VERSION ""

NS_ :

BS_:
BU_: GW BMS GPEU PCU RPEU PDU EMS TMS RPEU OBC GPEU PDU ReservedID19 ReservedID20 BDC  TMS Tester

BO_ 1601 BMS_641: 64 BMS
 SG_ BMS_CellU32 : 503|16@0+ (0.0010000000,0.0000000000) [0.0000000000|18.0000000000] "V"  GW
 SG_ BMS_CellU31 : 487|16@0+ (0.0010000000,0.0000000000) [0.0000000000|18.0000000000] "V"  GW
 SG_ BMS_CellU30 : 471|16@0+ (0.0010000000,0.0000000000) [0.0000000000|18.0000000000] "V"  GW
 SG_ BMS_CellU29 : 455|16@0+ (0.0010000000,0.0000000000) [0.0000000000|18.0000000000] "V"  GW
 SG_ BMS_CellU28 : 439|16@0+ (0.0010000000,0.0000000000) [0.0000000000|18.0000000000] "V"  GW
 SG_ BMS_CellU27 : 423|16@0+ (0.0010000000,0.0000000000) [0.0000000000|18.0000000000] "V"  GW
 SG_ BMS_CellU26 : 407|16@0+ (0.0010000000,0.0000000000) [0.0000000000|18.0000000000] "V"  GW
 SG_ BMS_CellU25 : 391|16@0+ (0.0010000000,0.0000000000) [0.0000000000|18.0000000000] "V"  GW
 SG_ BMS_CellU24 : 375|16@0+ (0.0010000000,0.0000000000) [0.0000000000|18.0000000000] "V"  GW
 SG_ BMS_CellU23 : 359|16@0+ (0.0010000000,0.0000000000) [0.0000000000|18.0000000000] "V"  GW
 SG_ BMS_CellU22 : 343|16@0+ (0.0010000000,0.0000000000) [0.0000000000|18.0000000000] "V"  GW
 SG_ BMS_CellU21 : 327|16@0+ (0.0010000000,0.0000000000) [0.0000000000|18.0000000000] "V"  GW
 SG_ BMS_CellU20 : 311|16@0+ (0.0010000000,0.0000000000) [0.0000000000|18.0000000000] "V"  GW
 SG_ BMS_CellU19 : 295|16@0+ (0.0010000000,0.0000000000) [0.0000000000|18.0000000000] "V"  GW
 SG_ BMS_CellU18 : 279|16@0+ (0.0010000000,0.0000000000) [0.0000000000|18.0000000000] "V"  GW
 SG_ BMS_CellU17 : 263|16@0+ (0.0010000000,0.0000000000) [0.0000000000|18.0000000000] "V"  GW
 SG_ BMS_CellU16 : 247|16@0+ (0.0010000000,0.0000000000) [0.0000000000|18.0000000000] "V"  GW
 SG_ BMS_CellU15 : 231|16@0+ (0.0010000000,0.0000000000) [0.0000000000|18.0000000000] "V"  GW
 SG_ BMS_CellU14 : 215|16@0+ (0.0010000000,0.0000000000) [0.0000000000|18.0000000000] "V"  GW
 SG_ BMS_CellU13 : 199|16@0+ (0.0010000000,0.0000000000) [0.0000000000|18.0000000000] "V"  GW
 SG_ BMS_CellU9 : 135|16@0+ (0.0010000000,0.0000000000) [0.0000000000|18.0000000000] "V"  GW
 SG_ BMS_CellU12 : 183|16@0+ (0.0010000000,0.0000000000) [0.0000000000|18.0000000000] "V"  GW
 SG_ BMS_CellU11 : 167|16@0+ (0.0010000000,0.0000000000) [0.0000000000|18.0000000000] "V"  GW
 SG_ BMS_CellU10 : 151|16@0+ (0.0010000000,0.0000000000) [0.0000000000|18.0000000000] "V"  GW
 SG_ BMS_CellU8 : 119|16@0+ (0.0010000000,0.0000000000) [0.0000000000|18.0000000000] "V"  GW
 SG_ BMS_CellU7 : 103|16@0+ (0.0010000000,0.0000000000) [0.0000000000|18.0000000000] "V"  GW
 SG_ BMS_CellU6 : 87|16@0+ (0.0010000000,0.0000000000) [0.0000000000|18.0000000000] "V"  GW
 SG_ BMS_CellU5 : 71|16@0+ (0.0010000000,0.0000000000) [0.0000000000|18.0000000000] "V"  GW
 SG_ BMS_CellU4 : 55|16@0+ (0.0010000000,0.0000000000) [0.0000000000|18.0000000000] "V"  GW
 SG_ BMS_CellU3 : 39|16@0+ (0.0010000000,0.0000000000) [0.0000000000|18.0000000000] "V"  GW
 SG_ BMS_CellU2 : 23|16@0+ (0.0010000000,0.0000000000) [0.0000000000|18.0000000000] "V"  GW
 SG_ BMS_CellU1 : 7|16@0+ (0.0010000000,0.0000000000) [0.0000000000|18.0000000000] "V"  GW

BO_ 1609 BMS_649: 64 BMS
 SG_ BMS_CellU64 : 503|16@0+ (0.0010000000,0.0000000000) [0.0000000000|18.0000000000] "V"  GW
 SG_ BMS_CellU63 : 487|16@0+ (0.0010000000,0.0000000000) [0.0000000000|18.0000000000] "V"  GW
 SG_ BMS_CellU62 : 471|16@0+ (0.0010000000,0.0000000000) [0.0000000000|18.0000000000] "V"  GW
 SG_ BMS_CellU61 : 455|16@0+ (0.0010000000,0.0000000000) [0.0000000000|18.0000000000] "V"  GW
 SG_ BMS_CellU60 : 439|16@0+ (0.0010000000,0.0000000000) [0.0000000000|18.0000000000] "V"  GW
 SG_ BMS_CellU59 : 423|16@0+ (0.0010000000,0.0000000000) [0.0000000000|18.0000000000] "V"  GW
 SG_ BMS_CellU58 : 407|16@0+ (0.0010000000,0.0000000000) [0.0000000000|18.0000000000] "V"  GW
 SG_ BMS_CellU57 : 391|16@0+ (0.0010000000,0.0000000000) [0.0000000000|18.0000000000] "V"  GW
 SG_ BMS_CellU56 : 375|16@0+ (0.0010000000,0.0000000000) [0.0000000000|18.0000000000] "V"  GW
 SG_ BMS_CellU55 : 359|16@0+ (0.0010000000,0.0000000000) [0.0000000000|18.0000000000] "V"  GW
 SG_ BMS_CellU54 : 343|16@0+ (0.0010000000,0.0000000000) [0.0000000000|18.0000000000] "V"  GW
 SG_ BMS_CellU53 : 327|16@0+ (0.0010000000,0.0000000000) [0.0000000000|18.0000000000] "V"  GW
 SG_ BMS_CellU52 : 311|16@0+ (0.0010000000,0.0000000000) [0.0000000000|18.0000000000] "V"  GW
 SG_ BMS_CellU51 : 295|16@0+ (0.0010000000,0.0000000000) [0.0000000000|18.0000000000] "V"  GW
 SG_ BMS_CellU50 : 279|16@0+ (0.0010000000,0.0000000000) [0.0000000000|18.0000000000] "V"  GW
 SG_ BMS_CellU49 : 263|16@0+ (0.0010000000,0.0000000000) [0.0000000000|18.0000000000] "V"  GW
 SG_ BMS_CellU48 : 247|16@0+ (0.0010000000,0.0000000000) [0.0000000000|18.0000000000] "V"  GW
 SG_ BMS_CellU47 : 231|16@0+ (0.0010000000,0.0000000000) [0.0000000000|18.0000000000] "V"  GW
 SG_ BMS_CellU46 : 215|16@0+ (0.0010000000,0.0000000000) [0.0000000000|18.0000000000] "V"  GW
 SG_ BMS_CellU45 : 199|16@0+ (0.0010000000,0.0000000000) [0.0000000000|18.0000000000] "V"  GW
 SG_ BMS_CellU44 : 183|16@0+ (0.0010000000,0.0000000000) [0.0000000000|18.0000000000] "V"  GW
 SG_ BMS_CellU43 : 167|16@0+ (0.0010000000,0.0000000000) [0.0000000000|18.0000000000] "V"  GW
 SG_ BMS_CellU42 : 151|16@0+ (0.0010000000,0.0000000000) [0.0000000000|18.0000000000] "V"  GW
 SG_ BMS_CellU41 : 135|16@0+ (0.0010000000,0.0000000000) [0.0000000000|18.0000000000] "V"  GW
 SG_ BMS_CellU40 : 119|16@0+ (0.0010000000,0.0000000000) [0.0000000000|18.0000000000] "V"  GW
 SG_ BMS_CellU39 : 103|16@0+ (0.0010000000,0.0000000000) [0.0000000000|18.0000000000] "V"  GW
 SG_ BMS_CellU38 : 87|16@0+ (0.0010000000,0.0000000000) [0.0000000000|18.0000000000] "V"  GW
 SG_ BMS_CellU37 : 71|16@0+ (0.0010000000,0.0000000000) [0.0000000000|18.0000000000] "V"  GW
 SG_ BMS_CellU36 : 55|16@0+ (0.0010000000,0.0000000000) [0.0000000000|18.0000000000] "V"  GW
 SG_ BMS_CellU35 : 39|16@0+ (0.0010000000,0.0000000000) [0.0000000000|18.0000000000] "V"  GW
 SG_ BMS_CellU34 : 23|16@0+ (0.0010000000,0.0000000000) [0.0000000000|18.0000000000] "V"  GW
 SG_ BMS_CellU33 : 7|16@0+ (0.0010000000,0.0000000000) [0.0000000000|18.0000000000] "V"  GW

BO_ 1617 BMS_651: 64 BMS
 SG_ BMS_CellU96 : 503|16@0+ (0.0010000000,0.0000000000) [0.0000000000|18.0000000000] "V"  GW
 SG_ BMS_CellU95 : 487|16@0+ (0.0010000000,0.0000000000) [0.0000000000|18.0000000000] "V"  GW
 SG_ BMS_CellU94 : 471|16@0+ (0.0010000000,0.0000000000) [0.0000000000|18.0000000000] "V"  GW
 SG_ BMS_CellU93 : 455|16@0+ (0.0010000000,0.0000000000) [0.0000000000|18.0000000000] "V"  GW
 SG_ BMS_CellU92 : 439|16@0+ (0.0010000000,0.0000000000) [0.0000000000|18.0000000000] "V"  GW
 SG_ BMS_CellU91 : 423|16@0+ (0.0010000000,0.0000000000) [0.0000000000|18.0000000000] "V"  GW
 SG_ BMS_CellU90 : 407|16@0+ (0.0010000000,0.0000000000) [0.0000000000|18.0000000000] "V"  GW
 SG_ BMS_CellU89 : 391|16@0+ (0.0010000000,0.0000000000) [0.0000000000|18.0000000000] "V"  GW
 SG_ BMS_CellU88 : 375|16@0+ (0.0010000000,0.0000000000) [0.0000000000|18.0000000000] "V"  GW
 SG_ BMS_CellU87 : 359|16@0+ (0.0010000000,0.0000000000) [0.0000000000|18.0000000000] "V"  GW
 SG_ BMS_CellU86 : 343|16@0+ (0.0010000000,0.0000000000) [0.0000000000|18.0000000000] "V"  GW
 SG_ BMS_CellU85 : 327|16@0+ (0.0010000000,0.0000000000) [0.0000000000|18.0000000000] "V"  GW
 SG_ BMS_CellU84 : 311|16@0+ (0.0010000000,0.0000000000) [0.0000000000|18.0000000000] "V"  GW
 SG_ BMS_CellU83 : 295|16@0+ (0.0010000000,0.0000000000) [0.0000000000|18.0000000000] "V"  GW
 SG_ BMS_CellU82 : 279|16@0+ (0.0010000000,0.0000000000) [0.0000000000|18.0000000000] "V"  GW
 SG_ BMS_CellU81 : 263|16@0+ (0.0010000000,0.0000000000) [0.0000000000|18.0000000000] "V"  GW
 SG_ BMS_CellU80 : 247|16@0+ (0.0010000000,0.0000000000) [0.0000000000|18.0000000000] "V"  GW
 SG_ BMS_CellU79 : 231|16@0+ (0.0010000000,0.0000000000) [0.0000000000|18.0000000000] "V"  GW
 SG_ BMS_CellU78 : 215|16@0+ (0.0010000000,0.0000000000) [0.0000000000|18.0000000000] "V"  GW
 SG_ BMS_CellU77 : 199|16@0+ (0.0010000000,0.0000000000) [0.0000000000|18.0000000000] "V"  GW
 SG_ BMS_CellU76 : 183|16@0+ (0.0010000000,0.0000000000) [0.0000000000|18.0000000000] "V"  GW
 SG_ BMS_CellU75 : 167|16@0+ (0.0010000000,0.0000000000) [0.0000000000|18.0000000000] "V"  GW
 SG_ BMS_CellU74 : 151|16@0+ (0.0010000000,0.0000000000) [0.0000000000|18.0000000000] "V"  GW
 SG_ BMS_CellU73 : 135|16@0+ (0.0010000000,0.0000000000) [0.0000000000|18.0000000000] "V"  GW
 SG_ BMS_CellU72 : 119|16@0+ (0.0010000000,0.0000000000) [0.0000000000|18.0000000000] "V"  GW
 SG_ BMS_CellU71 : 103|16@0+ (0.0010000000,0.0000000000) [0.0000000000|18.0000000000] "V"  GW
 SG_ BMS_CellU70 : 87|16@0+ (0.0010000000,0.0000000000) [0.0000000000|18.0000000000] "V"  GW
 SG_ BMS_CellU69 : 71|16@0+ (0.0010000000,0.0000000000) [0.0000000000|18.0000000000] "V"  GW
 SG_ BMS_CellU68 : 55|16@0+ (0.0010000000,0.0000000000) [0.0000000000|18.0000000000] "V"  GW
 SG_ BMS_CellU67 : 39|16@0+ (0.0010000000,0.0000000000) [0.0000000000|18.0000000000] "V"  GW
 SG_ BMS_CellU66 : 23|16@0+ (0.0010000000,0.0000000000) [0.0000000000|18.0000000000] "V"  GW
 SG_ BMS_CellU65 : 7|16@0+ (0.0010000000,0.0000000000) [0.0000000000|18.0000000000] "V"  GW

BO_ 1653 BMS_675: 64 BMS
 SG_ BMS_ModT60 : 479|8@0+ (1.0000000000,-40.0000000000) [-40.0000000000|125.0000000000] "��"  GW
 SG_ BMS_ModT59 : 471|8@0+ (1.0000000000,-40.0000000000) [-40.0000000000|125.0000000000] "��"  GW
 SG_ BMS_ModT58 : 463|8@0+ (1.0000000000,-40.0000000000) [-40.0000000000|125.0000000000] "��"  GW
 SG_ BMS_ModT57 : 455|8@0+ (1.0000000000,-40.0000000000) [-40.0000000000|125.0000000000] "��"  GW
 SG_ BMS_ModT56 : 447|8@0+ (1.0000000000,-40.0000000000) [-40.0000000000|125.0000000000] "��"  GW
 SG_ BMS_ModT55 : 439|8@0+ (1.0000000000,-40.0000000000) [-40.0000000000|125.0000000000] "��"  GW
 SG_ BMS_ModT54 : 431|8@0+ (1.0000000000,-40.0000000000) [-40.0000000000|125.0000000000] "��"  GW
 SG_ BMS_ModT53 : 423|8@0+ (1.0000000000,-40.0000000000) [-40.0000000000|125.0000000000] "��"  GW
 SG_ BMS_ModT52 : 415|8@0+ (1.0000000000,-40.0000000000) [-40.0000000000|125.0000000000] "��"  GW
 SG_ BMS_ModT51 : 407|8@0+ (1.0000000000,-40.0000000000) [-40.0000000000|125.0000000000] "��"  GW
 SG_ BMS_ModT50 : 399|8@0+ (1.0000000000,-40.0000000000) [-40.0000000000|125.0000000000] "��"  GW
 SG_ BMS_ModT49 : 391|8@0+ (1.0000000000,-40.0000000000) [-40.0000000000|125.0000000000] "��"  GW
 SG_ BMS_ModT48 : 383|8@0+ (1.0000000000,-40.0000000000) [-40.0000000000|125.0000000000] "��"  GW
 SG_ BMS_ModT47 : 375|8@0+ (1.0000000000,-40.0000000000) [-40.0000000000|125.0000000000] "��"  GW
 SG_ BMS_ModT46 : 367|8@0+ (1.0000000000,-40.0000000000) [-40.0000000000|125.0000000000] "��"  GW
 SG_ BMS_ModT45 : 359|8@0+ (1.0000000000,-40.0000000000) [-40.0000000000|125.0000000000] "��"  GW
 SG_ BMS_ModT44 : 351|8@0+ (1.0000000000,-40.0000000000) [-40.0000000000|125.0000000000] "��"  GW
 SG_ BMS_ModT43 : 343|8@0+ (1.0000000000,-40.0000000000) [-40.0000000000|125.0000000000] "��"  GW
 SG_ BMS_ModT42 : 335|8@0+ (1.0000000000,-40.0000000000) [-40.0000000000|125.0000000000] "��"  GW
 SG_ BMS_ModT41 : 327|8@0+ (1.0000000000,-40.0000000000) [-40.0000000000|125.0000000000] "��"  GW
 SG_ BMS_ModT40 : 319|8@0+ (1.0000000000,-40.0000000000) [-40.0000000000|125.0000000000] "��"  GW
 SG_ BMS_ModT39 : 311|8@0+ (1.0000000000,-40.0000000000) [-40.0000000000|125.0000000000] "��"  GW
 SG_ BMS_ModT38 : 303|8@0+ (1.0000000000,-40.0000000000) [-40.0000000000|125.0000000000] "��"  GW
 SG_ BMS_ModT37 : 295|8@0+ (1.0000000000,-40.0000000000) [-40.0000000000|125.0000000000] "��"  GW
 SG_ BMS_ModT36 : 287|8@0+ (1.0000000000,-40.0000000000) [-40.0000000000|125.0000000000] "��"  GW
 SG_ BMS_ModT35 : 279|8@0+ (1.0000000000,-40.0000000000) [-40.0000000000|125.0000000000] "��"  GW
 SG_ BMS_ModT34 : 271|8@0+ (1.0000000000,-40.0000000000) [-40.0000000000|125.0000000000] "��"  GW
 SG_ BMS_ModT33 : 263|8@0+ (1.0000000000,-40.0000000000) [-40.0000000000|125.0000000000] "��"  GW
 SG_ BMS_ModT32 : 255|8@0+ (1.0000000000,-40.0000000000) [-40.0000000000|125.0000000000] "��"  GW
 SG_ BMS_ModT31 : 247|8@0+ (1.0000000000,-40.0000000000) [-40.0000000000|125.0000000000] "��"  GW
 SG_ BMS_ModT30 : 239|8@0+ (1.0000000000,-40.0000000000) [-40.0000000000|125.0000000000] "��"  GW
 SG_ BMS_ModT29 : 231|8@0+ (1.0000000000,-40.0000000000) [-40.0000000000|125.0000000000] "��"  GW
 SG_ BMS_ModT28 : 223|8@0+ (1.0000000000,-40.0000000000) [-40.0000000000|125.0000000000] "��"  GW
 SG_ BMS_ModT27 : 215|8@0+ (1.0000000000,-40.0000000000) [-40.0000000000|125.0000000000] "��"  GW
 SG_ BMS_ModT26 : 207|8@0+ (1.0000000000,-40.0000000000) [-40.0000000000|125.0000000000] "��"  GW
 SG_ BMS_ModT25 : 199|8@0+ (1.0000000000,-40.0000000000) [-40.0000000000|125.0000000000] "��"  GW
 SG_ BMS_ModT24 : 191|8@0+ (1.0000000000,-40.0000000000) [-40.0000000000|125.0000000000] "��"  GW
 SG_ BMS_ModT23 : 183|8@0+ (1.0000000000,-40.0000000000) [-40.0000000000|125.0000000000] "��"  GW
 SG_ BMS_ModT22 : 175|8@0+ (1.0000000000,-40.0000000000) [-40.0000000000|125.0000000000] "��"  GW
 SG_ BMS_ModT21 : 167|8@0+ (1.0000000000,-40.0000000000) [-40.0000000000|125.0000000000] "��"  GW
 SG_ BMS_ModT20 : 159|8@0+ (1.0000000000,-40.0000000000) [-40.0000000000|125.0000000000] "��"  GW
 SG_ BMS_ModT19 : 151|8@0+ (1.0000000000,-40.0000000000) [-40.0000000000|125.0000000000] "��"  GW
 SG_ BMS_ModT18 : 143|8@0+ (1.0000000000,-40.0000000000) [-40.0000000000|125.0000000000] "��"  GW
 SG_ BMS_ModT17 : 135|8@0+ (1.0000000000,-40.0000000000) [-40.0000000000|125.0000000000] "��"  GW
 SG_ BMS_ModT9 : 71|8@0+ (1.0000000000,-40.0000000000) [-40.0000000000|125.0000000000] "��"  GW
 SG_ BMS_ModT16 : 127|8@0+ (1.0000000000,-40.0000000000) [-40.0000000000|125.0000000000] "��"  GW
 SG_ BMS_ModT15 : 119|8@0+ (1.0000000000,-40.0000000000) [-40.0000000000|125.0000000000] "��"  GW
 SG_ BMS_ModT14 : 111|8@0+ (1.0000000000,-40.0000000000) [-40.0000000000|125.0000000000] "��"  GW
 SG_ BMS_ModT13 : 103|8@0+ (1.0000000000,-40.0000000000) [-40.0000000000|125.0000000000] "��"  GW
 SG_ BMS_ModT12 : 95|8@0+ (1.0000000000,-40.0000000000) [-40.0000000000|125.0000000000] "��"  GW
 SG_ BMS_ModT11 : 87|8@0+ (1.0000000000,-40.0000000000) [-40.0000000000|125.0000000000] "��"  GW
 SG_ BMS_ModT10 : 79|8@0+ (1.0000000000,-40.0000000000) [-40.0000000000|125.0000000000] "��"  GW
 SG_ BMS_ModT8 : 63|8@0+ (1.0000000000,-40.0000000000) [-40.0000000000|125.0000000000] "��"  GW
 SG_ BMS_ModT7 : 55|8@0+ (1.0000000000,-40.0000000000) [-40.0000000000|125.0000000000] "��"  GW
 SG_ BMS_ModT6 : 47|8@0+ (1.0000000000,-40.0000000000) [-40.0000000000|125.0000000000] "��"  GW
 SG_ BMS_ModT5 : 39|8@0+ (1.0000000000,-40.0000000000) [-40.0000000000|125.0000000000] "��"  GW
 SG_ BMS_ModT4 : 31|8@0+ (1.0000000000,-40.0000000000) [-40.0000000000|125.0000000000] "��"  GW
 SG_ BMS_ModT3 : 23|8@0+ (1.0000000000,-40.0000000000) [-40.0000000000|125.0000000000] "��"  GW
 SG_ BMS_ModT2 : 15|8@0+ (1.0000000000,-40.0000000000) [-40.0000000000|125.0000000000] "��"  GW
 SG_ BMS_ModT1 : 7|8@0+ (1.0000000000,-40.0000000000) [-40.0000000000|125.0000000000] "��"  GW

BO_ 378 GW_17A: 64 GW
 SG_ Wheel_Speed_RR_Data : 351|13@0+ (0.0562500000,0.0000000000) [0.0000000000|360.0000000000] "km/h"  RPEU
 SG_ Wheel_Speed_RL_Valid_Data : 354|1@0+ (1.0000000000,0.0000000000) [0.0000000000|1.0000000000] ""  RPEU
 SG_ Wheel_Speed_RL_Data : 353|13@0+ (0.0562500000,0.0000000000) [0.0000000000|360.0000000000] "km/h"  RPEU
 SG_ Wheel_Speed_RR_Valid_Data : 372|1@0+ (1.0000000000,0.0000000000) [0.0000000000|1.0000000000] ""  RPEU
 SG_ ESP_VDCActive : 245|1@0+ (1.0000000000,0.0000000000) [0.0000000000|1.0000000000] ""  RPEU
 SG_ ESP_TCSActive : 244|1@0+ (1.0000000000,0.0000000000) [0.0000000000|1.0000000000] ""  RPEU
 SG_ ESP_RollingCounter_17A : 491|4@0+ (1.0000000000,0.0000000000) [0.0000000000|15.0000000000] ""  PCU,PDCU
 SG_ ESP_CRCCheck_17A : 503|16@0+ (1.0000000000,0.0000000000) [0.0000000000|65535.0000000000] ""  PCU,PDCU
 SG_ ESP_ElectricBoostFailStatus : 54|2@0+ (1.0000000000,0.0000000000) [0.0000000000|3.0000000000] "" Vector__XXX
 SG_ ESP_MbRegenTarWhlTotalQlfr : 293|2@0+ (1.0000000000,0.0000000000) [0.0000000000|3.0000000000] ""  PCU,PDCU
 SG_ ESP_MbRegenTarWhlTotal : 291|16@0+ (1.0000000000,-32768.0000000000) [-32768.0000000000|32767.0000000000] "Nm"  PCU,PDCU
 SG_ ESP_RollerbenchType : 80|3@0+ (1.0000000000,0.0000000000) [0.0000000000|7.0000000000] ""  PCU,PDCU
 SG_ IBCU_BrakeFluid_Warning : 27|2@0+ (1.0000000000,0.0000000000) [0.0000000000|3.0000000000] "" Vector__XXX
 SG_ ESP_VehicleSpeedValid2 : 271|2@0+ (1.0000000000,0.0000000000) [0.0000000000|2.0000000000] "" Vector__XXX
 SG_ ESP_VehicleSpeedValid : 37|1@0+ (1.0000000000,0.0000000000) [0.0000000000|1.0000000000] ""  PCU,PDCU,DPEU,GPEU,OBC
 SG_ ESP_VehicleSpeed2 : 263|8@0+ (0.4000000000,0.0000000000) [0.0000000000|100.0000000000] "m/s" Vector__XXX
 SG_ ESP_VehicleSpeed : 36|13@0+ (0.0562500000,0.0000000000) [0.0000000000|360.0000000000] "km/h"  PCU,PDCU,OBC,DPEU,GPEU,BMS
 SG_ ESP_TqDecSlowwhlRear : 215|15@0+ (1.0000000000,-5400.0000000000) [-5400.0000000000|12000.0000000000] "Nm"  PCU,PDCU,RPEU
 SG_ ESP_TqDecSlowwhlFront : 136|15@0+ (1.0000000000,-5400.0000000000) [-5400.0000000000|12000.0000000000] "Nm"  PCU,PDCU
 SG_ ESP_TqDecFastwhlFront : 135|15@0+ (1.0000000000,-5400.0000000000) [-5400.0000000000|12000.0000000000] "Nm"  PCU,PDCU,DPEU
 SG_ ESP_TorqIncwhlRear : 199|15@0+ (1.0000000000,-5400.0000000000) [-5400.0000000000|12000.0000000000] "Nm"  PCU,PDCU,RPEU
 SG_ ESP_TorqIncwhlFront : 15|15@0+ (1.0000000000,-5400.0000000000) [-5400.0000000000|12000.0000000000] "Nm"  PCU,PDCU,DPEU
 SG_ ESP_TCSFailStatus : 4|1@0+ (1.0000000000,0.0000000000) [0.0000000000|1.0000000000] ""  PCU,PDCU,RPEU
 SG_ ESP_RollingCounter_1DF : 371|4@0+ (1.0000000000,0.0000000000) [0.0000000000|15.0000000000] "" Vector__XXX
 SG_ ESP_RollingCounter_1C8 : 243|4@0+ (1.0000000000,0.0000000000) [0.0000000000|15.0000000000] ""  PCU,PDCU
 SG_ ESP_RollingCounter_1AC : 179|4@0+ (1.0000000000,0.0000000000) [0.0000000000|15.0000000000] ""  PCU,PDCU
 SG_ ESP_RollingCounter_197 : 115|4@0+ (1.0000000000,0.0000000000) [0.0000000000|15.0000000000] ""  PCU,PDCU
 SG_ ESP_RollingCounter_187 : 51|4@0+ (1.0000000000,0.0000000000) [0.0000000000|15.0000000000] ""  PCU,PDCU
 SG_ ESP_pMcVirtual_Q : 333|2@0+ (1.0000000000,0.0000000000) [0.0000000000|2.0000000000] ""  PCU,PDCU
 SG_ ESP_pMcVirtual : 327|10@0+ (1.0000000000,0.0000000000) [0.0000000000|250.0000000000] "bar"  PCU,PDCU
 SG_ ESP_MbRegenTarWhlRearQlfr : 247|2@0+ (1.0000000000,0.0000000000) [0.0000000000|2.0000000000] ""  PCU,PDCU
 SG_ ESP_MbRegenTarWhlRear : 231|16@0+ (1.0000000000,-32768.0000000000) [-32768.0000000000|0.0000000000] "Nm"  PCU,PDCU
 SG_ ESP_MbRegenTarWhlFrontQlfr : 168|2@0+ (1.0000000000,0.0000000000) [0.0000000000|2.0000000000] ""  PCU,PDCU
 SG_ ESP_MbRegenTarWhlFront : 152|16@0+ (1.0000000000,-32768.0000000000) [-32768.0000000000|32767.0000000000] "Nm"  PCU,PDCU
 SG_ ESP_GearHoldRequestValid : 5|1@0+ (1.0000000000,0.0000000000) [0.0000000000|1.0000000000] ""  PCU,PDCU
 SG_ ESP_GearHoldRequest : 6|1@0+ (1.0000000000,0.0000000000) [0.0000000000|1.0000000000] ""  PCU,PDCU
 SG_ ESP_ESPFunctionStatus : 1|1@0+ (1.0000000000,0.0000000000) [0.0000000000|1.0000000000] ""  PCU,PDCU,RPEU
 SG_ ESP_ESPActiveStatus : 0|1@0+ (1.0000000000,0.0000000000) [0.0000000000|1.0000000000] ""  PCU,PDCU,RPEU
 SG_ ESP_EngTorqIncRearActive : 200|1@0+ (1.0000000000,0.0000000000) [0.0000000000|1.0000000000] ""  PCU,PDCU,RPEU
 SG_ ESP_EngTorqIncFrontActive : 38|1@0+ (1.0000000000,0.0000000000) [0.0000000000|1.0000000000] ""  PCU,PDCU,EMS,DPEU
 SG_ ESP_EngTorqDecRearActive : 216|1@0+ (1.0000000000,0.0000000000) [0.0000000000|1.0000000000] ""  PCU,PDCU,RPEU
 SG_ ESP_EngTorqDecFrontActive : 153|1@0+ (1.0000000000,0.0000000000) [0.0000000000|1.0000000000] ""  PCU,PDCU,DPEU
 SG_ ESP_EBDFailStatus : 2|1@0+ (1.0000000000,0.0000000000) [0.0000000000|1.0000000000] ""  PCU,PDCU
 SG_ ESP_CRCCheck_1DF : 383|8@0+ (1.0000000000,0.0000000000) [0.0000000000|255.0000000000] "" Vector__XXX
 SG_ ESP_CRCCheck_1C8 : 255|8@0+ (1.0000000000,0.0000000000) [0.0000000000|255.0000000000] ""  PCU,PDCU
 SG_ ESP_CRCCheck_1AC : 191|8@0+ (1.0000000000,0.0000000000) [0.0000000000|255.0000000000] ""  PCU,PDCU
 SG_ ESP_CRCCheck_197 : 127|8@0+ (1.0000000000,0.0000000000) [0.0000000000|255.0000000000] ""  PCU,PDCU
 SG_ ESP_CRCCheck_187 : 63|8@0+ (1.0000000000,0.0000000000) [0.0000000000|255.0000000000] ""  PCU,PDCU
 SG_ ESP_ADBF_Active : 52|1@0+ (1.0000000000,0.0000000000) [0.0000000000|1.0000000000] ""  PCU,PDCU
 SG_ ESP_ABSFailStatus : 3|1@0+ (1.0000000000,0.0000000000) [0.0000000000|1.0000000000] ""  PCU,PDCU
 SG_ ESP_ABSActiveStatus : 7|1@0+ (1.0000000000,0.0000000000) [0.0000000000|1.0000000000] ""  PCU,PDCU
 SG_ EPBi_MILReq : 55|1@0+ (1.0000000000,0.0000000000) [0.0000000000|1.0000000000] ""  PCU,PDCU
 SG_ EPBi_ClearDiagnosticInfo : 25|2@0+ (1.0000000000,0.0000000000) [0.0000000000|3.0000000000] "" Vector__XXX

BO_ 380 EMS_17C: 32 EMS
 SG_ EMS_S58XGAPS : 231|6@0+ (1.0000000000,0.0000000000) [1.0000000000|63.0000000000] ""  EMS,PDCU,GW,DPEU,GPEU
 SG_ EMS_AntiJerkActive : 53|1@0+ (1.0000000000,0.0000000000) [0.0000000000|1.0000000000] ""  EMS,PDCU,PCU,GW
 SG_ EMS_RollingCounter_17C : 235|4@0+ (1.0000000000,0.0000000000) [0.0000000000|15.0000000000] ""  GW,EMS,PDCU,PCU
 SG_ EMS_CRCCheck_17C : 247|16@0+ (1.0000000000,0.0000000000) [0.0000000000|65535.0000000000] ""  GW,EMS,PDCU,PCU
 SG_ EMS_RollingCounter_1B7 : 179|4@0+ (1.0000000000,0.0000000000) [0.0000000000|15.0000000000] ""  EMS,PDCU,PCU
 SG_ EMS_RngMod_trqCrSSetMinAvl : 153|10@0+ (1.0000000000,-350.0000000000) [-350.0000000000|400.0000000000] "Nm"  EMS,PDCU,PCU
 SG_ EMS_RngMod_trqCrSSetMaxAvl : 147|10@0+ (1.0000000000,-350.0000000000) [-350.0000000000|400.0000000000] "Nm"  EMS,PDCU,PCU
 SG_ EMS_RngMod_trqCrSLeadMinAvl : 141|10@0+ (1.0000000000,-350.0000000000) [-350.0000000000|400.0000000000] "Nm"  EMS,PDCU,PCU
 SG_ EMS_RngMod_trqCrSLeadMaxAvl : 135|10@0+ (1.0000000000,-350.0000000000) [-350.0000000000|400.0000000000] "Nm"  EMS,PDCU,PCU
 SG_ EMS_EngIdleTqFlywhMin : 175|10@0+ (1.0000000000,-350.0000000000) [-350.0000000000|400.0000000000] "Nm"  EMS,PDCU,PCU
 SG_ EMS_CRCCheck_1B7 : 191|8@0+ (1.0000000000,0.0000000000) [0.0000000000|255.0000000000] ""  EMS,PDCU,PCU
 SG_ EMS_RollingCounter_194 : 115|4@0+ (1.0000000000,0.0000000000) [0.0000000000|15.0000000000] ""  EMS,PDCU,PCU,GW
 SG_ EMS_IGNKL15Posn : 117|1@0+ (1.0000000000,0.0000000000) [0.0000000000|1.0000000000] ""  EMS,PDCU,GW
 SG_ EMS_IdleCtrlSts : 86|1@0+ (1.0000000000,0.0000000000) [0.0000000000|1.0000000000] ""  EMS,PDCU,PCU,GW,DPEU,GPEU
 SG_ EMS_EngTqFlywhFailr : 104|1@0+ (1.0000000000,0.0000000000) [0.0000000000|1.0000000000] ""  EMS,PDCU,PCU,GW,DPEU,GPEU
 SG_ EMS_EngTqFlywh : 88|16@0+ (0.0200000000,-350.0000000000) [-350.0000000000|400.0000000000] "Nm"  EMS,PDCU,PCU,GW,DPEU,GPEU
 SG_ EMS_EngSts : 119|2@0+ (1.0000000000,0.0000000000) [0.0000000000|3.0000000000] ""  EMS,PDCU,GW,PCU,DPEU,GPEU,TMS,BDC
 SG_ EMS_EngStrtSuccess : 90|1@0+ (1.0000000000,0.0000000000) [0.0000000000|1.0000000000] ""  EMS,PDCU,PCU,GW
 SG_ EMS_EngStopInhb : 93|3@0+ (1.0000000000,0.0000000000) [0.0000000000|3.0000000000] ""  EMS,PDCU,PCU,GW
 SG_ EMS_EngSpdErr : 71|1@0+ (1.0000000000,0.0000000000) [0.0000000000|1.0000000000] ""  EMS,PDCU,PCU,GW,BMS,RPEU,TMS,BDC
 SG_ EMS_EngSpd : 70|16@0+ (0.2500000000,0.0000000000) [0.0000000000|16383.5000000000] "Rpm"  EMS,PDCU,PCU,GW,BMS,DPEU,GPEU,RPEU,OBC,TMS,BDC
 SG_ EMS_EngRunReq : 85|3@0+ (1.0000000000,0.0000000000) [0.0000000000|3.0000000000] ""  EMS,PDCU,PCU,GW
 SG_ EMS_EngFuPumpSts : 95|2@0+ (1.0000000000,0.0000000000) [0.0000000000|3.0000000000] ""  EMS,PDCU,PCU,GW
 SG_ EMS_EngFuCutOff : 89|1@0+ (1.0000000000,0.0000000000) [0.0000000000|1.0000000000] ""  EMS,PDCU,PCU,GW
 SG_ EMS_CRCCheck_194 : 127|8@0+ (1.0000000000,0.0000000000) [0.0000000000|255.0000000000] ""  EMS,PDCU,PCU,GW
 SG_ EMS_RollingCounter_186 : 51|4@0+ (1.0000000000,0.0000000000) [0.0000000000|15.0000000000] ""  EMS,PDCU,PCU,GW
 SG_ EMS_EngTqLimitedFlag : 52|1@0+ (1.0000000000,0.0000000000) [0.0000000000|1.0000000000] ""  EMS,PDCU,PCU,GW
 SG_ EMS_RngMod_trqCrSLimtSts : 32|1@0+ (1.0000000000,0.0000000000) [0.0000000000|1.0000000000] ""  EMS,PDCU,PCU,GW
 SG_ EMS_RngMod_trqCrSLeadMin : 26|10@0+ (1.0000000000,-350.0000000000) [-350.0000000000|400.0000000000] "Nm"  EMS,PDCU,PCU,GW
 SG_ EMS_InterCoolerMotLopPumpSpdReq : 13|7@0+ (1.0000000000,0.0000000000) [0.0000000000|100.0000000000] "%"  EMS,PDCU,GW,TMS,IBCMR,BDC
 SG_ EMS_IdleSpdRef : 7|10@0+ (10.0000000000,0.0000000000) [0.0000000000|10220.0000000000] "rpm"  EMS,PDCU,PCU,GW
 SG_ EMS_EngTqFric : 22|12@0+ (0.1000000000,0.0000000000) [0.0000000000|409.4000000000] "Nm"  EMS,PDCU,PCU,GW
 SG_ EMS_EngIdleTqFlywh : 47|10@0+ (1.0000000000,-350.0000000000) [-350.0000000000|400.0000000000] "Nm"  EMS,PDCU,PCU,GW
 SG_ EMS_CRCCheck_186 : 63|8@0+ (1.0000000000,0.0000000000) [0.0000000000|255.0000000000] ""  EMS,PDCU,PCU,GW

BO_ 381 PCU_17D: 64 PCU
 SG_ PCU_MbRegenWhlTotalVld : 476|1@0+ (1.0000000000,0.0000000000) [0.0000000000|1.0000000000] ""  GW,PCU,PDCU
 SG_ PCU_MbRegenWhlTotal : 475|16@0+ (1.0000000000,-32768.0000000000) [-32768.0000000000|32767.0000000000] "Nm"  GW,PCU,PDCU
 SG_ PCU_VehWhlReqTqVld : 456|1@0+ (1.0000000000,0.0000000000) [0.0000000000|1.0000000000] ""  GW,PCU,PDCU
 SG_ PCU_VehWhlReqTq : 455|15@0+ (1.0000000000,-5400.0000000000) [-5400.0000000000|12000.0000000000] "Nm"  GW,PCU,PDCU
 SG_ PCU_ReWhlReqTqVld : 468|1@0+ (1.0000000000,0.0000000000) [0.0000000000|1.0000000000] ""  GW,PCU,PDCU
 SG_ PCU_FrntWhlReqTqVld : 469|1@0+ (1.0000000000,0.0000000000) [0.0000000000|1.0000000000] ""  GW,PCU,PDCU
 SG_ PCU_ReWhlActTqVld : 470|1@0+ (1.0000000000,0.0000000000) [0.0000000000|1.0000000000] ""  GW,PCU,PDCU
 SG_ PCU_FrntWhlActTqVld : 471|1@0+ (1.0000000000,0.0000000000) [0.0000000000|1.0000000000] ""  GW,PCU,PDCU
 SG_ PCU_MbRegenMaxRearWhlVld : 375|1@0+ (1.0000000000,0.0000000000) [0.0000000000|1.0000000000] ""  PCU,PDCU,GW
 SG_ PCU_EngTarSpdReqVld : 224|1@0+ (1.0000000000,0.0000000000) [0.0000000000|1.0000000000] ""  PCU,PDCU,EMS
 SG_ PCU_RollingCounter_17D : 491|4@0+ (1.0000000000,0.0000000000) [0.0000000000|15.0000000000] ""  GW,PCU,PDCU,EMS,BMS
 SG_ PCU_CRCCheck_17D : 503|16@0+ (1.0000000000,0.0000000000) [0.0000000000|65535.0000000000] ""  GW,PCU,PDCU,EMS,BMS
 SG_ PCU_RollingCounter_1C4 : 435|4@0+ (1.0000000000,0.0000000000) [0.0000000000|15.0000000000] ""  GW,PCU,PDCU
 SG_ PCU_RearMotSts : 408|1@0+ (1.0000000000,0.0000000000) [0.0000000000|1.0000000000] ""  GW,PCU,PDCU
 SG_ PCU_PwrIndcdRealTqRearWhl : 391|15@0+ (1.0000000000,-5400.0000000000) [-5400.0000000000|12000.0000000000] "Nm"  GW,PCU,PDCU,BDC
 SG_ PCU_PwrIndcdDrvrReqTqWhlRear : 392|15@0+ (1.0000000000,-5400.0000000000) [-5400.0000000000|12000.0000000000] "Nm"  GW,PCU,PDCU
 SG_ PCU_ESPTqReqAvlRear : 409|1@0+ (1.0000000000,0.0000000000) [0.0000000000|1.0000000000] ""  GW,PCU,PDCU
 SG_ PCU_CRCCheck_1C4 : 447|8@0+ (1.0000000000,0.0000000000) [0.0000000000|255.0000000000] ""  GW,PCU,PDCU
 SG_ PCU_RollingCounter_1BE : 371|4@0+ (1.0000000000,0.0000000000) [0.0000000000|15.0000000000] ""  GW,PCU,PDCU
 SG_ PCU_MbRegenWhlRear : 343|16@0+ (1.0000000000,-32768.0000000000) [-32768.0000000000|32767.0000000000] "Nm"  GW,PCU,PDCU
 SG_ PCU_MbRegenMaxWhlTotal : 327|16@0+ (1.0000000000,-32768.0000000000) [-32768.0000000000|32767.0000000000] "Nm"  GW,PCU,PDCU
 SG_ PCU_MbRegenMaxRearWhl : 359|16@0+ (1.0000000000,-32768.0000000000) [-32768.0000000000|32767.0000000000] "Nm"  GW,PCU,PDCU
 SG_ PCU_CRCCheck_1BE : 383|8@0+ (1.0000000000,0.0000000000) [0.0000000000|255.0000000000] ""  GW,PCU,PDCU
 SG_ PCU_PwrTrainSts : 311|2@0+ (1.0000000000,0.0000000000) [0.0000000000|3.0000000000] ""  GW,PCU,PDCU,EMS,TMS,BDC
 SG_ PCU_BrkPedlSts : 291|2@0+ (1.0000000000,0.0000000000) [0.0000000000|3.0000000000] ""  GW,PCU,PDCU,BDC
 SG_ PCU_RollingCounter_1A6 : 307|4@0+ (1.0000000000,0.0000000000) [0.0000000000|15.0000000000] ""  GW,PCU,PDCU
 SG_ PCU_MbRegenWhlFront : 263|16@0+ (1.0000000000,-32768.0000000000) [-32768.0000000000|32767.0000000000] "Nm"  GW,PCU,PDCU
 SG_ PCU_MbRegenMaxWhlQlfr : 293|2@0+ (1.0000000000,0.0000000000) [0.0000000000|2.0000000000] ""  GW,PCU,PDCU
 SG_ PCU_MbRegenMaxFrontWhlVld : 294|1@0+ (1.0000000000,0.0000000000) [0.0000000000|1.0000000000] ""  GW,PCU,PDCU
 SG_ PCU_MbRegenMaxFrontWhl : 279|16@0+ (1.0000000000,-32768.0000000000) [-32768.0000000000|32767.0000000000] "Nm"  GW,PCU,PDCU
 SG_ PCU_CRCCheck_1A6 : 319|8@0+ (1.0000000000,0.0000000000) [0.0000000000|255.0000000000] ""  GW,PCU,PDCU
 SG_ PCU_APATorqRequestAvailable : 289|1@0+ (1.0000000000,0.0000000000) [0.0000000000|1.0000000000] ""  PCU,PDCU,GW,BDC
 SG_ PCU_APARequestEnable : 309|2@0+ (1.0000000000,0.0000000000) [0.0000000000|3.0000000000] ""  PCU,PDCU,GW,BDC
 SG_ PCU_AccPedlVld : 288|1@0+ (1.0000000000,0.0000000000) [0.0000000000|1.0000000000] ""  GW,PCU,PDCU,BDC
 SG_ PCU_AccPedl : 303|8@0+ (0.3920000000,0.0000000000) [0.0000000000|99.9600000000] "pct"  GW,PCU,PDCU,BDC
 SG_ PCU_StartStopActiveVld : 234|1@0+ (1.0000000000,0.0000000000) [0.0000000000|1.0000000000] ""  PCU,PDCU,GW
 SG_ PCU_StartStopActive : 235|1@0+ (1.0000000000,0.0000000000) [0.0000000000|1.0000000000] ""  PCU,PDCU,GW
 SG_ PCU_RollingCounter_211 : 243|4@0+ (1.0000000000,0.0000000000) [0.0000000000|15.0000000000] ""  PCU,PDCU,GW
 SG_ PCU_RearMotStsVld : 236|1@0+ (1.0000000000,0.0000000000) [0.0000000000|1.0000000000] ""  PCU,PDCU,GW
 SG_ PCU_QECACC : 230|2@0+ (1.0000000000,0.0000000000) [0.0000000000|3.0000000000] ""  PCU,PDCU,GW
 SG_ PCU_PwrIndcdRealTqWhlFailr : 225|1@0+ (1.0000000000,0.0000000000) [0.0000000000|1.0000000000] ""  PCU,PDCU,GW
 SG_ PCU_PwrIndcdRealTqFrontWhl : 199|15@0+ (1.0000000000,-5400.0000000000) [-5400.0000000000|12000.0000000000] "Nm"  PCU,PDCU,GW,BDC
 SG_ PCU_PwrIndcdDrvrReqTqWhlFront : 200|15@0+ (1.0000000000,-5400.0000000000) [-5400.0000000000|12000.0000000000] "Nm"  PCU,PDCU,GW
 SG_ PCU_FrontMotStsVld : 239|1@0+ (1.0000000000,0.0000000000) [0.0000000000|1.0000000000] ""  PCU,PDCU,GW
 SG_ PCU_FrontMotSts : 217|1@0+ (1.0000000000,0.0000000000) [0.0000000000|1.0000000000] ""  PCU,PDCU,GW
 SG_ PCU_ESPTqReqAvlFront : 216|1@0+ (1.0000000000,0.0000000000) [0.0000000000|1.0000000000] ""  PCU,PDCU,GW
 SG_ PCU_EngStsVld : 238|1@0+ (1.0000000000,0.0000000000) [0.0000000000|1.0000000000] ""  PCU,PDCU,GW
 SG_ PCU_EngSts : 227|1@0+ (1.0000000000,0.0000000000) [0.0000000000|1.0000000000] ""  PCU,PDCU,GW
 SG_ PCU_EngClutchStsVld : 237|1@0+ (1.0000000000,0.0000000000) [0.0000000000|1.0000000000] ""  PCU,PDCU,GW
 SG_ PCU_EngClutchSts : 226|1@0+ (1.0000000000,0.0000000000) [0.0000000000|1.0000000000] ""  PCU,PDCU,GW
 SG_ PCU_ECGPOvrd : 231|1@0+ (1.0000000000,0.0000000000) [0.0000000000|1.0000000000] ""  PCU,PDCU,GW
 SG_ PCU_CRCCheck_211 : 255|8@0+ (1.0000000000,0.0000000000) [0.0000000000|255.0000000000] ""  PCU,PDCU,GW
 SG_ PCU_AccReqPossible : 228|1@0+ (1.0000000000,0.0000000000) [0.0000000000|1.0000000000] ""  PCU,PDCU,GW
 SG_ RGearbox_ActualDrivingGear : 110|2@0+ (1.0000000000,0.0000000000) [0.0000000000|3.0000000000] ""  GW,PCU,PDCU
 SG_ PCU_TrsmTarIdleSpdReq : 108|9@0+ (10.0000000000,0.0000000000) [0.0000000000|5110.0000000000] "rpm"  PCU,PDCU,GW
 SG_ PCU_TarGearReqValid : 111|1@0+ (1.0000000000,0.0000000000) [0.0000000000|1.0000000000] ""  GW,PCU,PDCU
 SG_ PCU_TarGearReq : 99|4@0+ (1.0000000000,0.0000000000) [0.0000000000|15.0000000000] ""  GW,PCU,PDCU,EMS
 SG_ PCU_SpdCtrlModSelect : 88|2@0+ (1.0000000000,0.0000000000) [0.0000000000|3.0000000000] ""  PCU,PDCU,EMS,GW
 SG_ PCU_RollingCounter_1C6 : 115|4@0+ (1.0000000000,0.0000000000) [0.0000000000|15.0000000000] ""  PCU,PDCU,EMS,GW
 SG_ PCU_RealAccPedlVld : 79|1@0+ (1.0000000000,0.0000000000) [0.0000000000|1.0000000000] ""  PCU,PDCU,EMS,GW,BDC
 SG_ PCU_RealAccPedl : 71|8@0+ (0.3920000000,0.0000000000) [0.0000000000|99.9600000000] "%"  PCU,PDCU,EMS,GW,BDC
 SG_ PCU_MILReq : 100|1@0+ (1.0000000000,0.0000000000) [0.0000000000|1.0000000000] ""  PCU,PDCU,EMS,GW
 SG_ PCU_K3CluSts : 78|1@0+ (1.0000000000,0.0000000000) [0.0000000000|1.0000000000] ""  PCU,PDCU,EMS,GW
 SG_ PCU_FlywhTqTransLoadActInvld : 77|1@0+ (1.0000000000,0.0000000000) [0.0000000000|1.0000000000] ""  PCU,PDCU,EMS,GW
 SG_ PCU_FlywhTqTransLoadAct : 76|8@0+ (1.0000000000,0.0000000000) [0.0000000000|254.0000000000] "Nm"  PCU,PDCU,EMS,GW
 SG_ PCU_EngTarIdleSpdReq : 84|9@0+ (10.0000000000,0.0000000000) [0.0000000000|5110.0000000000] "rpm"  PCU,PDCU,EMS,GW
 SG_ PCU_EngStrtMod : 91|3@0+ (1.0000000000,0.0000000000) [0.0000000000|7.0000000000] ""  PCU,PDCU,EMS,GW
 SG_ PCU_CRCCheck_1C6 : 127|8@0+ (1.0000000000,0.0000000000) [0.0000000000|255.0000000000] ""  PCU,PDCU,EMS,GW
 SG_ PCU_ClrDiagcInfo : 102|2@0+ (1.0000000000,0.0000000000) [0.0000000000|3.0000000000] ""  PCU,PDCU,EMS,GW
 SG_ PCU_StrtTrqCtl : 182|1@0+ (1.0000000000,0.0000000000) [0.0000000000|1.0000000000] ""  PCU,EMS,PDCU
 SG_ PCU_StrtInhb : 183|1@0+ (1.0000000000,0.0000000000) [0.0000000000|1.0000000000] ""  PCU,EMS,PDCU
 SG_ PCU_RollingCounter_1E1 : 179|4@0+ (1.0000000000,0.0000000000) [0.0000000000|15.0000000000] ""  PCU,EMS,PDCU
 SG_ PCU_PtStsChrgCrp : 135|2@0+ (1.0000000000,0.0000000000) [0.0000000000|3.0000000000] ""  PCU,EMS,PDCU
 SG_ PCU_FuCutOffReq : 153|1@0+ (1.0000000000,0.0000000000) [0.0000000000|1.0000000000] ""  PCU,EMS,PDCU
 SG_ PCU_EngIgnAgIntvEnbl : 169|1@0+ (1.0000000000,0.0000000000) [0.0000000000|1.0000000000] ""  PCU,EMS,PDCU
 SG_ PCU_EngTqFlywhSlowReq : 151|13@0+ (0.1000000000,-350.0000000000) [-350.0000000000|400.0000000000] "Nm"  PCU,PDCU,EMS,DPEU
 SG_ PCU_EngTqFlywhReqVld : 133|1@0+ (1.0000000000,0.0000000000) [0.0000000000|1.0000000000] ""  PCU,PDCU,EMS,DPEU
 SG_ PCU_EngTqFlywhFastReq : 132|13@0+ (0.1000000000,-350.0000000000) [-350.0000000000|400.0000000000] "Nm"  PCU,PDCU,EMS,DPEU
 SG_ PCU_EngTqFlywhAllwdMaxVld : 152|1@0+ (1.0000000000,0.0000000000) [0.0000000000|1.0000000000] ""  PCU,PDCU,EMS
 SG_ PCU_EngTqFlywhAllwdMax : 167|13@0+ (0.1000000000,-350.0000000000) [-350.0000000000|400.0000000000] "Nm"  PCU,EMS,PDCU
 SG_ PCU_EngStrtOrd : 180|1@0+ (1.0000000000,0.0000000000) [0.0000000000|1.0000000000] ""  PCU,EMS,PDCU
 SG_ PCU_EngStpOrd : 181|1@0+ (1.0000000000,0.0000000000) [0.0000000000|1.0000000000] ""  PCU,EMS,PDCU
 SG_ PCU_EMSSurgeDamperEna : 168|1@0+ (1.0000000000,0.0000000000) [0.0000000000|1.0000000000] ""  PCU,EMS,PDCU
 SG_ PCU_CRCCheck_1E1 : 191|8@0+ (1.0000000000,0.0000000000) [0.0000000000|255.0000000000] ""  PCU,EMS,PDCU
 SG_ PCU_BrkPedlSts2 : 170|1@0+ (1.0000000000,0.0000000000) [0.0000000000|1.0000000000] ""  PCU,EMS,PDCU
 SG_ PCU_BrkPedlSts1 : 154|1@0+ (1.0000000000,0.0000000000) [0.0000000000|1.0000000000] ""  PCU,EMS,PDCU
 SG_ PCU_VehSts : 8|3@0+ (1.0000000000,0.0000000000) [0.0000000000|7.0000000000] ""  PCU,PDCU,BMS
 SG_ PCU_VehSpdVld : 44|1@0+ (1.0000000000,0.0000000000) [0.0000000000|1.0000000000] ""  PCU,PDCU,BMS
 SG_ PCU_VehSpd : 43|8@0+ (1.0000000000,0.0000000000) [0.0000000000|254.0000000000] "km/h"  PCU,PDCU,BMS
 SG_ PCU_SOCDisp : 15|7@0+ (1.0000000000,0.0000000000) [0.0000000000|100.0000000000] "%"  PCU,PDCU,BMS
 SG_ PCU_CRCID191 : 63|8@0+ (1.0000000000,0.0000000000) [0.0000000000|255.0000000000] ""  PCU,PDCU,BMS
 SG_ PCU_ChrgUnlckILimReq : 29|1@0+ (1.0000000000,0.0000000000) [0.0000000000|1.0000000000] ""  PCU,PDCU,BMS
 SG_ PCU_ChrgSuspReq : 47|1@0+ (1.0000000000,0.0000000000) [0.0000000000|1.0000000000] ""  PCU,PDCU,BMS
 SG_ PCU_ChrgIReqLimFac : 26|2@0+ (1.0000000000,0.0000000000) [0.0000000000|3.0000000000] ""  PCU,PDCU,BMS
 SG_ PCU_ChrgAllwd : 31|1@0+ (1.0000000000,0.0000000000) [0.0000000000|1.0000000000] ""  PCU,PDCU,BMS,OBC
 SG_ PCU_CHMAsignalSts : 27|1@0+ (1.0000000000,0.0000000000) [0.0000000000|1.0000000000] ""  PCU,PDCU,BMS
 SG_ PCU_BMSOperModReq : 21|3@0+ (1.0000000000,0.0000000000) [0.0000000000|6.0000000000] ""  PCU,PDCU,BMS,OBC
 SG_ PCU_BattIntrHeatAllwd : 30|1@0+ (1.0000000000,0.0000000000) [0.0000000000|1.0000000000] ""  PCU,PDCU,BMS
 SG_ PCU_ActHVPwrCnsExt : 7|8@0+ (0.1000000000,0.0000000000) [0.0000000000|25.5000000000] "kw"  PCU,PDCU,BMS
 SG_ PCU_191CycCntr : 51|4@0+ (1.0000000000,0.0000000000) [0.0000000000|15.0000000000] ""  PCU,PDCU,BMS

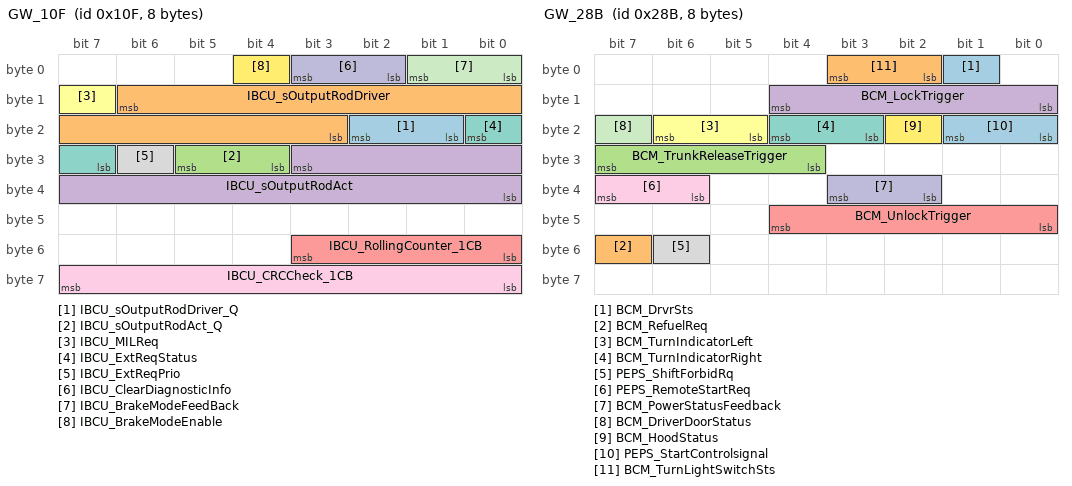
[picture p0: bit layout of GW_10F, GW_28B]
BO_ 271 GW_10F: 8 GW
 SG_ IBCU_sOutputRodDriver_Q : 18|2@0+ (1.0000000000,0.0000000000) [0.0000000000|2.0000000000] "" Vector__XXX
 SG_ IBCU_sOutputRodDriver : 14|12@0+ (0.0156250000,-5.0000000000) [-5.0000000000|47.0000000000] "mm" Vector__XXX
 SG_ IBCU_sOutputRodAct_Q : 29|2@0+ (1.0000000000,0.0000000000) [0.0000000000|3.0000000000] ""  PCU,PDCU
 SG_ IBCU_sOutputRodAct : 27|12@0+ (0.0156250000,-5.0000000000) [-5.0000000000|47.0000000000] "mm"  PCU,PDCU
 SG_ IBCU_RollingCounter_1CB : 51|4@0+ (1.0000000000,0.0000000000) [0.0000000000|15.0000000000] "" Vector__XXX
 SG_ IBCU_MILReq : 15|1@0+ (1.0000000000,0.0000000000) [0.0000000000|1.0000000000] ""  EMS,PCU,PDCU
 SG_ IBCU_ExtReqStatus : 16|2@0+ (1.0000000000,0.0000000000) [0.0000000000|2.0000000000] "" Vector__XXX
 SG_ IBCU_ExtReqPrio : 30|1@0+ (1.0000000000,0.0000000000) [0.0000000000|1.0000000000] "" Vector__XXX
 SG_ IBCU_CRCCheck_1CB : 63|8@0+ (1.0000000000,0.0000000000) [0.0000000000|255.0000000000] "" Vector__XXX
 SG_ IBCU_ClearDiagnosticInfo : 3|2@0+ (1.0000000000,0.0000000000) [0.0000000000|3.0000000000] ""  EMS,PDCU
 SG_ IBCU_BrakeModeFeedBack : 1|2@0+ (1.0000000000,0.0000000000) [0.0000000000|2.0000000000] "" Vector__XXX
 SG_ IBCU_BrakeModeEnable : 4|1@0+ (1.0000000000,0.0000000000) [0.0000000000|1.0000000000] "" Vector__XXX

BO_ 523 GW_20B: 64 GW
 SG_ IBCU_BrkPedlStsGbVld : 303|2@0+ (1.0000000000,0.0000000000) [0.0000000000|2.0000000000] ""  PCU,PDCU
 SG_ IBCU_BrkPedoplStsGb : 295|8@0+ (1.0000000000,0.0000000000) [0.0000000000|255.0000000000] "%"  PCU,PDCU
 SG_ ESP_RollingCounter_20B : 491|4@0+ (1.0000000000,0.0000000000) [0.0000000000|15.0000000000] ""  EMS,PCU,PDCU
 SG_ ESP_CRCCheck_20B : 503|16@0+ (1.0000000000,0.0000000000) [0.0000000000|65535.0000000000] ""  EMS,PCU,PDCU
 SG_ IBCU_DTCAvailable : 327|2@0+ (1.0000000000,0.0000000000) [0.0000000000|3.0000000000] ""  PCU,PDCU
 SG_ Wheel_Speed_FL_Pulse : 135|8@0+ (1.0000000000,0.0000000000) [0.0000000000|254.0000000000] "" Vector__XXX
 SG_ Wheel_Speed_FR_Pulse : 159|8@0+ (1.0000000000,0.0000000000) [0.0000000000|254.0000000000] "" Vector__XXX
 SG_ ESP_MasCylBraPreByDriver : 353|12@0+ (0.1000000000,0.0000000000) [0.0000000000|250.0000000000] "Bar"  PCU,PDCU
 SG_ ESP_MasCylBraPreByDriverValid : 372|1@0+ (1.0000000000,0.0000000000) [0.0000000000|1.0000000000] ""  PCU,PDCU
 SG_ ESP_Vehicle_Speed_Reference : 103|13@0+ (0.0562500000,0.0000000000) [0.0000000000|360.0000000000] "km/h" Vector__XXX
 SG_ IBCU_precheckStatus : 309|2@0+ (1.0000000000,0.0000000000) [0.0000000000|3.0000000000] "" Vector__XXX
 SG_ ESP_PrefillforAPA_Available : 280|1@0+ (1.0000000000,0.0000000000) [0.0000000000|1.0000000000] "" Vector__XXX
 SG_ ESP_PrefillforAPA_active : 281|1@0+ (1.0000000000,0.0000000000) [0.0000000000|1.0000000000] "" Vector__XXX
 SG_ IBCU_BrakeDiscHighTempWarning : 283|2@0+ (1.0000000000,0.0000000000) [0.0000000000|3.0000000000] "" Vector__XXX
 SG_ Wheel_SpeedPulseTimeStamp_FL : 167|16@0+ (0.0100000000,0.0000000000) [0.0000000000|655.3500000000] "ms" Vector__XXX
 SG_ Wheel_SpeedPulseTimeStamp_FR : 143|16@0+ (0.0100000000,0.0000000000) [0.0000000000|655.3500000000] "ms" Vector__XXX
 SG_ ESP_DTV_Available : 325|1@0+ (1.0000000000,0.0000000000) [0.0000000000|1.0000000000] "" Vector__XXX
 SG_ ESP_DTV_Active : 324|1@0+ (1.0000000000,0.0000000000) [0.0000000000|1.0000000000] "" Vector__XXX
 SG_ Wheel_Speed_RR_Pulse : 231|8@0+ (1.0000000000,0.0000000000) [0.0000000000|254.0000000000] "" Vector__XXX
 SG_ Wheel_Speed_RR_Direction : 70|2@0+ (1.0000000000,0.0000000000) [0.0000000000|3.0000000000] ""  PCU,PDCU
 SG_ Wheel_Speed_RR_Data : 68|13@0+ (0.0562500000,0.0000000000) [0.0000000000|360.0000000000] "km/h"  EMS,PCU,PDCU
 SG_ Wheel_Speed_RL_Valid_Data : 87|1@0+ (1.0000000000,0.0000000000) [0.0000000000|1.0000000000] ""  EMS,PCU,PDCU
 SG_ Wheel_Speed_RL_Pulse : 239|8@0+ (1.0000000000,0.0000000000) [0.0000000000|254.0000000000] "" Vector__XXX
 SG_ Wheel_Speed_RL_Direction : 86|2@0+ (1.0000000000,0.0000000000) [0.0000000000|3.0000000000] ""  PCU,PDCU
 SG_ Wheel_Speed_RL_Data : 84|13@0+ (0.0562500000,0.0000000000) [0.0000000000|360.0000000000] "km/h"  EMS,PCU,PDCU
 SG_ Wheel_Speed_FR_Valid_Data : 7|1@0+ (1.0000000000,0.0000000000) [0.0000000000|1.0000000000] ""  EMS,PCU,PDCU
 SG_ Wheel_Speed_FR_Pulse : 223|8@0+ (1.0000000000,0.0000000000) [0.0000000000|254.0000000000] "" Vector__XXX
 SG_ Wheel_Speed_FR_Direction : 6|2@0+ (1.0000000000,0.0000000000) [0.0000000000|3.0000000000] ""  PCU,PDCU
 SG_ Wheel_Speed_FR_Data : 4|13@0+ (0.0562500000,0.0000000000) [0.0000000000|360.0000000000] "km/h"  EMS,PCU,PDCU
 SG_ Wheel_Speed_FL_Valid_Data : 23|1@0+ (1.0000000000,0.0000000000) [0.0000000000|1.0000000000] ""  EMS,PCU,PDCU
 SG_ Wheel_Speed_FL_Direction : 22|2@0+ (1.0000000000,0.0000000000) [0.0000000000|3.0000000000] ""  PCU,PDCU
 SG_ Wheel_Speed_FL_Data : 20|13@0+ (0.0562500000,0.0000000000) [0.0000000000|360.0000000000] "km/h"  EMS,PCU,PDCU
 SG_ ESP_QDCACC : 279|2@0+ (1.0000000000,0.0000000000) [0.0000000000|3.0000000000] "" Vector__XXX
 SG_ ESP_MasCylBrakePressureValid : 199|1@0+ (1.0000000000,0.0000000000) [0.0000000000|1.0000000000] ""  PCU,PDCU
 SG_ ESP_MasCylBrakePressure : 195|12@0+ (0.1000000000,0.0000000000) [0.0000000000|250.0000000000] "Bar"  PCU,PDCU
 SG_ ESP_HHC_Available : 245|1@0+ (1.0000000000,0.0000000000) [0.0000000000|1.0000000000] ""  PCU,PDCU
 SG_ ESP_HHC_Active : 244|1@0+ (1.0000000000,0.0000000000) [0.0000000000|1.0000000000] ""  PCU,PDCU
 SG_ ESP_ECDAvailable : 116|1@0+ (1.0000000000,0.0000000000) [0.0000000000|1.0000000000] "" Vector__XXX
 SG_ ESP_ECDActive : 117|1@0+ (1.0000000000,0.0000000000) [0.0000000000|1.0000000000] ""  PCU,PDCU
 SG_ ESP_CRCCheck_208 : 127|8@0+ (1.0000000000,0.0000000000) [0.0000000000|255.0000000000] ""  PCU,PDCU
 SG_ ESP_CRCCheck_206 : 63|8@0+ (1.0000000000,0.0000000000) [0.0000000000|255.0000000000] ""  PCU,PDCU
 SG_ ESP_BrakeLightOnRequest : 197|2@0+ (1.0000000000,0.0000000000) [0.0000000000|3.0000000000] ""  PCU,PDCU
 SG_ ESP_AutoHoldStandby : 198|1@0+ (1.0000000000,0.0000000000) [0.0000000000|1.0000000000] ""  PCU,PDCU
 SG_ ESP_AutoHoldAvailable : 246|1@0+ (1.0000000000,0.0000000000) [0.0000000000|1.0000000000] ""  PCU,PDCU
 SG_ ESP_AutoHoldActive : 247|1@0+ (1.0000000000,0.0000000000) [0.0000000000|1.0000000000] ""  PCU,PDCU
 SG_ ABS_TODFastOpenRequest : 33|2@0+ (1.0000000000,0.0000000000) [0.0000000000|3.0000000000] "" Vector__XXX
 SG_ ESP_CDP_ParkingActiveForACC : 285|1@0+ (1.0000000000,0.0000000000) [0.0000000000|1.0000000000] "" Vector__XXX
 SG_ ESP_CDP_ParkingAvailForACC : 284|1@0+ (1.0000000000,0.0000000000) [0.0000000000|1.0000000000] "" Vector__XXX
 SG_ ESP_IncreasePressureReqOK : 275|1@0+ (1.0000000000,0.0000000000) [0.0000000000|1.0000000000] "NA" Vector__XXX
 SG_ ESP_OnlyABSActive : 264|1@0+ (1.0000000000,0.0000000000) [0.0000000000|1.0000000000] "" Vector__XXX
 SG_ ESP_TCSActive : 265|1@0+ (1.0000000000,0.0000000000) [0.0000000000|1.0000000000] "" Vector__XXX
 SG_ ESP_VDCActive : 266|1@0+ (1.0000000000,0.0000000000) [0.0000000000|1.0000000000] "" Vector__XXX
 SG_ ESP_HBBActiveStatus : 272|1@0+ (1.0000000000,0.0000000000) [0.0000000000|1.0000000000] "" Vector__XXX
 SG_ ESP_HDC_STATUS : 274|2@0+ (1.0000000000,0.0000000000) [0.0000000000|3.0000000000] ""  PCU,PDCU
 SG_ ESP_CDD_Available_APA : 276|1@0+ (1.0000000000,0.0000000000) [0.0000000000|1.0000000000] "NA" Vector__XXX
 SG_ ESP_CDD_Active_APA : 277|1@0+ (1.0000000000,0.0000000000) [0.0000000000|1.0000000000] "NA" Vector__XXX
 SG_ ESP_UrgencyBrakeAlarm : 118|1@0+ (1.0000000000,0.0000000000) [0.0000000000|1.0000000000] "" Vector__XXX
 SG_ Wheel_Speed_RR_Valid_Data : 71|1@0+ (1.0000000000,0.0000000000) [0.0000000000|1.0000000000] ""  EMS,PCU,PDCU
 SG_ ESP_RollingCounter_208 : 115|4@0+ (1.0000000000,0.0000000000) [0.0000000000|15.0000000000] ""  PCU,PDCU
 SG_ Wheel_Speed_FL_Pulse : 215|8@0+ (1.0000000000,0.0000000000) [0.0000000000|254.0000000000] "" Vector__XXX
 SG_ ESP_RollingCounter_258 : 243|4@0+ (1.0000000000,0.0000000000) [0.0000000000|15.0000000000] "" Vector__XXX
 SG_ ESP_CRCCheck_258 : 255|8@0+ (1.0000000000,0.0000000000) [0.0000000000|255.0000000000] "" Vector__XXX
 SG_ ESP_RollingCounter_206 : 51|4@0+ (1.0000000000,0.0000000000) [0.0000000000|15.0000000000] ""  PCU,PDCU
 SG_ ESP_CRCCheck_277 : 319|8@0+ (1.0000000000,0.0000000000) [0.0000000000|255.0000000000] ""  PCU,PDCU
 SG_ ESP_RollingCounter_277 : 307|4@0+ (1.0000000000,0.0000000000) [0.0000000000|15.0000000000] ""  PCU,PDCU
 SG_ ESP_VehicleStandstill : 267|1@0+ (1.0000000000,0.0000000000) [0.0000000000|1.0000000000] ""  PCU,PDCU
 SG_ ESP_PrefillAvailable : 259|1@0+ (1.0000000000,0.0000000000) [0.0000000000|1.0000000000] "" Vector__XXX
 SG_ ESP_PrefillActive : 260|1@0+ (1.0000000000,0.0000000000) [0.0000000000|1.0000000000] "" Vector__XXX
 SG_ ESP_BrakeForce : 263|1@0+ (1.0000000000,0.0000000000) [0.0000000000|1.0000000000] "" Vector__XXX
 SG_ ESP_CDD_Available : 268|1@0+ (1.0000000000,0.0000000000) [0.0000000000|1.0000000000] "" Vector__XXX
 SG_ ESP_CDD_Active : 269|1@0+ (1.0000000000,0.0000000000) [0.0000000000|1.0000000000] "" Vector__XXX
 SG_ ESP_BrakeOverHeatBrakeDiscTemp : 270|1@0+ (1.0000000000,0.0000000000) [0.0000000000|1.0000000000] "" Vector__XXX
 SG_ ESP_AWBavailable : 271|1@0+ (1.0000000000,0.0000000000) [0.0000000000|1.0000000000] "" Vector__XXX
 SG_ ESP_AWBactive : 256|1@0+ (1.0000000000,0.0000000000) [0.0000000000|1.0000000000] "" Vector__XXX
 SG_ ESP_AEBdecActive : 257|1@0+ (1.0000000000,0.0000000000) [0.0000000000|1.0000000000] "" Vector__XXX
 SG_ ESP_AEBAvailable : 258|1@0+ (1.0000000000,0.0000000000) [0.0000000000|1.0000000000] "" Vector__XXX
 SG_ ESP_ABAavailable : 261|1@0+ (1.0000000000,0.0000000000) [0.0000000000|1.0000000000] "" Vector__XXX
 SG_ ESP_ABAactive : 262|1@0+ (1.0000000000,0.0000000000) [0.0000000000|1.0000000000] "" Vector__XXX
 SG_ ESP_TODTorqueMaxLimit : 47|12@0+ (1.0000000000,0.0000000000) [0.0000000000|4094.0000000000] "NM" Vector__XXX

BO_ 651 GW_28B: 8 GW
 SG_ BCM_DrvrSts : 1|1@0+ (1.0000000000,0.0000000000) [0.0000000000|1.0000000000] ""  BMS,PCU,PDCU
 SG_ BCM_RefuelReq : 55|1@0+ (1.0000000000,0.0000000000) [0.0000000000|1.0000000000] "" Vector__XXX
 SG_ BCM_TrunkReleaseTrigger : 31|4@0+ (1.0000000000,0.0000000000) [0.0000000000|15.0000000000] "" Vector__XXX
 SG_ BCM_LockTrigger : 12|5@0+ (1.0000000000,0.0000000000) [0.0000000000|31.0000000000] ""  PCU,PDCU
 SG_ BCM_UnlockTrigger : 44|5@0+ (1.0000000000,0.0000000000) [0.0000000000|31.0000000000] ""  PCU,PDCU
 SG_ BCM_TurnIndicatorLeft : 22|2@0+ (1.0000000000,0.0000000000) [0.0000000000|3.0000000000] "" Vector__XXX
 SG_ BCM_TurnIndicatorRight : 20|2@0+ (1.0000000000,0.0000000000) [0.0000000000|3.0000000000] "" Vector__XXX
 SG_ PEPS_ShiftForbidRq : 54|1@0+ (1.0000000000,0.0000000000) [0.0000000000|1.0000000000] "" Vector__XXX
 SG_ PEPS_RemoteStartReq : 39|2@0+ (1.0000000000,0.0000000000) [0.0000000000|3.0000000000] ""  PCU,PDCU
 SG_ BCM_PowerStatusFeedback : 35|2@0+ (1.0000000000,0.0000000000) [0.0000000000|3.0000000000] ""  BMS,PCU,PDCU,DPEU,GPEU
 SG_ BCM_DriverDoorStatus : 23|1@0+ (1.0000000000,0.0000000000) [0.0000000000|1.0000000000] ""  EMS,PCU,PDCU
 SG_ BCM_HoodStatus : 18|1@0+ (1.0000000000,0.0000000000) [0.0000000000|1.0000000000] ""  PCU,PDCU
 SG_ PEPS_StartControlsignal : 17|2@0+ (1.0000000000,0.0000000000) [0.0000000000|3.0000000000] ""  EMS,PCU,PDCU
 SG_ BCM_TurnLightSwitchSts : 3|2@0+ (1.0000000000,0.0000000000) [0.0000000000|3.0000000000] "" Vector__XXX

BO_ 724 GW_2D4: 8 GW
 SG_ APA_RADSNotice : 44|6@0+ (1.0000000000,0.0000000000) [0.0000000000|63.0000000000] "" Vector__XXX
 SG_ APA_Right_BSD_LCAAlert : 54|2@0+ (1.0000000000,0.0000000000) [0.0000000000|3.0000000000] "" Vector__XXX
 SG_ APA_Left_BSD_LCAAlert : 39|2@0+ (1.0000000000,0.0000000000) [0.0000000000|3.0000000000] "" Vector__XXX
 SG_ APA_PEPS_EngineOffRequest : 52|1@0+ (1.0000000000,0.0000000000) [0.0000000000|1.0000000000] "" Vector__XXX
 SG_ APA_PowerMirrorFoldReq : 25|2@0+ (1.0000000000,0.0000000000) [0.0000000000|3.0000000000] "" Vector__XXX
 SG_ APA_LAEBReq : 7|1@0+ (1.0000000000,0.0000000000) [0.0000000000|1.0000000000] ""  EMS,PCU,PDCU
 SG_ APA_NumberofParkingSlot : 31|4@0+ (1.0000000000,0.0000000000) [0.0000000000|15.0000000000] "" Vector__XXX
 SG_ APA_ParkingModeAvailableSts : 27|2@0+ (1.0000000000,0.0000000000) [0.0000000000|3.0000000000] "" Vector__XXX
 SG_ APA_vehicleFrontdetect : 35|2@0+ (1.0000000000,0.0000000000) [0.0000000000|3.0000000000] "" Vector__XXX
 SG_ APA_BCMHornCommand : 33|2@0+ (1.0000000000,0.0000000000) [0.0000000000|3.0000000000] "" Vector__XXX
 SG_ APA_PEPS_EngineOffLockRequest : 37|1@0+ (1.0000000000,0.0000000000) [0.0000000000|1.0000000000] "" Vector__XXX
 SG_ APA_CrossModeSelectReq : 23|1@0+ (1.0000000000,0.0000000000) [0.0000000000|1.0000000000] "" Vector__XXX
 SG_ APA_ASPStatus : 22|2@0+ (1.0000000000,0.0000000000) [0.0000000000|3.0000000000] "" Vector__XXX
 SG_ APA_ASPAvailableStatus : 20|1@0+ (1.0000000000,0.0000000000) [0.0000000000|1.0000000000] "" Vector__XXX
 SG_ APA_RemoteParkingUsingRemind : 19|1@0+ (1.0000000000,0.0000000000) [0.0000000000|1.0000000000] "" Vector__XXX
 SG_ APA_BLEConnectionRemind : 15|1@0+ (1.0000000000,0.0000000000) [0.0000000000|1.0000000000] "" Vector__XXX
 SG_ APA_ReleasePressureReq : 36|1@0+ (1.0000000000,0.0000000000) [0.0000000000|1.0000000000] "" Vector__XXX
 SG_ APA_CRCCheck_2D4 : 63|8@0+ (1.0000000000,0.0000000000) [0.0000000000|255.0000000000] "" Vector__XXX
 SG_ APA_RollingCounter_2D4 : 51|4@0+ (1.0000000000,0.0000000000) [0.0000000000|15.0000000000] "" Vector__XXX
 SG_ APA_LAEBNotice : 18|3@0+ (1.0000000000,0.0000000000) [0.0000000000|7.0000000000] ""  PCU,PDCU
 SG_ APA_LAEBStatus : 14|3@0+ (1.0000000000,0.0000000000) [0.0000000000|7.0000000000] ""  PCU,PDCU
 SG_ APA_ParkNotice_5 : 6|7@0+ (1.0000000000,0.0000000000) [0.0000000000|127.0000000000] "" Vector__XXX

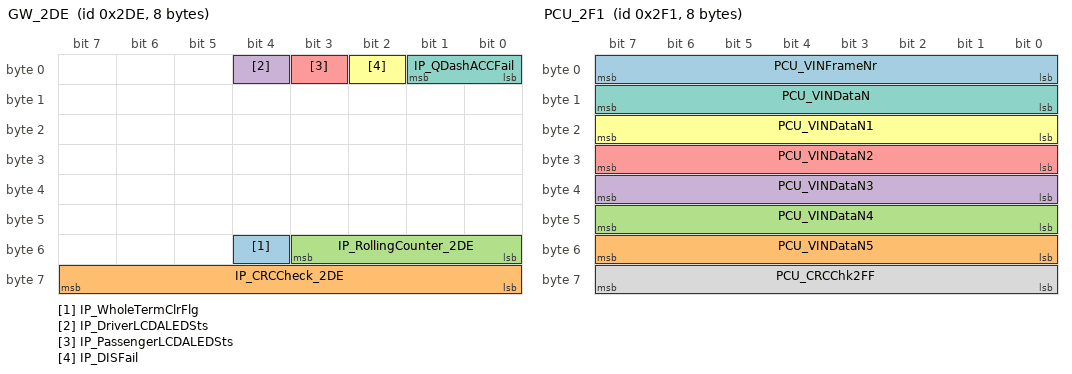
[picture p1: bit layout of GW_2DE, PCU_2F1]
BO_ 734 GW_2DE: 8 GW
 SG_ IP_WholeTermClrFlg : 52|1@0+ (1.0000000000,0.0000000000) [0.0000000000|1.0000000000] ""  PCU,PDCU
 SG_ IP_CRCCheck_2DE : 63|8@0+ (1.0000000000,0.0000000000) [0.0000000000|255.0000000000] "" Vector__XXX
 SG_ IP_RollingCounter_2DE : 51|4@0+ (1.0000000000,0.0000000000) [0.0000000000|15.0000000000] "" Vector__XXX
 SG_ IP_DriverLCDALEDSts : 4|1@0+ (1.0000000000,0.0000000000) [0.0000000000|1.0000000000] "" Vector__XXX
 SG_ IP_PassengerLCDALEDSts : 3|1@0+ (1.0000000000,0.0000000000) [0.0000000000|1.0000000000] "" Vector__XXX
 SG_ IP_DISFail : 2|1@0+ (1.0000000000,0.0000000000) [0.0000000000|1.0000000000] "" Vector__XXX
 SG_ IP_QDashACCFail : 1|2@0+ (1.0000000000,0.0000000000) [0.0000000000|3.0000000000] "" Vector__XXX

BO_ 742 EMS_2E6: 8 EMS
 SG_ EMS_InhbParallel : 55|1@0+ (1.0000000000,0.0000000000) [0.0000000000|1.0000000000] ""  EMS,PDCU,PCU,GW
 SG_ EMS_EngStartFailRestSts : 54|1@0+ (1.0000000000,0.0000000000) [0.0000000000|1.0000000000] ""  EMS,PDCU,PCU,GW
 SG_ EMS_WarmUpCycle : 9|1@0+ (1.0000000000,0.0000000000) [0.0000000000|1.0000000000] ""  EMS,PDCU,GW,PCU,BMS,DPEU,GPEU,RPEU,OBC,TMS,BDC
 SG_ EMS_SecIgnitionCyclesCounter : 53|1@0+ (1.0000000000,0.0000000000) [0.0000000000|1.0000000000] ""  EMS,PDCU,GW,PCU,BMS,DPEU,GPEU,RPEU,OBC
 SG_ EMS_RollingCounter_2E6 : 51|4@0+ (1.0000000000,0.0000000000) [0.0000000000|15.0000000000] ""  EMS,PDCU,PCU,GW,BMS
 SG_ EMS_LoBattU : 31|8@0+ (0.1000000000,0.0000000000) [0.0000000000|25.4000000000] "V"  EMS,PDCU,GW,PCU
 SG_ EMS_LoBattErr : 14|1@0+ (1.0000000000,0.0000000000) [0.0000000000|1.0000000000] ""  EMS,PDCU,GW
 SG_ EMS_IgnitionCyclesCounterValid : 52|1@0+ (1.0000000000,0.0000000000) [0.0000000000|1.0000000000] ""  EMS,PDCU,GW,PCU,BMS,DPEU,GPEU,OBC
 SG_ EMS_GeneralDenoStatusValid : 11|1@0+ (1.0000000000,0.0000000000) [0.0000000000|1.0000000000] ""  EMS,PDCU,GW,PCU,BMS,OBC,TMS,BDC
 SG_ EMS_GeneralDenominatorStatus : 12|1@0+ (1.0000000000,0.0000000000) [0.0000000000|1.0000000000] ""  EMS,PDCU,GW,PCU,BMS,OBC,RPEU,TMS,BDC
 SG_ EMS_FirstIgnitionCycleCounter : 10|1@0+ (1.0000000000,0.0000000000) [0.0000000000|1.0000000000] ""  EMS,PDCU,GW,PCU,BMS,DPEU,GPEU,RPEU,OBC
 SG_ EMS_EngTCoolt : 23|8@0+ (0.7500000000,-48.0000000000) [-48.0000000000|142.5000000000] "DegreeC"  EMS,PDCU,GW,PCU,BMS,DPEU,GPEU,RPEU,OBC,TMS,BDC
 SG_ EMS_EngineIntakeAirTemp : 7|8@0+ (0.7500000000,-40.0000000000) [-40.0000000000|150.5000000000] "degreeC"  EMS,PDCU,PCU,GW,TMS,BDC
 SG_ EMS_DrivingCycle : 8|1@0+ (1.0000000000,0.0000000000) [0.0000000000|1.0000000000] ""  EMS,PDCU,GW,PCU,BMS,RPEU,OBC,DPEU,GPEU,TMS,BDC
 SG_ EMS_CRCCheck_2E6 : 63|8@0+ (1.0000000000,0.0000000000) [0.0000000000|255.0000000000] ""  EMS,PDCU,PCU,GW,BMS
 SG_ EMS_CooltTErr : 15|1@0+ (1.0000000000,0.0000000000) [0.0000000000|1.0000000000] ""  EMS,PDCU,PCU,GW,RPEU,TMS,BDC
 SG_ EMS_Coolreq : 39|7@0+ (1.0000000000,0.0000000000) [0.0000000000|100.0000000000] "%"  EMS,PDCU,GW,TMS,BDC
 SG_ EMS_CatalystWarmUp : 13|1@0+ (1.0000000000,0.0000000000) [0.0000000000|1.0000000000] ""  EMS,PDCU,PCU,GW
 SG_ EMS_AltitudeFactorValid : 32|1@0+ (1.0000000000,0.0000000000) [0.0000000000|1.0000000000] ""  EMS,PDCU,PCU,GW
 SG_ EMS_AltitudeFactor : 47|8@0+ (0.0157500000,0.0000000000) [0.0000000000|4.0000000000] ""  EMS,PDCU,PCU,GW

BO_ 753 PCU_2F1: 8 PCU
 SG_ PCU_VINFrameNr : 7|8@0+ (1.0000000000,0.0000000000) [0.0000000000|2.0000000000] ""  PCU,PDCU
 SG_ PCU_VINDataN5 : 55|8@0+ (1.0000000000,0.0000000000) [0.0000000000|90.0000000000] ""  PCU,PDCU
 SG_ PCU_VINDataN4 : 47|8@0+ (1.0000000000,0.0000000000) [0.0000000000|90.0000000000] ""  PCU,PDCU
 SG_ PCU_VINDataN3 : 39|8@0+ (1.0000000000,0.0000000000) [0.0000000000|90.0000000000] ""  PCU,PDCU
 SG_ PCU_VINDataN2 : 31|8@0+ (1.0000000000,0.0000000000) [0.0000000000|90.0000000000] ""  PCU,PDCU
 SG_ PCU_VINDataN1 : 23|8@0+ (1.0000000000,0.0000000000) [0.0000000000|90.0000000000] ""  PCU,PDCU
 SG_ PCU_VINDataN : 15|8@0+ (1.0000000000,0.0000000000) [0.0000000000|90.0000000000] ""  PCU,PDCU
 SG_ PCU_CRCChk2FF : 63|8@0+ (1.0000000000,0.0000000000) [0.0000000000|255.0000000000] ""  PCU,PDCU

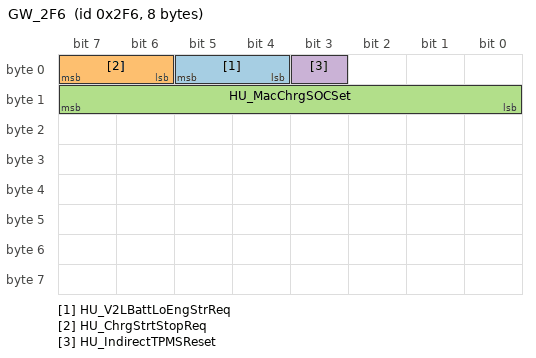
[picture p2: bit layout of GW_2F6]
BO_ 758 GW_2F6: 8 GW
 SG_ HU_V2LBattLoEngStrReq : 5|2@0+ (1.0000000000,0.0000000000) [0.0000000000|3.0000000000] ""  PCU,PDCU
 SG_ HU_ChrgStrtStopReq : 7|2@0+ (1.0000000000,0.0000000000) [0.0000000000|3.0000000000] ""  PCU,PDCU
 SG_ HU_MacChrgSOCSet : 15|8@0+ (0.3920000000,0.0000000000) [0.0000000000|99.9600000000] "%"  PCU,PDCU
 SG_ HU_IndirectTPMSReset : 3|1@0+ (1.0000000000,0.0000000000) [0.0000000000|1.0000000000] "" Vector__XXX

BO_ 812 GW_32C: 8 GW
 SG_ TMS_Heater_pump_Spd_Req : 62|7@0+ (1.0000000000,0.0000000000) [0.0000000000|100.0000000000] "%" Vector__XXX
 SG_ TMS_Motor_pump_Spd_Req : 31|7@0+ (1.0000000000,0.0000000000) [0.0000000000|100.0000000000] "%" Vector__XXX
 SG_ TMS_WarmLoopSts : 45|2@0+ (1.0000000000,0.0000000000) [0.0000000000|3.0000000000] "" Vector__XXX
 SG_ TMS_PwrAct : 41|10@0+ (20.0000000000,0.0000000000) [0.0000000000|20460.0000000000] "W"  PCU,PDCU
 SG_ TMS_OperMod : 19|3@0+ (1.0000000000,0.0000000000) [0.0000000000|7.0000000000] ""  PCU,PDCU
 SG_ TMS_Motor_pump_Actv : 11|1@0+ (1.0000000000,0.0000000000) [0.0000000000|1.0000000000] "" Vector__XXX
 SG_ TMS_MotCoolngLoopSts : 35|2@0+ (1.0000000000,0.0000000000) [0.0000000000|3.0000000000] ""  PCU,PDCU
 SG_ TMS_IntercolerLoopSts : 43|2@0+ (1.0000000000,0.0000000000) [0.0000000000|3.0000000000] ""  PCU,PDCU
 SG_ TMS_IntecoolerpumpActv : 33|1@0+ (1.0000000000,0.0000000000) [0.0000000000|1.0000000000] "" Vector__XXX
 SG_ TMS_Heater_valveSts : 16|1@0+ (1.0000000000,0.0000000000) [0.0000000000|1.0000000000] "" Vector__XXX
 SG_ TMS_Evap_valveSts : 8|1@0+ (1.0000000000,0.0000000000) [0.0000000000|1.0000000000] "" Vector__XXX
 SG_ TMS_EngEnableReq : 32|1@0+ (1.0000000000,0.0000000000) [0.0000000000|1.0000000000] ""  PCU,PDCU
 SG_ TMS_CoolingFanSts : 23|4@0+ (1.0000000000,0.0000000000) [0.0000000000|3.0000000000] ""  EMS,PDCU
 SG_ TMS_BpumpActv : 13|1@0+ (1.0000000000,0.0000000000) [0.0000000000|1.0000000000] "" Vector__XXX
 SG_ TMS_BCoolActv : 12|1@0+ (1.0000000000,0.0000000000) [0.0000000000|1.0000000000] "" Vector__XXX
 SG_ TMS_BattCoolngLoopSts : 37|2@0+ (1.0000000000,0.0000000000) [0.0000000000|3.0000000000] ""  PCU,PDCU
 SG_ TMS_PEU_pump_Spd_Req : 6|7@0+ (1.0000000000,0.0000000000) [0.0000000000|100.0000000000] "%"  DPEU,GPEU
 SG_ TMS_RaceModSwSts : 7|1@0+ (1.0000000000,0.0000000000) [0.0000000000|1.0000000000] ""  PCU,PDCU

CM_ BO_ 1601  " ";
CM_ SG_ 1601 BMS_CellU32  " ";
CM_ SG_ 1601 BMS_CellU31  " ";
CM_ SG_ 1601 BMS_CellU30  " ";
CM_ SG_ 1601 BMS_CellU29  " ";
CM_ SG_ 1601 BMS_CellU28  " ";
CM_ SG_ 1601 BMS_CellU27  " ";
CM_ SG_ 1601 BMS_CellU26  " ";
CM_ SG_ 1601 BMS_CellU25  " ";
CM_ SG_ 1601 BMS_CellU24  " ";
CM_ SG_ 1601 BMS_CellU23  " ";
CM_ SG_ 1601 BMS_CellU22  " ";
CM_ SG_ 1601 BMS_CellU21  " ";
CM_ SG_ 1601 BMS_CellU20  " ";
CM_ SG_ 1601 BMS_CellU19  " ";
CM_ SG_ 1601 BMS_CellU18  " ";
CM_ SG_ 1601 BMS_CellU17  " ";
CM_ SG_ 1601 BMS_CellU16  " ";
CM_ SG_ 1601 BMS_CellU15  " ";
CM_ SG_ 1601 BMS_CellU14  " ";
CM_ SG_ 1601 BMS_CellU13  " ";
CM_ SG_ 1601 BMS_CellU9  " ";
CM_ SG_ 1601 BMS_CellU12  " ";
CM_ SG_ 1601 BMS_CellU11  " ";
CM_ SG_ 1601 BMS_CellU10  " ";
CM_ SG_ 1601 BMS_CellU8  " ";
CM_ SG_ 1601 BMS_CellU7  " ";
CM_ SG_ 1601 BMS_CellU6  " ";
CM_ SG_ 1601 BMS_CellU5  " ";
CM_ SG_ 1601 BMS_CellU4  " ";
CM_ SG_ 1601 BMS_CellU3  " ";
CM_ SG_ 1601 BMS_CellU2  " ";
CM_ SG_ 1601 BMS_CellU1  " ";

CM_ BO_ 1609  " ";
CM_ SG_ 1609 BMS_CellU64  " ";
CM_ SG_ 1609 BMS_CellU63  " ";
CM_ SG_ 1609 BMS_CellU62  " ";
CM_ SG_ 1609 BMS_CellU61  " ";
CM_ SG_ 1609 BMS_CellU60  " ";
CM_ SG_ 1609 BMS_CellU59  " ";
CM_ SG_ 1609 BMS_CellU58  " ";
CM_ SG_ 1609 BMS_CellU57  " ";
CM_ SG_ 1609 BMS_CellU56  " ";
CM_ SG_ 1609 BMS_CellU55  " ";
CM_ SG_ 1609 BMS_CellU54  " ";
CM_ SG_ 1609 BMS_CellU53  " ";
CM_ SG_ 1609 BMS_CellU52  " ";
CM_ SG_ 1609 BMS_CellU51  " ";
CM_ SG_ 1609 BMS_CellU50  " ";
CM_ SG_ 1609 BMS_CellU49  " ";
CM_ SG_ 1609 BMS_CellU48  " ";
CM_ SG_ 1609 BMS_CellU47  " ";
CM_ SG_ 1609 BMS_CellU46  " ";
CM_ SG_ 1609 BMS_CellU45  " ";
CM_ SG_ 1609 BMS_CellU44  " ";
CM_ SG_ 1609 BMS_CellU43  " ";
CM_ SG_ 1609 BMS_CellU42  " ";
CM_ SG_ 1609 BMS_CellU41  " ";
CM_ SG_ 1609 BMS_CellU40  " ";
CM_ SG_ 1609 BMS_CellU39  " ";
CM_ SG_ 1609 BMS_CellU38  " ";
CM_ SG_ 1609 BMS_CellU37  " ";
CM_ SG_ 1609 BMS_CellU36  " ";
CM_ SG_ 1609 BMS_CellU35  " ";
CM_ SG_ 1609 BMS_CellU34  " ";
CM_ SG_ 1609 BMS_CellU33  " ";

CM_ BO_ 1617  " ";
CM_ SG_ 1617 BMS_CellU96  " ";
CM_ SG_ 1617 BMS_CellU95  " ";
CM_ SG_ 1617 BMS_CellU94  " ";
CM_ SG_ 1617 BMS_CellU93  " ";
CM_ SG_ 1617 BMS_CellU92  " ";
CM_ SG_ 1617 BMS_CellU91  " ";
CM_ SG_ 1617 BMS_CellU90  " ";
CM_ SG_ 1617 BMS_CellU89  " ";
CM_ SG_ 1617 BMS_CellU88  " ";
CM_ SG_ 1617 BMS_CellU87  " ";
CM_ SG_ 1617 BMS_CellU86  " ";
CM_ SG_ 1617 BMS_CellU85  " ";
CM_ SG_ 1617 BMS_CellU84  " ";
CM_ SG_ 1617 BMS_CellU83  " ";
CM_ SG_ 1617 BMS_CellU82  " ";
CM_ SG_ 1617 BMS_CellU81  " ";
CM_ SG_ 1617 BMS_CellU80  " ";
CM_ SG_ 1617 BMS_CellU79  " ";
CM_ SG_ 1617 BMS_CellU78  " ";
CM_ SG_ 1617 BMS_CellU77  " ";
CM_ SG_ 1617 BMS_CellU76  " ";
CM_ SG_ 1617 BMS_CellU75  " ";
CM_ SG_ 1617 BMS_CellU74  " ";
CM_ SG_ 1617 BMS_CellU73  " ";
CM_ SG_ 1617 BMS_CellU72  " ";
CM_ SG_ 1617 BMS_CellU71  " ";
CM_ SG_ 1617 BMS_CellU70  " ";
CM_ SG_ 1617 BMS_CellU69  " ";
CM_ SG_ 1617 BMS_CellU68  " ";
CM_ SG_ 1617 BMS_CellU67  " ";
CM_ SG_ 1617 BMS_CellU66  " ";
CM_ SG_ 1617 BMS_CellU65  " ";

CM_ BO_ 1653  " ";
CM_ SG_ 1653 BMS_ModT60  " ";
CM_ SG_ 1653 BMS_ModT59  " ";
CM_ SG_ 1653 BMS_ModT58  " ";
CM_ SG_ 1653 BMS_ModT57  " ";
CM_ SG_ 1653 BMS_ModT56  " ";
CM_ SG_ 1653 BMS_ModT55  " ";
CM_ SG_ 1653 BMS_ModT54  " ";
CM_ SG_ 1653 BMS_ModT53  " ";
CM_ SG_ 1653 BMS_ModT52  " ";
CM_ SG_ 1653 BMS_ModT51  " ";
CM_ SG_ 1653 BMS_ModT50  " ";
CM_ SG_ 1653 BMS_ModT49  " ";
CM_ SG_ 1653 BMS_ModT48  " ";
CM_ SG_ 1653 BMS_ModT47  " ";
CM_ SG_ 1653 BMS_ModT46  " ";
CM_ SG_ 1653 BMS_ModT45  " ";
CM_ SG_ 1653 BMS_ModT44  " ";
CM_ SG_ 1653 BMS_ModT43  " ";
CM_ SG_ 1653 BMS_ModT42  " ";
CM_ SG_ 1653 BMS_ModT41  " ";
CM_ SG_ 1653 BMS_ModT40  " ";
CM_ SG_ 1653 BMS_ModT39  " ";
CM_ SG_ 1653 BMS_ModT38  " ";
CM_ SG_ 1653 BMS_ModT37  " ";
CM_ SG_ 1653 BMS_ModT36  " ";
CM_ SG_ 1653 BMS_ModT35  " ";
CM_ SG_ 1653 BMS_ModT34  " ";
CM_ SG_ 1653 BMS_ModT33  " ";
CM_ SG_ 1653 BMS_ModT32  " ";
CM_ SG_ 1653 BMS_ModT31  " ";
CM_ SG_ 1653 BMS_ModT30  " ";
CM_ SG_ 1653 BMS_ModT29  " ";
CM_ SG_ 1653 BMS_ModT28  " ";
CM_ SG_ 1653 BMS_ModT27  " ";
CM_ SG_ 1653 BMS_ModT26  " ";
CM_ SG_ 1653 BMS_ModT25  " ";
CM_ SG_ 1653 BMS_ModT24  " ";
CM_ SG_ 1653 BMS_ModT23  " ";
CM_ SG_ 1653 BMS_ModT22  " ";
CM_ SG_ 1653 BMS_ModT21  " ";
CM_ SG_ 1653 BMS_ModT20  " ";
CM_ SG_ 1653 BMS_ModT19  " ";
CM_ SG_ 1653 BMS_ModT18  " ";
CM_ SG_ 1653 BMS_ModT17  " ";
CM_ SG_ 1653 BMS_ModT9  " ";
CM_ SG_ 1653 BMS_ModT16  " ";
CM_ SG_ 1653 BMS_ModT15  " ";
CM_ SG_ 1653 BMS_ModT14  " ";
CM_ SG_ 1653 BMS_ModT13  " ";
CM_ SG_ 1653 BMS_ModT12  " ";
CM_ SG_ 1653 BMS_ModT11  " ";
CM_ SG_ 1653 BMS_ModT10  " ";
CM_ SG_ 1653 BMS_ModT8  " ";
CM_ SG_ 1653 BMS_ModT7  " ";
CM_ SG_ 1653 BMS_ModT6  " ";
CM_ SG_ 1653 BMS_ModT5  " ";
CM_ SG_ 1653 BMS_ModT4  " ";
CM_ SG_ 1653 BMS_ModT3  " ";
CM_ SG_ 1653 BMS_ModT2  " ";
CM_ SG_ 1653 BMS_ModT1  " ";

CM_ BO_ 378  " ";
CM_ SG_ 378 IBCU_BrakeFluid_Warning  " ";
CM_ SG_ 378 ESP_VehicleSpeedValid2  "1CA ";
CM_ SG_ 378 ESP_VehicleSpeedValid  "TCU����ΪDCTר�� ";
CM_ SG_ 378 ESP_VehicleSpeed2  "1CA ";
CM_ SG_ 378 ESP_VehicleSpeed  "TCU����ΪDCTר�� ";
CM_ SG_ 378 ESP_TqDecSlowwhlRear  " ";
CM_ SG_ 378 ESP_TqDecSlowwhlFront  " ";
CM_ SG_ 378 ESP_TqDecFastwhlFront  " ";
CM_ SG_ 378 ESP_TorqIncwhlRear  " ";
CM_ SG_ 378 ESP_TorqIncwhlFront  " ";
CM_ SG_ 378 ESP_RollingCounter_1C8  " ";
CM_ SG_ 378 ESP_RollingCounter_1AC  " ";
CM_ SG_ 378 ESP_RollingCounter_187  "AT/DCT ";
CM_ SG_ 378 ESP_pMcVirtual_Q  " ";
CM_ SG_ 378 ESP_pMcVirtual  " ";
CM_ SG_ 378 ESP_MbRegenTarWhlRearQlfr  " ";
CM_ SG_ 378 ESP_MbRegenTarWhlRear  " ";
CM_ SG_ 378 ESP_MbRegenTarWhlFrontQlfr  " ";
CM_ SG_ 378 ESP_MbRegenTarWhlFront  " ";
CM_ SG_ 378 ESP_ESPActiveStatus  "TCU����ΪDCTר�� ";
CM_ SG_ 378 ESP_EngTorqIncRearActive  " ";
CM_ SG_ 378 ESP_EngTorqIncFrontActive  "EMS��ȼ�ͳ����� ";
CM_ SG_ 378 ESP_EngTorqDecRearActive  " ";
CM_ SG_ 378 ESP_EngTorqDecFrontActive  " ";
CM_ SG_ 378 ESP_EBDFailStatus  "TCU����ΪDCTר�� ";
CM_ SG_ 378 ESP_CRCCheck_1C8  " ";
CM_ SG_ 378 ESP_CRCCheck_1AC  " ";
CM_ SG_ 378 ESP_CRCCheck_197  " ";
CM_ SG_ 378 ESP_CRCCheck_187  "AT/DCT ";
CM_ SG_ 378 ESP_ADBF_Active  "Assist Dynamic Brake Failure ";

CM_ BO_ 380  " ";

CM_ BO_ 381  " ";
CM_ SG_ 381 PCU_EngTarSpdReqVld  " ";
CM_ SG_ 381 PCU_RollingCounter_1C4  " ";
CM_ SG_ 381 PCU_RearMotSts  " ";
CM_ SG_ 381 PCU_PwrIndcdRealTqRearWhl  " ";
CM_ SG_ 381 PCU_PwrIndcdDrvrReqTqWhlRear  " ";
CM_ SG_ 381 PCU_ESPTqReqAvlRear  " ";
CM_ SG_ 381 PCU_CRCCheck_1C4  " ";
CM_ SG_ 381 PCU_RollingCounter_1BE  " ";
CM_ SG_ 381 PCU_MbRegenWhlRear  " ";
CM_ SG_ 381 PCU_MbRegenMaxWhlTotal  " ";
CM_ SG_ 381 PCU_MbRegenMaxRearWhl  " ";
CM_ SG_ 381 PCU_CRCCheck_1BE  " ";
CM_ SG_ 381 PCU_PwrTrainSts  " ";
CM_ SG_ 381 PCU_RollingCounter_1A6  " ";
CM_ SG_ 381 PCU_MbRegenWhlFront  " ";
CM_ SG_ 381 PCU_MbRegenMaxWhlQlfr  " ";
CM_ SG_ 381 PCU_MbRegenMaxFrontWhlVld  " ";
CM_ SG_ 381 PCU_MbRegenMaxFrontWhl  " ";
CM_ SG_ 381 PCU_CRCCheck_1A6  " ";
CM_ SG_ 381 PCU_AccPedlVld  " ";
CM_ SG_ 381 PCU_AccPedl  "RMU����Ҫ�� ";
CM_ SG_ 381 PCU_StartStopActiveVld  " ";
CM_ SG_ 381 PCU_StartStopActive  " ";
CM_ SG_ 381 PCU_RollingCounter_211  " ";
CM_ SG_ 381 PCU_RearMotStsVld  " ";
CM_ SG_ 381 PCU_QECACC  " ";
CM_ SG_ 381 PCU_PwrIndcdRealTqWhlFailr  " ";
CM_ SG_ 381 PCU_PwrIndcdRealTqFrontWhl  " ";
CM_ SG_ 381 PCU_PwrIndcdDrvrReqTqWhlFront  " ";
CM_ SG_ 381 PCU_FrontMotStsVld  " ";
CM_ SG_ 381 PCU_FrontMotSts  " ";
CM_ SG_ 381 PCU_ESPTqReqAvlFront  " ";
CM_ SG_ 381 PCU_EngStsVld  " ";
CM_ SG_ 381 PCU_EngSts  " ";
CM_ SG_ 381 PCU_EngClutchStsVld  " ";
CM_ SG_ 381 PCU_EngClutchSts  " ";
CM_ SG_ 381 PCU_ECGPOvrd  " ";
CM_ SG_ 381 PCU_CRCCheck_211  " ";
CM_ SG_ 381 PCU_AccReqPossible  " ";
CM_ SG_ 381 RGearbox_ActualDrivingGear  " ";
CM_ SG_ 381 PCU_TarGearReqValid  " ";
CM_ SG_ 381 PCU_TarGearReq  " ";
CM_ SG_ 381 PCU_K3CluSts  " ";
CM_ SG_ 381 PCU_ClrDiagcInfo  " ";
CM_ SG_ 381 PCU_FuCutOffReq  " ";
CM_ SG_ 381 PCU_VehSts  "
0x0=��ֹ
0x1=�������
0x2=��������
0x3=��������
0x4=�������գ����ƶ�,�����������պϲ�Ϊ�������գ�
0x5=�������
0x6=������ֹ�����ٳ��
0x7=���� ";
CM_ SG_ 381 PCU_VehSpdVld  " ";
CM_ SG_ 381 PCU_VehSpd  " ";
CM_ SG_ 381 PCU_SOCDisp  " ";
CM_ SG_ 381 PCU_CRCID191  " ";
CM_ SG_ 381 PCU_ChrgUnlckILimReq  " ";
CM_ SG_ 381 PCU_ChrgSuspReq  "���ǹ��������Ҫ ";
CM_ SG_ 381 PCU_ChrgIReqLimFac  " ";
CM_ SG_ 381 PCU_ChrgAllwd  " ";
CM_ SG_ 381 PCU_CHMAsignalSts  " ";
CM_ SG_ 381 PCU_BMSOperModReq  " ";
CM_ SG_ 381 PCU_BattIntrHeatAllwd  " ";
CM_ SG_ 381 PCU_ActHVPwrCnsExt  " ";
CM_ SG_ 381 PCU_191CycCntr  " ";

CM_ BO_ 271  "Դ��CHS_IBCU_1CB,0 ";

CM_ BO_ 523  " ";
CM_ SG_ 523 IBCU_DTCAvailable  " ";
CM_ SG_ 523 Wheel_Speed_FL_Pulse  "All4wheelpulsesignalsaresentbyABSwithoutfiltering.Theriseedgeandfalledgearebothcountedinit,thewheelpulsemustbesequentialintheway0,1,2��254,0,4�� ";
CM_ SG_ 523 Wheel_Speed_FR_Pulse  "All4wheelpulsesignalsaresentbyABSwithoutfiltering.Theriseedgeandfalledgearebothcountedinit,thewheelpulsemustbesequentialintheway0,1,2��254,0,3�� ";
CM_ SG_ 523 ESP_MasCylBraPreByDriver  " ";
CM_ SG_ 523 ESP_MasCylBraPreByDriverValid  " ";
CM_ SG_ 523 ESP_DTV_Available  " ";
CM_ SG_ 523 ESP_DTV_Active  " ";
CM_ SG_ 523 Wheel_Speed_RR_Pulse  "All4wheelpulsesignalsaresentbyABSwithoutfiltering.Theriseedgeandfalledgearebothcountedinit,thewheelpulsemustbesequentialintheway0,1,2��254,0,1�� ";
CM_ SG_ 523 Wheel_Speed_RL_Pulse  "All4wheelpulsesignalsaresentbyABSwithoutfiltering.Theriseedgeandfalledgearebothcountedinit,thewheelpulsemustbesequentialintheway0,1,2��254,0,2�� ";
CM_ SG_ 523 Wheel_Speed_FR_Pulse  "All4wheelpulsesignalsaresentbyABSwithoutfiltering.Theriseedgeandfalledgearebothcountedinit,thewheelpulsemustbesequentialintheway0,1,2��254,0,3�� ";
CM_ SG_ 523 ESP_MasCylBrakePressureValid  "258 ";
CM_ SG_ 523 ESP_MasCylBrakePressure  "indicatedthepressureofbrakemastercylinder,butnotthepressureofbrake ";
CM_ SG_ 523 ESP_HHC_Available  "258 AT/DCT ";
CM_ SG_ 523 ESP_HHC_Active  "258 ";
CM_ SG_ 523 ESP_ECDAvailable  "ESP���� ";
CM_ SG_ 523 ESP_ECDActive  "ESP���� ";
CM_ SG_ 523 ESP_CRCCheck_208  " ";
CM_ SG_ 523 ESP_CRCCheck_206  " ";
CM_ SG_ 523 ESP_BrakeLightOnRequest  "258 ";
CM_ SG_ 523 ESP_AutoHoldStandby  "258 ";
CM_ SG_ 523 ESP_AutoHoldAvailable  "258 ";
CM_ SG_ 523 ESP_AutoHoldActive  "258 ";
CM_ SG_ 523 ABS_TODFastOpenRequest  " ";
CM_ SG_ 523 ESP_CDP_ParkingActiveForACC  " ";
CM_ SG_ 523 ESP_CDP_ParkingAvailForACC  " ";
CM_ SG_ 523 ESP_IncreasePressureReqOK  "��ѹ�ɹ��������15֡ ";
CM_ SG_ 523 ESP_UrgencyBrakeAlarm  " ";
CM_ SG_ 523 ESP_RollingCounter_208  "ACM����ΪATר��
rollingcounter ";
CM_ SG_ 523 Wheel_Speed_FL_Pulse  "All4wheelpulsesignalsaresentbyABSwithoutfiltering.Theriseedgeandfalledgearebothcountedinit,thewheelpulsemustbesequentialintheway0,1,2��254,0,4�� ";
CM_ SG_ 523 ESP_RollingCounter_258  "TCU����ΪDCTר�� ";
CM_ SG_ 523 ESP_CRCCheck_258  "TCU����ΪDCTר�� ";
CM_ SG_ 523 ESP_RollingCounter_206  "ACM����ΪATר��
rollingcounter ";
CM_ SG_ 523 ESP_CRCCheck_277  " ";
CM_ SG_ 523 ESP_RollingCounter_277  "rollingcounter ";
CM_ SG_ 523 ESP_TODTorqueMaxLimit  " ";

CM_ BO_ 651  " ";
CM_ SG_ 651 BCM_RefuelReq  "PHEVר�� ";
CM_ SG_ 651 PEPS_ShiftForbidRq  "GW����ת�� ";
CM_ SG_ 651 BCM_DriverDoorStatus  "EMS��ȼ�ͳ����� ";
CM_ SG_ 651 PEPS_StartControlsignal  "EMS��ȼ�ͳ����� ";

CM_ BO_ 724  "Դ��ADAS_APA_2C6,1
ADASD_APA/ADC_2C6,1
ADASA_APA_2C6,1 ";
CM_ SG_ 724 APA_RADSNotice  " ";
CM_ SG_ 724 APA_Right_BSD_LCAAlert  " ";
CM_ SG_ 724 APA_Left_BSD_LCAAlert  " ";
CM_ SG_ 724 APA_PEPS_EngineOffRequest  " ";
CM_ SG_ 724 APA_LAEBReq  "EMS��ȼ�ͳ����� ";
CM_ SG_ 724 APA_NumberofParkingSlot  "���ر���ת�� ";
CM_ SG_ 724 APA_ParkingModeAvailableSts  "���ر���ת�� ";
CM_ SG_ 724 APA_CrossModeSelectReq  "(���ؼ��ܷ��͸�RFBT) ";
CM_ SG_ 724 APA_ASPStatus  "(���ؼ��ܷ��͸�RFBT) ";
CM_ SG_ 724 APA_ASPAvailableStatus  "(���ؼ��ܷ��͸�RFBT) ";
CM_ SG_ 724 APA_RemoteParkingUsingRemind  "(���ؼ��ܷ��͸�RFBT) ";
CM_ SG_ 724 APA_ReleasePressureReq  "�������������һ���źű�ʾ����״̬���������ź� ";
CM_ SG_ 724 APA_CRCCheck_2D4  " ";
CM_ SG_ 724 APA_RollingCounter_2D4  " ";
CM_ SG_ 724 APA_LAEBNotice  " ";
CM_ SG_ 724 APA_LAEBStatus  " ";
CM_ SG_ 724 APA_ParkNotice_5  "(���ؼ��ܷ��͸�RFBT) ";

CM_ BO_ 734  " ";
CM_ SG_ 734 IP_WholeTermClrFlg  " ";
CM_ SG_ 734 IP_DriverLCDALEDSts  "GW����ת�� ";
CM_ SG_ 734 IP_PassengerLCDALEDSts  "GW����ת�� ";
CM_ SG_ 734 IP_DISFail  "GW����ת�� ";
CM_ SG_ 734 IP_QDashACCFail  "GW����ת�� ";

CM_ BO_ 742  " ";
CM_ SG_ 742 EMS_WarmUpCycle  " ";
CM_ SG_ 742 EMS_RollingCounter_2E6  " ";
CM_ SG_ 742 EMS_GeneralDenoStatusValid  "TCU�Ƿ���Ҫ
�������� ";
CM_ SG_ 742 EMS_GeneralDenominatorStatus  "TCU�Ƿ���Ҫ
�������� ";
CM_ SG_ 742 EMS_FirstIgnitionCycleCounter  "TCU�Ƿ���Ҫ
�������� ";
CM_ SG_ 742 EMS_DrivingCycle  "TCU�Ƿ���Ҫ ";
CM_ SG_ 742 EMS_CRCCheck_2E6  " ";
CM_ SG_ 742 EMS_Coolreq  " ";

CM_ BO_ 753  " ";
CM_ SG_ 753 PCU_VINFrameNr  "ֻ����ֱ���������ʱ���ͣ�����ʱ����Ϊ20ms��������ʻʱ�޴˱��� ";
CM_ SG_ 753 PCU_VINDataN5  "VIN����(N5)��Ӧ=VIN����(N+5)
ֻ����ֱ���������ʱ���ͣ�����ʱ����Ϊ20ms��������ʻʱ�޴˱��� ";
CM_ SG_ 753 PCU_VINDataN4  "VIN����(N4)��Ӧ=VIN����(N+4)
ֻ����ֱ���������ʱ���ͣ�����ʱ����Ϊ20ms��������ʻʱ�޴˱��� ";
CM_ SG_ 753 PCU_VINDataN3  "VIN����(N3)��Ӧ=VIN����(N+3)
ֻ����ֱ���������ʱ���ͣ�����ʱ����Ϊ20ms��������ʻʱ�޴˱��� ";
CM_ SG_ 753 PCU_VINDataN2  "VIN����(N2)��Ӧ=VIN����(N+1)
ֻ����ֱ���������ʱ���ͣ�����ʱ����Ϊ20ms��������ʻʱ�޴˱��� ";
CM_ SG_ 753 PCU_VINDataN1  "VIN����(N1)��Ӧ=VIN����(N+2)
ֻ����ֱ���������ʱ���ͣ�����ʱ����Ϊ20ms��������ʻʱ�޴˱��� ";
CM_ SG_ 753 PCU_VINDataN  "VIN����(N)��Ӧ=VIN����(N)
ֻ����ֱ���������ʱ���ͣ�����ʱ����Ϊ20ms��������ʻʱ�޴˱��� ";
CM_ SG_ 753 PCU_CRCChk2FF  "ֻ����ֱ���������ʱ���ͣ�����ʱ����Ϊ20ms��������ʻʱ�޴˱��� ";

CM_ BO_ 758  " ";
CM_ SG_ 758 HU_IndirectTPMSReset  "���̥ѹ����=
���¸�λ�����ɿ���HU������3֡Request reset�����¼�֡�źţ�Ȼ��������3֡No request�źţ�ÿ֡���ķ��ͼ��50ms ";

CM_ BO_ 812  " ";
CM_ SG_ 812 TMS_WarmLoopSts  "TMS�� ";
CM_ SG_ 812 TMS_PwrAct  "TMS�� ";
CM_ SG_ 812 TMS_OperMod  "TMS�� ";
CM_ SG_ 812 TMS_Motor_pump_Actv  "TMS�� ";
CM_ SG_ 812 TMS_MotCoolngLoopSts  "TMS�� ";
CM_ SG_ 812 TMS_IntercolerLoopSts  "TMS�� ";
CM_ SG_ 812 TMS_IntecoolerpumpActv  "TMS�� ";
CM_ SG_ 812 TMS_Heater_valveSts  "TMS�� ";
CM_ SG_ 812 TMS_Evap_valveSts  "TMS�� ";
CM_ SG_ 812 TMS_EngEnableReq  "TMS�� ";
CM_ SG_ 812 TMS_CoolingFanSts  "TMS�� ";
CM_ SG_ 812 TMS_BpumpActv  "TMS��
���Һ�� ";
CM_ SG_ 812 TMS_BCoolActv  "TMS��
���Һ�� ";
CM_ SG_ 812 TMS_BattCoolngLoopSts  "TMS�� ";

BA_DEF_ SG_  "GenSigStartValue" INT 0 0;
BA_DEF_ SG_  "GenSigInvalidValue" STRING  ;
BA_DEF_ SG_  "GenSigCycleTime" INT 0 0;
BA_DEF_ SG_  "GenSigSendType" ENUM  "Cyclic","OnWrite","OnWriteWithRepetition","OnChange","OnChangeWithRepetition","IfActive","IfActiveWithRepetition","NoSigSendType","NotUsed","NotUsed","NotUsed","NotUsed","NotUsed";
BA_DEF_ BO_  "GenMsgSendType" ENUM  "Cyclic","Event","NotUsed","NotUsed","NotUsed","Cyclic","NotUsed","IfActive","NoMsgSendType","NotUsed";
BA_DEF_ BO_  "GenMsgILSupport" ENUM  "No","Yes";
BA_DEF_ BO_  "GenMsgCycleTime" INT 0 65535;
BA_DEF_ BO_  "CANFD_BRS" ENUM  "0","1";
BA_DEF_ BO_  "VFrameFormat" ENUM  "StandardCAN","ExtendedCAN","reserved","reserved","reserved","reserved","reserved","reserved","reserved","reserved","reserved","reserved","reserved","reserved","StandardCAN_FD","ExtendedCAN_FD";
BA_DEF_DEF_  "GenSigStartValue" 0;
BA_DEF_DEF_  "GenSigInvalidValue" "/";
BA_DEF_DEF_  "GenSigCycleTime" 0;
BA_DEF_DEF_  "GenSigSendType" "Cyclic";
BA_DEF_DEF_  "GenMsgSendType" "NoMsgSendType";
BA_DEF_DEF_  "GenMsgILSupport" "Yes";
BA_DEF_DEF_  "GenMsgCycleTime" 0;
BA_DEF_DEF_  "CANFD_BRS" "1";
BA_DEF_DEF_  "VFrameFormat" "StandardCAN";
BA_ "GenMsgCycleTime" BO_ 1601 1000;
BA_ "GenMsgSendType" BO_ 1601 0;
BA_ "VFrameFormat" BO_ 1601 14;
BA_ "GenMsgCycleTime" BO_ 1609 1000;
BA_ "GenMsgSendType" BO_ 1609 0;
BA_ "VFrameFormat" BO_ 1609 14;
BA_ "GenMsgCycleTime" BO_ 1617 1000;
BA_ "GenMsgSendType" BO_ 1617 0;
BA_ "VFrameFormat" BO_ 1617 14;
BA_ "GenMsgCycleTime" BO_ 1653 1000;
BA_ "GenMsgSendType" BO_ 1653 0;
BA_ "VFrameFormat" BO_ 1653 14;
BA_ "GenMsgCycleTime" BO_ 378 10;
BA_ "GenMsgSendType" BO_ 378 0;
BA_ "VFrameFormat" BO_ 378 14;
BA_ "GenMsgCycleTime" BO_ 380 10;
BA_ "GenMsgSendType" BO_ 380 0;
BA_ "VFrameFormat" BO_ 380 14;
BA_ "GenMsgCycleTime" BO_ 381 10;
BA_ "GenMsgSendType" BO_ 381 0;
BA_ "VFrameFormat" BO_ 381 14;
BA_ "GenMsgCycleTime" BO_ 271 10;
BA_ "GenMsgSendType" BO_ 271 0;
BA_ "VFrameFormat" BO_ 271 14;
BA_ "GenMsgCycleTime" BO_ 523 20;
BA_ "GenMsgSendType" BO_ 523 0;
BA_ "VFrameFormat" BO_ 523 14;
BA_ "GenMsgCycleTime" BO_ 651 40;
BA_ "GenMsgSendType" BO_ 651 0;
BA_ "VFrameFormat" BO_ 651 14;
BA_ "GenMsgCycleTime" BO_ 724 40;
BA_ "GenMsgSendType" BO_ 724 0;
BA_ "VFrameFormat" BO_ 724 14;
BA_ "GenMsgCycleTime" BO_ 734 50;
BA_ "GenMsgSendType" BO_ 734 0;
BA_ "VFrameFormat" BO_ 734 14;
BA_ "GenMsgCycleTime" BO_ 742 50;
BA_ "GenMsgSendType" BO_ 742 0;
BA_ "VFrameFormat" BO_ 742 14;
BA_ "GenMsgSendType" BO_ 753 1;
BA_ "VFrameFormat" BO_ 753 14;
BA_ "GenMsgSendType" BO_ 758 1;
BA_ "VFrameFormat" BO_ 758 14;
BA_ "GenMsgCycleTime" BO_ 812 100;
BA_ "GenMsgSendType" BO_ 812 0;
BA_ "VFrameFormat" BO_ 812 14;

BA_ "GenSigCycleTime" SG_ 1601 BMS_CellU32 1000;
BA_ "GenSigInvalidValue" SG_ 1601 BMS_CellU32 "65535";
BA_ "GenSigCycleTime" SG_ 1601 BMS_CellU31 1000;
BA_ "GenSigInvalidValue" SG_ 1601 BMS_CellU31 "65535";
BA_ "GenSigCycleTime" SG_ 1601 BMS_CellU30 1000;
BA_ "GenSigInvalidValue" SG_ 1601 BMS_CellU30 "65535";
BA_ "GenSigCycleTime" SG_ 1601 BMS_CellU29 1000;
BA_ "GenSigInvalidValue" SG_ 1601 BMS_CellU29 "65535";
BA_ "GenSigCycleTime" SG_ 1601 BMS_CellU28 1000;
BA_ "GenSigInvalidValue" SG_ 1601 BMS_CellU28 "65535";
BA_ "GenSigCycleTime" SG_ 1601 BMS_CellU27 1000;
BA_ "GenSigInvalidValue" SG_ 1601 BMS_CellU27 "65535";
BA_ "GenSigCycleTime" SG_ 1601 BMS_CellU26 1000;
BA_ "GenSigInvalidValue" SG_ 1601 BMS_CellU26 "65535";
BA_ "GenSigCycleTime" SG_ 1601 BMS_CellU25 1000;
BA_ "GenSigInvalidValue" SG_ 1601 BMS_CellU25 "65535";
BA_ "GenSigCycleTime" SG_ 1601 BMS_CellU24 1000;
BA_ "GenSigInvalidValue" SG_ 1601 BMS_CellU24 "65535";
BA_ "GenSigCycleTime" SG_ 1601 BMS_CellU23 1000;
BA_ "GenSigInvalidValue" SG_ 1601 BMS_CellU23 "65535";
BA_ "GenSigCycleTime" SG_ 1601 BMS_CellU22 1000;
BA_ "GenSigInvalidValue" SG_ 1601 BMS_CellU22 "65535";
BA_ "GenSigCycleTime" SG_ 1601 BMS_CellU21 1000;
BA_ "GenSigInvalidValue" SG_ 1601 BMS_CellU21 "65535";
BA_ "GenSigCycleTime" SG_ 1601 BMS_CellU20 1000;
BA_ "GenSigInvalidValue" SG_ 1601 BMS_CellU20 "65535";
BA_ "GenSigCycleTime" SG_ 1601 BMS_CellU19 1000;
BA_ "GenSigInvalidValue" SG_ 1601 BMS_CellU19 "65535";
BA_ "GenSigCycleTime" SG_ 1601 BMS_CellU18 1000;
BA_ "GenSigInvalidValue" SG_ 1601 BMS_CellU18 "65535";
BA_ "GenSigCycleTime" SG_ 1601 BMS_CellU17 1000;
BA_ "GenSigInvalidValue" SG_ 1601 BMS_CellU17 "65535";
BA_ "GenSigCycleTime" SG_ 1601 BMS_CellU16 1000;
BA_ "GenSigInvalidValue" SG_ 1601 BMS_CellU16 "65535";
BA_ "GenSigCycleTime" SG_ 1601 BMS_CellU15 1000;
BA_ "GenSigInvalidValue" SG_ 1601 BMS_CellU15 "65535";
BA_ "GenSigCycleTime" SG_ 1601 BMS_CellU14 1000;
BA_ "GenSigInvalidValue" SG_ 1601 BMS_CellU14 "65535";
BA_ "GenSigCycleTime" SG_ 1601 BMS_CellU13 1000;
BA_ "GenSigInvalidValue" SG_ 1601 BMS_CellU13 "65535";
BA_ "GenSigCycleTime" SG_ 1601 BMS_CellU9 1000;
BA_ "GenSigInvalidValue" SG_ 1601 BMS_CellU9 "65535";
BA_ "GenSigCycleTime" SG_ 1601 BMS_CellU12 1000;
BA_ "GenSigInvalidValue" SG_ 1601 BMS_CellU12 "65535";
BA_ "GenSigCycleTime" SG_ 1601 BMS_CellU11 1000;
BA_ "GenSigInvalidValue" SG_ 1601 BMS_CellU11 "65535";
BA_ "GenSigCycleTime" SG_ 1601 BMS_CellU10 1000;
BA_ "GenSigInvalidValue" SG_ 1601 BMS_CellU10 "65535";
BA_ "GenSigCycleTime" SG_ 1601 BMS_CellU8 1000;
BA_ "GenSigInvalidValue" SG_ 1601 BMS_CellU8 "65535";
BA_ "GenSigCycleTime" SG_ 1601 BMS_CellU7 1000;
BA_ "GenSigInvalidValue" SG_ 1601 BMS_CellU7 "65535";
BA_ "GenSigCycleTime" SG_ 1601 BMS_CellU6 1000;
BA_ "GenSigInvalidValue" SG_ 1601 BMS_CellU6 "65535";
BA_ "GenSigCycleTime" SG_ 1601 BMS_CellU5 1000;
BA_ "GenSigInvalidValue" SG_ 1601 BMS_CellU5 "65535";
BA_ "GenSigCycleTime" SG_ 1601 BMS_CellU4 1000;
BA_ "GenSigInvalidValue" SG_ 1601 BMS_CellU4 "65535";
BA_ "GenSigCycleTime" SG_ 1601 BMS_CellU3 1000;
BA_ "GenSigInvalidValue" SG_ 1601 BMS_CellU3 "65535";
BA_ "GenSigCycleTime" SG_ 1601 BMS_CellU2 1000;
BA_ "GenSigInvalidValue" SG_ 1601 BMS_CellU2 "65535";
BA_ "GenSigCycleTime" SG_ 1601 BMS_CellU1 1000;
BA_ "GenSigInvalidValue" SG_ 1601 BMS_CellU1 "65535";

BA_ "GenSigCycleTime" SG_ 1609 BMS_CellU64 1000;
BA_ "GenSigInvalidValue" SG_ 1609 BMS_CellU64 "65535";
BA_ "GenSigCycleTime" SG_ 1609 BMS_CellU63 1000;
BA_ "GenSigInvalidValue" SG_ 1609 BMS_CellU63 "65535";
BA_ "GenSigCycleTime" SG_ 1609 BMS_CellU62 1000;
BA_ "GenSigInvalidValue" SG_ 1609 BMS_CellU62 "65535";
BA_ "GenSigCycleTime" SG_ 1609 BMS_CellU61 1000;
BA_ "GenSigInvalidValue" SG_ 1609 BMS_CellU61 "65535";
BA_ "GenSigCycleTime" SG_ 1609 BMS_CellU60 1000;
BA_ "GenSigInvalidValue" SG_ 1609 BMS_CellU60 "65535";
BA_ "GenSigCycleTime" SG_ 1609 BMS_CellU59 1000;
BA_ "GenSigInvalidValue" SG_ 1609 BMS_CellU59 "65535";
BA_ "GenSigCycleTime" SG_ 1609 BMS_CellU58 1000;
BA_ "GenSigInvalidValue" SG_ 1609 BMS_CellU58 "65535";
BA_ "GenSigCycleTime" SG_ 1609 BMS_CellU57 1000;
BA_ "GenSigInvalidValue" SG_ 1609 BMS_CellU57 "65535";
BA_ "GenSigCycleTime" SG_ 1609 BMS_CellU56 1000;
BA_ "GenSigInvalidValue" SG_ 1609 BMS_CellU56 "65535";
BA_ "GenSigCycleTime" SG_ 1609 BMS_CellU55 1000;
BA_ "GenSigInvalidValue" SG_ 1609 BMS_CellU55 "65535";
BA_ "GenSigCycleTime" SG_ 1609 BMS_CellU54 1000;
BA_ "GenSigInvalidValue" SG_ 1609 BMS_CellU54 "65535";
BA_ "GenSigCycleTime" SG_ 1609 BMS_CellU53 1000;
BA_ "GenSigInvalidValue" SG_ 1609 BMS_CellU53 "65535";
BA_ "GenSigCycleTime" SG_ 1609 BMS_CellU52 1000;
BA_ "GenSigInvalidValue" SG_ 1609 BMS_CellU52 "65535";
BA_ "GenSigCycleTime" SG_ 1609 BMS_CellU51 1000;
BA_ "GenSigInvalidValue" SG_ 1609 BMS_CellU51 "65535";
BA_ "GenSigCycleTime" SG_ 1609 BMS_CellU50 1000;
BA_ "GenSigInvalidValue" SG_ 1609 BMS_CellU50 "65535";
BA_ "GenSigCycleTime" SG_ 1609 BMS_CellU49 1000;
BA_ "GenSigInvalidValue" SG_ 1609 BMS_CellU49 "65535";
BA_ "GenSigCycleTime" SG_ 1609 BMS_CellU48 1000;
BA_ "GenSigInvalidValue" SG_ 1609 BMS_CellU48 "65535";
BA_ "GenSigCycleTime" SG_ 1609 BMS_CellU47 1000;
BA_ "GenSigInvalidValue" SG_ 1609 BMS_CellU47 "65535";
BA_ "GenSigCycleTime" SG_ 1609 BMS_CellU46 1000;
BA_ "GenSigInvalidValue" SG_ 1609 BMS_CellU46 "65535";
BA_ "GenSigCycleTime" SG_ 1609 BMS_CellU45 1000;
BA_ "GenSigInvalidValue" SG_ 1609 BMS_CellU45 "65535";
BA_ "GenSigCycleTime" SG_ 1609 BMS_CellU44 1000;
BA_ "GenSigInvalidValue" SG_ 1609 BMS_CellU44 "65535";
BA_ "GenSigCycleTime" SG_ 1609 BMS_CellU43 1000;
BA_ "GenSigInvalidValue" SG_ 1609 BMS_CellU43 "65535";
BA_ "GenSigCycleTime" SG_ 1609 BMS_CellU42 1000;
BA_ "GenSigInvalidValue" SG_ 1609 BMS_CellU42 "65535";
BA_ "GenSigCycleTime" SG_ 1609 BMS_CellU41 1000;
BA_ "GenSigInvalidValue" SG_ 1609 BMS_CellU41 "65535";
BA_ "GenSigCycleTime" SG_ 1609 BMS_CellU40 1000;
BA_ "GenSigInvalidValue" SG_ 1609 BMS_CellU40 "65535";
BA_ "GenSigCycleTime" SG_ 1609 BMS_CellU39 1000;
BA_ "GenSigInvalidValue" SG_ 1609 BMS_CellU39 "65535";
BA_ "GenSigCycleTime" SG_ 1609 BMS_CellU38 1000;
BA_ "GenSigInvalidValue" SG_ 1609 BMS_CellU38 "65535";
BA_ "GenSigCycleTime" SG_ 1609 BMS_CellU37 1000;
BA_ "GenSigInvalidValue" SG_ 1609 BMS_CellU37 "65535";
BA_ "GenSigCycleTime" SG_ 1609 BMS_CellU36 1000;
BA_ "GenSigInvalidValue" SG_ 1609 BMS_CellU36 "65535";
BA_ "GenSigCycleTime" SG_ 1609 BMS_CellU35 1000;
BA_ "GenSigInvalidValue" SG_ 1609 BMS_CellU35 "65535";
BA_ "GenSigCycleTime" SG_ 1609 BMS_CellU34 1000;
BA_ "GenSigInvalidValue" SG_ 1609 BMS_CellU34 "65535";
BA_ "GenSigCycleTime" SG_ 1609 BMS_CellU33 1000;
BA_ "GenSigInvalidValue" SG_ 1609 BMS_CellU33 "65535";

BA_ "GenSigCycleTime" SG_ 1617 BMS_CellU96 1000;
BA_ "GenSigInvalidValue" SG_ 1617 BMS_CellU96 "65535";
BA_ "GenSigCycleTime" SG_ 1617 BMS_CellU95 1000;
BA_ "GenSigInvalidValue" SG_ 1617 BMS_CellU95 "65535";
BA_ "GenSigCycleTime" SG_ 1617 BMS_CellU94 1000;
BA_ "GenSigInvalidValue" SG_ 1617 BMS_CellU94 "65535";
BA_ "GenSigCycleTime" SG_ 1617 BMS_CellU93 1000;
BA_ "GenSigInvalidValue" SG_ 1617 BMS_CellU93 "65535";
BA_ "GenSigCycleTime" SG_ 1617 BMS_CellU92 1000;
BA_ "GenSigInvalidValue" SG_ 1617 BMS_CellU92 "65535";
BA_ "GenSigCycleTime" SG_ 1617 BMS_CellU91 1000;
BA_ "GenSigInvalidValue" SG_ 1617 BMS_CellU91 "65535";
BA_ "GenSigCycleTime" SG_ 1617 BMS_CellU90 1000;
BA_ "GenSigInvalidValue" SG_ 1617 BMS_CellU90 "65535";
BA_ "GenSigCycleTime" SG_ 1617 BMS_CellU89 1000;
BA_ "GenSigInvalidValue" SG_ 1617 BMS_CellU89 "65535";
BA_ "GenSigCycleTime" SG_ 1617 BMS_CellU88 1000;
BA_ "GenSigInvalidValue" SG_ 1617 BMS_CellU88 "65535";
BA_ "GenSigCycleTime" SG_ 1617 BMS_CellU87 1000;
BA_ "GenSigInvalidValue" SG_ 1617 BMS_CellU87 "65535";
BA_ "GenSigCycleTime" SG_ 1617 BMS_CellU86 1000;
BA_ "GenSigInvalidValue" SG_ 1617 BMS_CellU86 "65535";
BA_ "GenSigCycleTime" SG_ 1617 BMS_CellU85 1000;
BA_ "GenSigInvalidValue" SG_ 1617 BMS_CellU85 "65535";
BA_ "GenSigCycleTime" SG_ 1617 BMS_CellU84 1000;
BA_ "GenSigInvalidValue" SG_ 1617 BMS_CellU84 "65535";
BA_ "GenSigCycleTime" SG_ 1617 BMS_CellU83 1000;
BA_ "GenSigInvalidValue" SG_ 1617 BMS_CellU83 "65535";
BA_ "GenSigCycleTime" SG_ 1617 BMS_CellU82 1000;
BA_ "GenSigInvalidValue" SG_ 1617 BMS_CellU82 "65535";
BA_ "GenSigCycleTime" SG_ 1617 BMS_CellU81 1000;
BA_ "GenSigInvalidValue" SG_ 1617 BMS_CellU81 "65535";
BA_ "GenSigCycleTime" SG_ 1617 BMS_CellU80 1000;
BA_ "GenSigInvalidValue" SG_ 1617 BMS_CellU80 "65535";
BA_ "GenSigCycleTime" SG_ 1617 BMS_CellU79 1000;
BA_ "GenSigInvalidValue" SG_ 1617 BMS_CellU79 "65535";
BA_ "GenSigCycleTime" SG_ 1617 BMS_CellU78 1000;
BA_ "GenSigInvalidValue" SG_ 1617 BMS_CellU78 "65535";
BA_ "GenSigCycleTime" SG_ 1617 BMS_CellU77 1000;
BA_ "GenSigInvalidValue" SG_ 1617 BMS_CellU77 "65535";
BA_ "GenSigCycleTime" SG_ 1617 BMS_CellU76 1000;
BA_ "GenSigInvalidValue" SG_ 1617 BMS_CellU76 "65535";
BA_ "GenSigCycleTime" SG_ 1617 BMS_CellU75 1000;
BA_ "GenSigInvalidValue" SG_ 1617 BMS_CellU75 "65535";
BA_ "GenSigCycleTime" SG_ 1617 BMS_CellU74 1000;
BA_ "GenSigInvalidValue" SG_ 1617 BMS_CellU74 "65535";
BA_ "GenSigCycleTime" SG_ 1617 BMS_CellU73 1000;
BA_ "GenSigInvalidValue" SG_ 1617 BMS_CellU73 "65535";
BA_ "GenSigCycleTime" SG_ 1617 BMS_CellU72 1000;
BA_ "GenSigInvalidValue" SG_ 1617 BMS_CellU72 "65535";
BA_ "GenSigCycleTime" SG_ 1617 BMS_CellU71 1000;
BA_ "GenSigInvalidValue" SG_ 1617 BMS_CellU71 "65535";
BA_ "GenSigCycleTime" SG_ 1617 BMS_CellU70 1000;
BA_ "GenSigInvalidValue" SG_ 1617 BMS_CellU70 "65535";
BA_ "GenSigCycleTime" SG_ 1617 BMS_CellU69 1000;
BA_ "GenSigInvalidValue" SG_ 1617 BMS_CellU69 "65535";
BA_ "GenSigCycleTime" SG_ 1617 BMS_CellU68 1000;
BA_ "GenSigInvalidValue" SG_ 1617 BMS_CellU68 "65535";
BA_ "GenSigCycleTime" SG_ 1617 BMS_CellU67 1000;
BA_ "GenSigInvalidValue" SG_ 1617 BMS_CellU67 "65535";
BA_ "GenSigCycleTime" SG_ 1617 BMS_CellU66 1000;
BA_ "GenSigInvalidValue" SG_ 1617 BMS_CellU66 "65535";
BA_ "GenSigCycleTime" SG_ 1617 BMS_CellU65 1000;
BA_ "GenSigInvalidValue" SG_ 1617 BMS_CellU65 "65535";

BA_ "GenSigCycleTime" SG_ 1653 BMS_ModT60 1000;
BA_ "GenSigStartValue" SG_ 1653 BMS_ModT60 60.000000;
BA_ "GenSigInvalidValue" SG_ 1653 BMS_ModT60 "255";
BA_ "GenSigCycleTime" SG_ 1653 BMS_ModT59 1000;
BA_ "GenSigStartValue" SG_ 1653 BMS_ModT59 60.000000;
BA_ "GenSigInvalidValue" SG_ 1653 BMS_ModT59 "255";
BA_ "GenSigCycleTime" SG_ 1653 BMS_ModT58 1000;
BA_ "GenSigStartValue" SG_ 1653 BMS_ModT58 60.000000;
BA_ "GenSigInvalidValue" SG_ 1653 BMS_ModT58 "255";
BA_ "GenSigCycleTime" SG_ 1653 BMS_ModT57 1000;
BA_ "GenSigStartValue" SG_ 1653 BMS_ModT57 60.000000;
BA_ "GenSigInvalidValue" SG_ 1653 BMS_ModT57 "255";
BA_ "GenSigCycleTime" SG_ 1653 BMS_ModT56 1000;
BA_ "GenSigStartValue" SG_ 1653 BMS_ModT56 60.000000;
BA_ "GenSigInvalidValue" SG_ 1653 BMS_ModT56 "255";
BA_ "GenSigCycleTime" SG_ 1653 BMS_ModT55 1000;
BA_ "GenSigStartValue" SG_ 1653 BMS_ModT55 60.000000;
BA_ "GenSigInvalidValue" SG_ 1653 BMS_ModT55 "255";
BA_ "GenSigCycleTime" SG_ 1653 BMS_ModT54 1000;
BA_ "GenSigStartValue" SG_ 1653 BMS_ModT54 60.000000;
BA_ "GenSigInvalidValue" SG_ 1653 BMS_ModT54 "255";
BA_ "GenSigCycleTime" SG_ 1653 BMS_ModT53 1000;
BA_ "GenSigStartValue" SG_ 1653 BMS_ModT53 60.000000;
BA_ "GenSigInvalidValue" SG_ 1653 BMS_ModT53 "255";
BA_ "GenSigCycleTime" SG_ 1653 BMS_ModT52 1000;
BA_ "GenSigStartValue" SG_ 1653 BMS_ModT52 60.000000;
BA_ "GenSigInvalidValue" SG_ 1653 BMS_ModT52 "255";
BA_ "GenSigCycleTime" SG_ 1653 BMS_ModT51 1000;
BA_ "GenSigStartValue" SG_ 1653 BMS_ModT51 60.000000;
BA_ "GenSigInvalidValue" SG_ 1653 BMS_ModT51 "255";
BA_ "GenSigCycleTime" SG_ 1653 BMS_ModT50 1000;
BA_ "GenSigStartValue" SG_ 1653 BMS_ModT50 60.000000;
BA_ "GenSigInvalidValue" SG_ 1653 BMS_ModT50 "255";
BA_ "GenSigCycleTime" SG_ 1653 BMS_ModT49 1000;
BA_ "GenSigStartValue" SG_ 1653 BMS_ModT49 60.000000;
BA_ "GenSigInvalidValue" SG_ 1653 BMS_ModT49 "255";
BA_ "GenSigCycleTime" SG_ 1653 BMS_ModT48 1000;
BA_ "GenSigStartValue" SG_ 1653 BMS_ModT48 60.000000;
BA_ "GenSigInvalidValue" SG_ 1653 BMS_ModT48 "255";
BA_ "GenSigCycleTime" SG_ 1653 BMS_ModT47 1000;
BA_ "GenSigStartValue" SG_ 1653 BMS_ModT47 60.000000;
BA_ "GenSigInvalidValue" SG_ 1653 BMS_ModT47 "255";
BA_ "GenSigCycleTime" SG_ 1653 BMS_ModT46 1000;
BA_ "GenSigStartValue" SG_ 1653 BMS_ModT46 60.000000;
BA_ "GenSigInvalidValue" SG_ 1653 BMS_ModT46 "255";
BA_ "GenSigCycleTime" SG_ 1653 BMS_ModT45 1000;
BA_ "GenSigStartValue" SG_ 1653 BMS_ModT45 60.000000;
BA_ "GenSigInvalidValue" SG_ 1653 BMS_ModT45 "255";
BA_ "GenSigCycleTime" SG_ 1653 BMS_ModT44 1000;
BA_ "GenSigStartValue" SG_ 1653 BMS_ModT44 60.000000;
BA_ "GenSigInvalidValue" SG_ 1653 BMS_ModT44 "255";
BA_ "GenSigCycleTime" SG_ 1653 BMS_ModT43 1000;
BA_ "GenSigStartValue" SG_ 1653 BMS_ModT43 60.000000;
BA_ "GenSigInvalidValue" SG_ 1653 BMS_ModT43 "255";
BA_ "GenSigCycleTime" SG_ 1653 BMS_ModT42 1000;
BA_ "GenSigStartValue" SG_ 1653 BMS_ModT42 60.000000;
BA_ "GenSigInvalidValue" SG_ 1653 BMS_ModT42 "255";
BA_ "GenSigCycleTime" SG_ 1653 BMS_ModT41 1000;
BA_ "GenSigStartValue" SG_ 1653 BMS_ModT41 60.000000;
BA_ "GenSigInvalidValue" SG_ 1653 BMS_ModT41 "255";
BA_ "GenSigCycleTime" SG_ 1653 BMS_ModT40 1000;
BA_ "GenSigStartValue" SG_ 1653 BMS_ModT40 60.000000;
BA_ "GenSigInvalidValue" SG_ 1653 BMS_ModT40 "255";
BA_ "GenSigCycleTime" SG_ 1653 BMS_ModT39 1000;
BA_ "GenSigStartValue" SG_ 1653 BMS_ModT39 60.000000;
BA_ "GenSigInvalidValue" SG_ 1653 BMS_ModT39 "255";
BA_ "GenSigCycleTime" SG_ 1653 BMS_ModT38 1000;
BA_ "GenSigStartValue" SG_ 1653 BMS_ModT38 60.000000;
BA_ "GenSigInvalidValue" SG_ 1653 BMS_ModT38 "255";
BA_ "GenSigCycleTime" SG_ 1653 BMS_ModT37 1000;
BA_ "GenSigStartValue" SG_ 1653 BMS_ModT37 60.000000;
BA_ "GenSigInvalidValue" SG_ 1653 BMS_ModT37 "255";
BA_ "GenSigCycleTime" SG_ 1653 BMS_ModT36 1000;
BA_ "GenSigStartValue" SG_ 1653 BMS_ModT36 60.000000;
BA_ "GenSigInvalidValue" SG_ 1653 BMS_ModT36 "255";
BA_ "GenSigCycleTime" SG_ 1653 BMS_ModT35 1000;
BA_ "GenSigStartValue" SG_ 1653 BMS_ModT35 60.000000;
BA_ "GenSigInvalidValue" SG_ 1653 BMS_ModT35 "255";
BA_ "GenSigCycleTime" SG_ 1653 BMS_ModT34 1000;
BA_ "GenSigStartValue" SG_ 1653 BMS_ModT34 60.000000;
BA_ "GenSigInvalidValue" SG_ 1653 BMS_ModT34 "255";
BA_ "GenSigCycleTime" SG_ 1653 BMS_ModT33 1000;
BA_ "GenSigStartValue" SG_ 1653 BMS_ModT33 60.000000;
BA_ "GenSigInvalidValue" SG_ 1653 BMS_ModT33 "255";
BA_ "GenSigCycleTime" SG_ 1653 BMS_ModT32 1000;
BA_ "GenSigStartValue" SG_ 1653 BMS_ModT32 60.000000;
BA_ "GenSigInvalidValue" SG_ 1653 BMS_ModT32 "255";
BA_ "GenSigCycleTime" SG_ 1653 BMS_ModT31 1000;
BA_ "GenSigStartValue" SG_ 1653 BMS_ModT31 60.000000;
BA_ "GenSigInvalidValue" SG_ 1653 BMS_ModT31 "255";
BA_ "GenSigCycleTime" SG_ 1653 BMS_ModT30 1000;
BA_ "GenSigStartValue" SG_ 1653 BMS_ModT30 60.000000;
BA_ "GenSigInvalidValue" SG_ 1653 BMS_ModT30 "255";
BA_ "GenSigCycleTime" SG_ 1653 BMS_ModT29 1000;
BA_ "GenSigStartValue" SG_ 1653 BMS_ModT29 60.000000;
BA_ "GenSigInvalidValue" SG_ 1653 BMS_ModT29 "255";
BA_ "GenSigCycleTime" SG_ 1653 BMS_ModT28 1000;
BA_ "GenSigStartValue" SG_ 1653 BMS_ModT28 60.000000;
BA_ "GenSigInvalidValue" SG_ 1653 BMS_ModT28 "255";
BA_ "GenSigCycleTime" SG_ 1653 BMS_ModT27 1000;
BA_ "GenSigStartValue" SG_ 1653 BMS_ModT27 60.000000;
BA_ "GenSigInvalidValue" SG_ 1653 BMS_ModT27 "255";
BA_ "GenSigCycleTime" SG_ 1653 BMS_ModT26 1000;
BA_ "GenSigStartValue" SG_ 1653 BMS_ModT26 60.000000;
BA_ "GenSigInvalidValue" SG_ 1653 BMS_ModT26 "255";
BA_ "GenSigCycleTime" SG_ 1653 BMS_ModT25 1000;
BA_ "GenSigStartValue" SG_ 1653 BMS_ModT25 60.000000;
BA_ "GenSigInvalidValue" SG_ 1653 BMS_ModT25 "255";
BA_ "GenSigCycleTime" SG_ 1653 BMS_ModT24 1000;
BA_ "GenSigStartValue" SG_ 1653 BMS_ModT24 60.000000;
BA_ "GenSigInvalidValue" SG_ 1653 BMS_ModT24 "255";
BA_ "GenSigCycleTime" SG_ 1653 BMS_ModT23 1000;
BA_ "GenSigStartValue" SG_ 1653 BMS_ModT23 60.000000;
BA_ "GenSigInvalidValue" SG_ 1653 BMS_ModT23 "255";
BA_ "GenSigCycleTime" SG_ 1653 BMS_ModT22 1000;
BA_ "GenSigStartValue" SG_ 1653 BMS_ModT22 60.000000;
BA_ "GenSigInvalidValue" SG_ 1653 BMS_ModT22 "255";
BA_ "GenSigCycleTime" SG_ 1653 BMS_ModT21 1000;
BA_ "GenSigStartValue" SG_ 1653 BMS_ModT21 60.000000;
BA_ "GenSigInvalidValue" SG_ 1653 BMS_ModT21 "255";
BA_ "GenSigCycleTime" SG_ 1653 BMS_ModT20 1000;
BA_ "GenSigStartValue" SG_ 1653 BMS_ModT20 60.000000;
BA_ "GenSigInvalidValue" SG_ 1653 BMS_ModT20 "255";
BA_ "GenSigCycleTime" SG_ 1653 BMS_ModT19 1000;
BA_ "GenSigStartValue" SG_ 1653 BMS_ModT19 60.000000;
BA_ "GenSigInvalidValue" SG_ 1653 BMS_ModT19 "255";
BA_ "GenSigCycleTime" SG_ 1653 BMS_ModT18 1000;
BA_ "GenSigStartValue" SG_ 1653 BMS_ModT18 60.000000;
BA_ "GenSigInvalidValue" SG_ 1653 BMS_ModT18 "255";
BA_ "GenSigCycleTime" SG_ 1653 BMS_ModT17 1000;
BA_ "GenSigStartValue" SG_ 1653 BMS_ModT17 60.000000;
BA_ "GenSigInvalidValue" SG_ 1653 BMS_ModT17 "255";
BA_ "GenSigCycleTime" SG_ 1653 BMS_ModT9 1000;
BA_ "GenSigStartValue" SG_ 1653 BMS_ModT9 60.000000;
BA_ "GenSigInvalidValue" SG_ 1653 BMS_ModT9 "255";
BA_ "GenSigCycleTime" SG_ 1653 BMS_ModT16 1000;
BA_ "GenSigStartValue" SG_ 1653 BMS_ModT16 60.000000;
BA_ "GenSigInvalidValue" SG_ 1653 BMS_ModT16 "255";
BA_ "GenSigCycleTime" SG_ 1653 BMS_ModT15 1000;
BA_ "GenSigStartValue" SG_ 1653 BMS_ModT15 60.000000;
BA_ "GenSigInvalidValue" SG_ 1653 BMS_ModT15 "255";
BA_ "GenSigCycleTime" SG_ 1653 BMS_ModT14 1000;
BA_ "GenSigStartValue" SG_ 1653 BMS_ModT14 60.000000;
BA_ "GenSigInvalidValue" SG_ 1653 BMS_ModT14 "255";
BA_ "GenSigCycleTime" SG_ 1653 BMS_ModT13 1000;
BA_ "GenSigStartValue" SG_ 1653 BMS_ModT13 60.000000;
BA_ "GenSigInvalidValue" SG_ 1653 BMS_ModT13 "255";
BA_ "GenSigCycleTime" SG_ 1653 BMS_ModT12 1000;
BA_ "GenSigStartValue" SG_ 1653 BMS_ModT12 60.000000;
BA_ "GenSigInvalidValue" SG_ 1653 BMS_ModT12 "255";
BA_ "GenSigCycleTime" SG_ 1653 BMS_ModT11 1000;
BA_ "GenSigStartValue" SG_ 1653 BMS_ModT11 60.000000;
BA_ "GenSigInvalidValue" SG_ 1653 BMS_ModT11 "255";
BA_ "GenSigCycleTime" SG_ 1653 BMS_ModT10 1000;
BA_ "GenSigStartValue" SG_ 1653 BMS_ModT10 60.000000;
BA_ "GenSigInvalidValue" SG_ 1653 BMS_ModT10 "255";
BA_ "GenSigCycleTime" SG_ 1653 BMS_ModT8 1000;
BA_ "GenSigStartValue" SG_ 1653 BMS_ModT8 60.000000;
BA_ "GenSigInvalidValue" SG_ 1653 BMS_ModT8 "255";
BA_ "GenSigCycleTime" SG_ 1653 BMS_ModT7 1000;
BA_ "GenSigStartValue" SG_ 1653 BMS_ModT7 60.000000;
BA_ "GenSigInvalidValue" SG_ 1653 BMS_ModT7 "255";
BA_ "GenSigCycleTime" SG_ 1653 BMS_ModT6 1000;
BA_ "GenSigStartValue" SG_ 1653 BMS_ModT6 60.000000;
BA_ "GenSigInvalidValue" SG_ 1653 BMS_ModT6 "255";
BA_ "GenSigCycleTime" SG_ 1653 BMS_ModT5 1000;
BA_ "GenSigStartValue" SG_ 1653 BMS_ModT5 60.000000;
BA_ "GenSigInvalidValue" SG_ 1653 BMS_ModT5 "255";
BA_ "GenSigCycleTime" SG_ 1653 BMS_ModT4 1000;
BA_ "GenSigStartValue" SG_ 1653 BMS_ModT4 60.000000;
BA_ "GenSigInvalidValue" SG_ 1653 BMS_ModT4 "255";
BA_ "GenSigCycleTime" SG_ 1653 BMS_ModT3 1000;
BA_ "GenSigStartValue" SG_ 1653 BMS_ModT3 60.000000;
BA_ "GenSigInvalidValue" SG_ 1653 BMS_ModT3 "255";
BA_ "GenSigCycleTime" SG_ 1653 BMS_ModT2 1000;
BA_ "GenSigStartValue" SG_ 1653 BMS_ModT2 60.000000;
BA_ "GenSigInvalidValue" SG_ 1653 BMS_ModT2 "255";
BA_ "GenSigCycleTime" SG_ 1653 BMS_ModT1 1000;
BA_ "GenSigStartValue" SG_ 1653 BMS_ModT1 60.000000;
BA_ "GenSigInvalidValue" SG_ 1653 BMS_ModT1 "255";

BA_ "GenSigCycleTime" SG_ 378 Wheel_Speed_RR_Data 10;
BA_ "GenSigInvalidValue" SG_ 378 Wheel_Speed_RR_Data "8191";
BA_ "GenSigCycleTime" SG_ 378 Wheel_Speed_RL_Valid_Data 10;
BA_ "GenSigInvalidValue" SG_ 378 Wheel_Speed_RL_Valid_Data "1";
BA_ "GenSigCycleTime" SG_ 378 Wheel_Speed_RL_Data 10;
BA_ "GenSigInvalidValue" SG_ 378 Wheel_Speed_RL_Data "8191";
BA_ "GenSigCycleTime" SG_ 378 Wheel_Speed_RR_Valid_Data 10;
BA_ "GenSigInvalidValue" SG_ 378 Wheel_Speed_RR_Valid_Data "1";
BA_ "GenSigCycleTime" SG_ 378 ESP_VDCActive 10;
BA_ "GenSigCycleTime" SG_ 378 ESP_TCSActive 10;
BA_ "GenSigCycleTime" SG_ 378 ESP_RollingCounter_17A 10;
BA_ "GenSigCycleTime" SG_ 378 ESP_CRCCheck_17A 10;
BA_ "GenSigCycleTime" SG_ 378 ESP_ElectricBoostFailStatus 10;
BA_ "GenSigCycleTime" SG_ 378 ESP_MbRegenTarWhlTotalQlfr 10;
BA_ "GenSigCycleTime" SG_ 378 ESP_MbRegenTarWhlTotal 10;
BA_ "GenSigInvalidValue" SG_ 378 ESP_MbRegenTarWhlTotal "65535";
BA_ "GenSigCycleTime" SG_ 378 ESP_RollerbenchType 10;
BA_ "GenSigCycleTime" SG_ 378 IBCU_BrakeFluid_Warning 10;
BA_ "GenSigInvalidValue" SG_ 378 IBCU_BrakeFluid_Warning "3";
BA_ "GenSigCycleTime" SG_ 378 ESP_VehicleSpeedValid2 10;
BA_ "GenSigCycleTime" SG_ 378 ESP_VehicleSpeedValid 10;
BA_ "GenSigInvalidValue" SG_ 378 ESP_VehicleSpeedValid "1";
BA_ "GenSigCycleTime" SG_ 378 ESP_VehicleSpeed2 10;
BA_ "GenSigCycleTime" SG_ 378 ESP_VehicleSpeed 10;
BA_ "GenSigInvalidValue" SG_ 378 ESP_VehicleSpeed "8191";
BA_ "GenSigCycleTime" SG_ 378 ESP_TqDecSlowwhlRear 10;
BA_ "GenSigCycleTime" SG_ 378 ESP_TqDecSlowwhlFront 10;
BA_ "GenSigCycleTime" SG_ 378 ESP_TqDecFastwhlFront 10;
BA_ "GenSigCycleTime" SG_ 378 ESP_TorqIncwhlRear 10;
BA_ "GenSigCycleTime" SG_ 378 ESP_TorqIncwhlFront 10;
BA_ "GenSigCycleTime" SG_ 378 ESP_TCSFailStatus 10;
BA_ "GenSigCycleTime" SG_ 378 ESP_RollingCounter_1DF 10;
BA_ "GenSigCycleTime" SG_ 378 ESP_RollingCounter_1C8 10;
BA_ "GenSigCycleTime" SG_ 378 ESP_RollingCounter_1AC 10;
BA_ "GenSigCycleTime" SG_ 378 ESP_RollingCounter_197 10;
BA_ "GenSigCycleTime" SG_ 378 ESP_RollingCounter_187 10;
BA_ "GenSigCycleTime" SG_ 378 ESP_pMcVirtual_Q 10;
BA_ "GenSigCycleTime" SG_ 378 ESP_pMcVirtual 10;
BA_ "GenSigCycleTime" SG_ 378 ESP_MbRegenTarWhlRearQlfr 10;
BA_ "GenSigCycleTime" SG_ 378 ESP_MbRegenTarWhlRear 10;
BA_ "GenSigCycleTime" SG_ 378 ESP_MbRegenTarWhlFrontQlfr 10;
BA_ "GenSigCycleTime" SG_ 378 ESP_MbRegenTarWhlFront 10;
BA_ "GenSigCycleTime" SG_ 378 ESP_GearHoldRequestValid 10;
BA_ "GenSigCycleTime" SG_ 378 ESP_GearHoldRequest 10;
BA_ "GenSigInvalidValue" SG_ 378 ESP_GearHoldRequest "0";
BA_ "GenSigCycleTime" SG_ 378 ESP_ESPFunctionStatus 10;
BA_ "GenSigStartValue" SG_ 378 ESP_ESPFunctionStatus 1.000000;
BA_ "GenSigCycleTime" SG_ 378 ESP_ESPActiveStatus 10;
BA_ "GenSigCycleTime" SG_ 378 ESP_EngTorqIncRearActive 10;
BA_ "GenSigCycleTime" SG_ 378 ESP_EngTorqIncFrontActive 10;
BA_ "GenSigCycleTime" SG_ 378 ESP_EngTorqDecRearActive 10;
BA_ "GenSigCycleTime" SG_ 378 ESP_EngTorqDecFrontActive 10;
BA_ "GenSigCycleTime" SG_ 378 ESP_EBDFailStatus 10;
BA_ "GenSigCycleTime" SG_ 378 ESP_CRCCheck_1DF 10;
BA_ "GenSigCycleTime" SG_ 378 ESP_CRCCheck_1C8 10;
BA_ "GenSigCycleTime" SG_ 378 ESP_CRCCheck_1AC 10;
BA_ "GenSigCycleTime" SG_ 378 ESP_CRCCheck_197 10;
BA_ "GenSigCycleTime" SG_ 378 ESP_CRCCheck_187 10;
BA_ "GenSigCycleTime" SG_ 378 ESP_ADBF_Active 10;
BA_ "GenSigCycleTime" SG_ 378 ESP_ABSFailStatus 10;
BA_ "GenSigCycleTime" SG_ 378 ESP_ABSActiveStatus 10;
BA_ "GenSigCycleTime" SG_ 378 EPBi_MILReq 10;
BA_ "GenSigCycleTime" SG_ 378 EPBi_ClearDiagnosticInfo 10;

BA_ "GenSigCycleTime" SG_ 380 EMS_S58XGAPS 10;
BA_ "GenSigStartValue" SG_ 380 EMS_S58XGAPS 2.000000;
BA_ "GenSigInvalidValue" SG_ 380 EMS_S58XGAPS "63";
BA_ "GenSigCycleTime" SG_ 380 EMS_AntiJerkActive 10;
BA_ "GenSigCycleTime" SG_ 380 EMS_RollingCounter_17C 10;
BA_ "GenSigCycleTime" SG_ 380 EMS_CRCCheck_17C 10;
BA_ "GenSigCycleTime" SG_ 380 EMS_RollingCounter_1B7 10;
BA_ "GenSigCycleTime" SG_ 380 EMS_RngMod_trqCrSSetMinAvl 10;
BA_ "GenSigCycleTime" SG_ 380 EMS_RngMod_trqCrSSetMaxAvl 10;
BA_ "GenSigCycleTime" SG_ 380 EMS_RngMod_trqCrSLeadMinAvl 10;
BA_ "GenSigCycleTime" SG_ 380 EMS_RngMod_trqCrSLeadMaxAvl 10;
BA_ "GenSigCycleTime" SG_ 380 EMS_EngIdleTqFlywhMin 10;
BA_ "GenSigCycleTime" SG_ 380 EMS_CRCCheck_1B7 10;
BA_ "GenSigCycleTime" SG_ 380 EMS_RollingCounter_194 10;
BA_ "GenSigCycleTime" SG_ 380 EMS_IGNKL15Posn 10;
BA_ "GenSigCycleTime" SG_ 380 EMS_IdleCtrlSts 10;
BA_ "GenSigCycleTime" SG_ 380 EMS_EngTqFlywhFailr 10;
BA_ "GenSigCycleTime" SG_ 380 EMS_EngTqFlywh 10;
BA_ "GenSigStartValue" SG_ 380 EMS_EngTqFlywh 17500.000000;
BA_ "GenSigInvalidValue" SG_ 380 EMS_EngTqFlywh "65535";
BA_ "GenSigCycleTime" SG_ 380 EMS_EngSts 10;
BA_ "GenSigCycleTime" SG_ 380 EMS_EngStrtSuccess 10;
BA_ "GenSigCycleTime" SG_ 380 EMS_EngStopInhb 10;
BA_ "GenSigCycleTime" SG_ 380 EMS_EngSpdErr 10;
BA_ "GenSigCycleTime" SG_ 380 EMS_EngSpd 10;
BA_ "GenSigInvalidValue" SG_ 380 EMS_EngSpd "65535";
BA_ "GenSigCycleTime" SG_ 380 EMS_EngRunReq 10;
BA_ "GenSigCycleTime" SG_ 380 EMS_EngFuPumpSts 10;
BA_ "GenSigCycleTime" SG_ 380 EMS_EngFuCutOff 10;
BA_ "GenSigCycleTime" SG_ 380 EMS_CRCCheck_194 10;
BA_ "GenSigCycleTime" SG_ 380 EMS_RollingCounter_186 10;
BA_ "GenSigCycleTime" SG_ 380 EMS_EngTqLimitedFlag 10;
BA_ "GenSigCycleTime" SG_ 380 EMS_RngMod_trqCrSLimtSts 10;
BA_ "GenSigCycleTime" SG_ 380 EMS_RngMod_trqCrSLeadMin 10;
BA_ "GenSigCycleTime" SG_ 380 EMS_InterCoolerMotLopPumpSpdReq 10;
BA_ "GenSigCycleTime" SG_ 380 EMS_IdleSpdRef 10;
BA_ "GenSigStartValue" SG_ 380 EMS_IdleSpdRef 800.000000;
BA_ "GenSigCycleTime" SG_ 380 EMS_EngTqFric 10;
BA_ "GenSigCycleTime" SG_ 380 EMS_EngIdleTqFlywh 10;
BA_ "GenSigCycleTime" SG_ 380 EMS_CRCCheck_186 10;

BA_ "GenSigCycleTime" SG_ 381 PCU_MbRegenWhlTotalVld 10;
BA_ "GenSigCycleTime" SG_ 381 PCU_MbRegenWhlTotal 10;
BA_ "GenSigInvalidValue" SG_ 381 PCU_MbRegenWhlTotal "65535";
BA_ "GenSigCycleTime" SG_ 381 PCU_VehWhlReqTqVld 10;
BA_ "GenSigInvalidValue" SG_ 381 PCU_VehWhlReqTqVld "1";
BA_ "GenSigCycleTime" SG_ 381 PCU_VehWhlReqTq 10;
BA_ "GenSigInvalidValue" SG_ 381 PCU_VehWhlReqTq "32767";
BA_ "GenSigCycleTime" SG_ 381 PCU_ReWhlReqTqVld 10;
BA_ "GenSigInvalidValue" SG_ 381 PCU_ReWhlReqTqVld "1";
BA_ "GenSigCycleTime" SG_ 381 PCU_FrntWhlReqTqVld 10;
BA_ "GenSigInvalidValue" SG_ 381 PCU_FrntWhlReqTqVld "1";
BA_ "GenSigCycleTime" SG_ 381 PCU_ReWhlActTqVld 10;
BA_ "GenSigInvalidValue" SG_ 381 PCU_ReWhlActTqVld "1";
BA_ "GenSigCycleTime" SG_ 381 PCU_FrntWhlActTqVld 10;
BA_ "GenSigInvalidValue" SG_ 381 PCU_FrntWhlActTqVld "1";
BA_ "GenSigCycleTime" SG_ 381 PCU_MbRegenMaxRearWhlVld 10;
BA_ "GenSigCycleTime" SG_ 381 PCU_EngTarSpdReqVld 10;
BA_ "GenSigInvalidValue" SG_ 381 PCU_EngTarSpdReqVld "1";
BA_ "GenSigCycleTime" SG_ 381 PCU_RollingCounter_17D 10;
BA_ "GenSigCycleTime" SG_ 381 PCU_CRCCheck_17D 10;
BA_ "GenSigCycleTime" SG_ 381 PCU_RollingCounter_1C4 10;
BA_ "GenSigCycleTime" SG_ 381 PCU_RearMotSts 10;
BA_ "GenSigCycleTime" SG_ 381 PCU_PwrIndcdRealTqRearWhl 10;
BA_ "GenSigInvalidValue" SG_ 381 PCU_PwrIndcdRealTqRearWhl "32767";
BA_ "GenSigCycleTime" SG_ 381 PCU_PwrIndcdDrvrReqTqWhlRear 10;
BA_ "GenSigInvalidValue" SG_ 381 PCU_PwrIndcdDrvrReqTqWhlRear "32767";
BA_ "GenSigCycleTime" SG_ 381 PCU_ESPTqReqAvlRear 10;
BA_ "GenSigCycleTime" SG_ 381 PCU_CRCCheck_1C4 10;
BA_ "GenSigCycleTime" SG_ 381 PCU_RollingCounter_1BE 10;
BA_ "GenSigCycleTime" SG_ 381 PCU_MbRegenWhlRear 10;
BA_ "GenSigInvalidValue" SG_ 381 PCU_MbRegenWhlRear "65535";
BA_ "GenSigCycleTime" SG_ 381 PCU_MbRegenMaxWhlTotal 10;
BA_ "GenSigInvalidValue" SG_ 381 PCU_MbRegenMaxWhlTotal "65535";
BA_ "GenSigCycleTime" SG_ 381 PCU_MbRegenMaxRearWhl 10;
BA_ "GenSigInvalidValue" SG_ 381 PCU_MbRegenMaxRearWhl "65535";
BA_ "GenSigCycleTime" SG_ 381 PCU_CRCCheck_1BE 10;
BA_ "GenSigCycleTime" SG_ 381 PCU_PwrTrainSts 10;
BA_ "GenSigInvalidValue" SG_ 381 PCU_PwrTrainSts "3";
BA_ "GenSigCycleTime" SG_ 381 PCU_BrkPedlSts 10;
BA_ "GenSigCycleTime" SG_ 381 PCU_RollingCounter_1A6 10;
BA_ "GenSigCycleTime" SG_ 381 PCU_MbRegenWhlFront 10;
BA_ "GenSigInvalidValue" SG_ 381 PCU_MbRegenWhlFront "65535";
BA_ "GenSigCycleTime" SG_ 381 PCU_MbRegenMaxWhlQlfr 10;
BA_ "GenSigCycleTime" SG_ 381 PCU_MbRegenMaxFrontWhlVld 10;
BA_ "GenSigCycleTime" SG_ 381 PCU_MbRegenMaxFrontWhl 10;
BA_ "GenSigCycleTime" SG_ 381 PCU_CRCCheck_1A6 10;
BA_ "GenSigCycleTime" SG_ 381 PCU_APATorqRequestAvailable 10;
BA_ "GenSigCycleTime" SG_ 381 PCU_APARequestEnable 10;
BA_ "GenSigInvalidValue" SG_ 381 PCU_APARequestEnable "3";
BA_ "GenSigCycleTime" SG_ 381 PCU_AccPedlVld 10;
BA_ "GenSigCycleTime" SG_ 381 PCU_AccPedl 10;
BA_ "GenSigCycleTime" SG_ 381 PCU_StartStopActiveVld 10;
BA_ "GenSigCycleTime" SG_ 381 PCU_StartStopActive 10;
BA_ "GenSigCycleTime" SG_ 381 PCU_RollingCounter_211 10;
BA_ "GenSigCycleTime" SG_ 381 PCU_RearMotStsVld 10;
BA_ "GenSigCycleTime" SG_ 381 PCU_QECACC 10;
BA_ "GenSigCycleTime" SG_ 381 PCU_PwrIndcdRealTqWhlFailr 10;
BA_ "GenSigInvalidValue" SG_ 381 PCU_PwrIndcdRealTqWhlFailr "1";
BA_ "GenSigCycleTime" SG_ 381 PCU_PwrIndcdRealTqFrontWhl 10;
BA_ "GenSigInvalidValue" SG_ 381 PCU_PwrIndcdRealTqFrontWhl "32767";
BA_ "GenSigCycleTime" SG_ 381 PCU_PwrIndcdDrvrReqTqWhlFront 10;
BA_ "GenSigInvalidValue" SG_ 381 PCU_PwrIndcdDrvrReqTqWhlFront "32767";
BA_ "GenSigCycleTime" SG_ 381 PCU_FrontMotStsVld 10;
BA_ "GenSigCycleTime" SG_ 381 PCU_FrontMotSts 10;
BA_ "GenSigCycleTime" SG_ 381 PCU_ESPTqReqAvlFront 10;
BA_ "GenSigCycleTime" SG_ 381 PCU_EngStsVld 10;
BA_ "GenSigCycleTime" SG_ 381 PCU_EngSts 10;
BA_ "GenSigCycleTime" SG_ 381 PCU_EngClutchStsVld 10;
BA_ "GenSigCycleTime" SG_ 381 PCU_EngClutchSts 10;
BA_ "GenSigCycleTime" SG_ 381 PCU_ECGPOvrd 10;
BA_ "GenSigCycleTime" SG_ 381 PCU_CRCCheck_211 10;
BA_ "GenSigCycleTime" SG_ 381 PCU_AccReqPossible 10;
BA_ "GenSigCycleTime" SG_ 381 RGearbox_ActualDrivingGear 10;
BA_ "GenSigInvalidValue" SG_ 381 RGearbox_ActualDrivingGear "3";
BA_ "GenSigCycleTime" SG_ 381 PCU_TrsmTarIdleSpdReq 10;
BA_ "GenSigStartValue" SG_ 381 PCU_TrsmTarIdleSpdReq 800.000000;
BA_ "GenSigCycleTime" SG_ 381 PCU_TarGearReqValid 10;
BA_ "GenSigCycleTime" SG_ 381 PCU_TarGearReq 10;
BA_ "GenSigInvalidValue" SG_ 381 PCU_TarGearReq "15";
BA_ "GenSigCycleTime" SG_ 381 PCU_SpdCtrlModSelect 10;
BA_ "GenSigCycleTime" SG_ 381 PCU_RollingCounter_1C6 10;
BA_ "GenSigCycleTime" SG_ 381 PCU_RealAccPedlVld 10;
BA_ "GenSigCycleTime" SG_ 381 PCU_RealAccPedl 10;
BA_ "GenSigCycleTime" SG_ 381 PCU_MILReq 10;
BA_ "GenSigCycleTime" SG_ 381 PCU_K3CluSts 10;
BA_ "GenSigCycleTime" SG_ 381 PCU_FlywhTqTransLoadActInvld 10;
BA_ "GenSigCycleTime" SG_ 381 PCU_FlywhTqTransLoadAct 10;
BA_ "GenSigCycleTime" SG_ 381 PCU_EngTarIdleSpdReq 10;
BA_ "GenSigStartValue" SG_ 381 PCU_EngTarIdleSpdReq 50.000000;
BA_ "GenSigCycleTime" SG_ 381 PCU_EngStrtMod 10;
BA_ "GenSigCycleTime" SG_ 381 PCU_CRCCheck_1C6 10;
BA_ "GenSigCycleTime" SG_ 381 PCU_ClrDiagcInfo 10;
BA_ "GenSigCycleTime" SG_ 381 PCU_StrtTrqCtl 10;
BA_ "GenSigCycleTime" SG_ 381 PCU_StrtInhb 10;
BA_ "GenSigCycleTime" SG_ 381 PCU_RollingCounter_1E1 10;
BA_ "GenSigCycleTime" SG_ 381 PCU_PtStsChrgCrp 10;
BA_ "GenSigCycleTime" SG_ 381 PCU_FuCutOffReq 10;
BA_ "GenSigCycleTime" SG_ 381 PCU_EngIgnAgIntvEnbl 10;
BA_ "GenSigCycleTime" SG_ 381 PCU_EngTqFlywhSlowReq 10;
BA_ "GenSigCycleTime" SG_ 381 PCU_EngTqFlywhReqVld 10;
BA_ "GenSigCycleTime" SG_ 381 PCU_EngTqFlywhFastReq 10;
BA_ "GenSigCycleTime" SG_ 381 PCU_EngTqFlywhAllwdMaxVld 10;
BA_ "GenSigCycleTime" SG_ 381 PCU_EngTqFlywhAllwdMax 10;
BA_ "GenSigCycleTime" SG_ 381 PCU_EngStrtOrd 10;
BA_ "GenSigCycleTime" SG_ 381 PCU_EngStpOrd 10;
BA_ "GenSigCycleTime" SG_ 381 PCU_EMSSurgeDamperEna 10;
BA_ "GenSigCycleTime" SG_ 381 PCU_CRCCheck_1E1 10;
BA_ "GenSigCycleTime" SG_ 381 PCU_BrkPedlSts2 10;
BA_ "GenSigCycleTime" SG_ 381 PCU_BrkPedlSts1 10;
BA_ "GenSigCycleTime" SG_ 381 PCU_VehSts 10;
BA_ "GenSigCycleTime" SG_ 381 PCU_VehSpdVld 10;
BA_ "GenSigCycleTime" SG_ 381 PCU_VehSpd 10;
BA_ "GenSigInvalidValue" SG_ 381 PCU_VehSpd "255";
BA_ "GenSigCycleTime" SG_ 381 PCU_SOCDisp 10;
BA_ "GenSigInvalidValue" SG_ 381 PCU_SOCDisp "127";
BA_ "GenSigCycleTime" SG_ 381 PCU_CRCID191 10;
BA_ "GenSigCycleTime" SG_ 381 PCU_ChrgUnlckILimReq 10;
BA_ "GenSigCycleTime" SG_ 381 PCU_ChrgSuspReq 10;
BA_ "GenSigCycleTime" SG_ 381 PCU_ChrgIReqLimFac 10;
BA_ "GenSigCycleTime" SG_ 381 PCU_ChrgAllwd 10;
BA_ "GenSigCycleTime" SG_ 381 PCU_CHMAsignalSts 10;
BA_ "GenSigCycleTime" SG_ 381 PCU_BMSOperModReq 10;
BA_ "GenSigInvalidValue" SG_ 381 PCU_BMSOperModReq "7";
BA_ "GenSigCycleTime" SG_ 381 PCU_BattIntrHeatAllwd 10;
BA_ "GenSigCycleTime" SG_ 381 PCU_ActHVPwrCnsExt 10;
BA_ "GenSigInvalidValue" SG_ 381 PCU_ActHVPwrCnsExt "255";
BA_ "GenSigCycleTime" SG_ 381 PCU_191CycCntr 10;
BA_ "GenSigInvalidValue" SG_ 381 PCU_191CycCntr "15";

BA_ "GenSigCycleTime" SG_ 271 IBCU_sOutputRodDriver_Q 10;
BA_ "GenSigCycleTime" SG_ 271 IBCU_sOutputRodDriver 10;
BA_ "GenSigCycleTime" SG_ 271 IBCU_sOutputRodAct_Q 10;
BA_ "GenSigCycleTime" SG_ 271 IBCU_sOutputRodAct 10;
BA_ "GenSigCycleTime" SG_ 271 IBCU_RollingCounter_1CB 10;
BA_ "GenSigCycleTime" SG_ 271 IBCU_MILReq 10;
BA_ "GenSigCycleTime" SG_ 271 IBCU_ExtReqStatus 10;
BA_ "GenSigCycleTime" SG_ 271 IBCU_ExtReqPrio 10;
BA_ "GenSigCycleTime" SG_ 271 IBCU_CRCCheck_1CB 10;
BA_ "GenSigCycleTime" SG_ 271 IBCU_ClearDiagnosticInfo 10;
BA_ "GenSigCycleTime" SG_ 271 IBCU_BrakeModeFeedBack 10;
BA_ "GenSigCycleTime" SG_ 271 IBCU_BrakeModeEnable 10;

BA_ "GenSigCycleTime" SG_ 523 IBCU_BrkPedlStsGbVld 20;
BA_ "GenSigInvalidValue" SG_ 523 IBCU_BrkPedlStsGbVld "2";
BA_ "GenSigCycleTime" SG_ 523 IBCU_BrkPedoplStsGb 20;
BA_ "GenSigInvalidValue" SG_ 523 IBCU_BrkPedoplStsGb "255";
BA_ "GenSigCycleTime" SG_ 523 ESP_RollingCounter_20B 20;
BA_ "GenSigCycleTime" SG_ 523 ESP_CRCCheck_20B 20;
BA_ "GenSigCycleTime" SG_ 523 IBCU_DTCAvailable 20;
BA_ "GenSigCycleTime" SG_ 523 Wheel_Speed_FL_Pulse 20;
BA_ "GenSigInvalidValue" SG_ 523 Wheel_Speed_FL_Pulse "255";
BA_ "GenSigCycleTime" SG_ 523 Wheel_Speed_FR_Pulse 20;
BA_ "GenSigInvalidValue" SG_ 523 Wheel_Speed_FR_Pulse "255";
BA_ "GenSigCycleTime" SG_ 523 ESP_MasCylBraPreByDriver 20;
BA_ "GenSigInvalidValue" SG_ 523 ESP_MasCylBraPreByDriver "4095";
BA_ "GenSigCycleTime" SG_ 523 ESP_MasCylBraPreByDriverValid 20;
BA_ "GenSigCycleTime" SG_ 523 ESP_Vehicle_Speed_Reference 20;
BA_ "GenSigInvalidValue" SG_ 523 ESP_Vehicle_Speed_Reference "8191";
BA_ "GenSigCycleTime" SG_ 523 IBCU_precheckStatus 20;
BA_ "GenSigCycleTime" SG_ 523 ESP_PrefillforAPA_Available 20;
BA_ "GenSigCycleTime" SG_ 523 ESP_PrefillforAPA_active 20;
BA_ "GenSigCycleTime" SG_ 523 IBCU_BrakeDiscHighTempWarning 20;
BA_ "GenSigCycleTime" SG_ 523 Wheel_SpeedPulseTimeStamp_FL 20;
BA_ "GenSigCycleTime" SG_ 523 Wheel_SpeedPulseTimeStamp_FR 20;
BA_ "GenSigCycleTime" SG_ 523 ESP_DTV_Available 20;
BA_ "GenSigCycleTime" SG_ 523 ESP_DTV_Active 20;
BA_ "GenSigCycleTime" SG_ 523 Wheel_Speed_RR_Pulse 20;
BA_ "GenSigInvalidValue" SG_ 523 Wheel_Speed_RR_Pulse "255";
BA_ "GenSigCycleTime" SG_ 523 Wheel_Speed_RR_Direction 20;
BA_ "GenSigCycleTime" SG_ 523 Wheel_Speed_RR_Data 20;
BA_ "GenSigInvalidValue" SG_ 523 Wheel_Speed_RR_Data "8191";
BA_ "GenSigCycleTime" SG_ 523 Wheel_Speed_RL_Valid_Data 20;
BA_ "GenSigInvalidValue" SG_ 523 Wheel_Speed_RL_Valid_Data "1";
BA_ "GenSigCycleTime" SG_ 523 Wheel_Speed_RL_Pulse 20;
BA_ "GenSigInvalidValue" SG_ 523 Wheel_Speed_RL_Pulse "255";
BA_ "GenSigCycleTime" SG_ 523 Wheel_Speed_RL_Direction 20;
BA_ "GenSigInvalidValue" SG_ 523 Wheel_Speed_RL_Direction "3";
BA_ "GenSigCycleTime" SG_ 523 Wheel_Speed_RL_Data 20;
BA_ "GenSigInvalidValue" SG_ 523 Wheel_Speed_RL_Data "8191";
BA_ "GenSigCycleTime" SG_ 523 Wheel_Speed_FR_Valid_Data 20;
BA_ "GenSigInvalidValue" SG_ 523 Wheel_Speed_FR_Valid_Data "1";
BA_ "GenSigCycleTime" SG_ 523 Wheel_Speed_FR_Pulse 20;
BA_ "GenSigInvalidValue" SG_ 523 Wheel_Speed_FR_Pulse "255";
BA_ "GenSigCycleTime" SG_ 523 Wheel_Speed_FR_Direction 20;
BA_ "GenSigInvalidValue" SG_ 523 Wheel_Speed_FR_Direction "3";
BA_ "GenSigCycleTime" SG_ 523 Wheel_Speed_FR_Data 20;
BA_ "GenSigInvalidValue" SG_ 523 Wheel_Speed_FR_Data "8191";
BA_ "GenSigCycleTime" SG_ 523 Wheel_Speed_FL_Valid_Data 20;
BA_ "GenSigInvalidValue" SG_ 523 Wheel_Speed_FL_Valid_Data "1";
BA_ "GenSigCycleTime" SG_ 523 Wheel_Speed_FL_Direction 20;
BA_ "GenSigInvalidValue" SG_ 523 Wheel_Speed_FL_Direction "3";
BA_ "GenSigCycleTime" SG_ 523 Wheel_Speed_FL_Data 20;
BA_ "GenSigInvalidValue" SG_ 523 Wheel_Speed_FL_Data "8191";
BA_ "GenSigCycleTime" SG_ 523 ESP_QDCACC 20;
BA_ "GenSigCycleTime" SG_ 523 ESP_MasCylBrakePressureValid 20;
BA_ "GenSigCycleTime" SG_ 523 ESP_MasCylBrakePressure 20;
BA_ "GenSigInvalidValue" SG_ 523 ESP_MasCylBrakePressure "4095";
BA_ "GenSigCycleTime" SG_ 523 ESP_HHC_Available 20;
BA_ "GenSigCycleTime" SG_ 523 ESP_HHC_Active 20;
BA_ "GenSigCycleTime" SG_ 523 ESP_ECDAvailable 20;
BA_ "GenSigCycleTime" SG_ 523 ESP_ECDActive 20;
BA_ "GenSigCycleTime" SG_ 523 ESP_CRCCheck_208 20;
BA_ "GenSigCycleTime" SG_ 523 ESP_CRCCheck_206 20;
BA_ "GenSigCycleTime" SG_ 523 ESP_BrakeLightOnRequest 20;
BA_ "GenSigInvalidValue" SG_ 523 ESP_BrakeLightOnRequest "3";
BA_ "GenSigCycleTime" SG_ 523 ESP_AutoHoldStandby 20;
BA_ "GenSigCycleTime" SG_ 523 ESP_AutoHoldAvailable 20;
BA_ "GenSigCycleTime" SG_ 523 ESP_AutoHoldActive 20;
BA_ "GenSigCycleTime" SG_ 523 ABS_TODFastOpenRequest 20;
BA_ "GenSigInvalidValue" SG_ 523 ABS_TODFastOpenRequest "3";
BA_ "GenSigCycleTime" SG_ 523 ESP_CDP_ParkingActiveForACC 20;
BA_ "GenSigStartValue" SG_ 523 ESP_CDP_ParkingActiveForACC 1.000000;
BA_ "GenSigCycleTime" SG_ 523 ESP_CDP_ParkingAvailForACC 20;
BA_ "GenSigCycleTime" SG_ 523 ESP_IncreasePressureReqOK 20;
BA_ "GenSigInvalidValue" SG_ 523 ESP_IncreasePressureReqOK "0";
BA_ "GenSigCycleTime" SG_ 523 ESP_OnlyABSActive 20;
BA_ "GenSigCycleTime" SG_ 523 ESP_TCSActive 20;
BA_ "GenSigCycleTime" SG_ 523 ESP_VDCActive 20;
BA_ "GenSigCycleTime" SG_ 523 ESP_HBBActiveStatus 20;
BA_ "GenSigCycleTime" SG_ 523 ESP_HDC_STATUS 20;
BA_ "GenSigInvalidValue" SG_ 523 ESP_HDC_STATUS "3";
BA_ "GenSigCycleTime" SG_ 523 ESP_CDD_Available_APA 20;
BA_ "GenSigCycleTime" SG_ 523 ESP_CDD_Active_APA 20;
BA_ "GenSigCycleTime" SG_ 523 ESP_UrgencyBrakeAlarm 20;
BA_ "GenSigCycleTime" SG_ 523 Wheel_Speed_RR_Valid_Data 20;
BA_ "GenSigInvalidValue" SG_ 523 Wheel_Speed_RR_Valid_Data "1";
BA_ "GenSigCycleTime" SG_ 523 ESP_RollingCounter_208 20;
BA_ "GenSigCycleTime" SG_ 523 Wheel_Speed_FL_Pulse 20;
BA_ "GenSigInvalidValue" SG_ 523 Wheel_Speed_FL_Pulse "255";
BA_ "GenSigCycleTime" SG_ 523 ESP_RollingCounter_258 20;
BA_ "GenSigCycleTime" SG_ 523 ESP_CRCCheck_258 20;
BA_ "GenSigCycleTime" SG_ 523 ESP_RollingCounter_206 20;
BA_ "GenSigCycleTime" SG_ 523 ESP_CRCCheck_277 20;
BA_ "GenSigCycleTime" SG_ 523 ESP_RollingCounter_277 20;
BA_ "GenSigCycleTime" SG_ 523 ESP_VehicleStandstill 20;
BA_ "GenSigCycleTime" SG_ 523 ESP_PrefillAvailable 20;
BA_ "GenSigCycleTime" SG_ 523 ESP_PrefillActive 20;
BA_ "GenSigCycleTime" SG_ 523 ESP_BrakeForce 20;
BA_ "GenSigCycleTime" SG_ 523 ESP_CDD_Available 20;
BA_ "GenSigCycleTime" SG_ 523 ESP_CDD_Active 20;
BA_ "GenSigCycleTime" SG_ 523 ESP_BrakeOverHeatBrakeDiscTemp 20;
BA_ "GenSigCycleTime" SG_ 523 ESP_AWBavailable 20;
BA_ "GenSigCycleTime" SG_ 523 ESP_AWBactive 20;
BA_ "GenSigCycleTime" SG_ 523 ESP_AEBdecActive 20;
BA_ "GenSigCycleTime" SG_ 523 ESP_AEBAvailable 20;
BA_ "GenSigCycleTime" SG_ 523 ESP_ABAavailable 20;
BA_ "GenSigCycleTime" SG_ 523 ESP_ABAactive 20;
BA_ "GenSigCycleTime" SG_ 523 ESP_TODTorqueMaxLimit 20;
BA_ "GenSigInvalidValue" SG_ 523 ESP_TODTorqueMaxLimit "4095";

BA_ "GenSigCycleTime" SG_ 651 BCM_DrvrSts 40;
BA_ "GenSigInvalidValue" SG_ 651 BCM_DrvrSts "NA";
BA_ "GenSigCycleTime" SG_ 651 BCM_RefuelReq 40;
BA_ "GenSigCycleTime" SG_ 651 BCM_TrunkReleaseTrigger 40;
BA_ "GenSigInvalidValue" SG_ 651 BCM_TrunkReleaseTrigger "0";
BA_ "GenSigCycleTime" SG_ 651 BCM_LockTrigger 40;
BA_ "GenSigInvalidValue" SG_ 651 BCM_LockTrigger "0";
BA_ "GenSigCycleTime" SG_ 651 BCM_UnlockTrigger 40;
BA_ "GenSigInvalidValue" SG_ 651 BCM_UnlockTrigger "0";
BA_ "GenSigCycleTime" SG_ 651 BCM_TurnIndicatorLeft 40;
BA_ "GenSigInvalidValue" SG_ 651 BCM_TurnIndicatorLeft "3";
BA_ "GenSigCycleTime" SG_ 651 BCM_TurnIndicatorRight 40;
BA_ "GenSigInvalidValue" SG_ 651 BCM_TurnIndicatorRight "3";
BA_ "GenSigCycleTime" SG_ 651 PEPS_ShiftForbidRq 40;
BA_ "GenSigInvalidValue" SG_ 651 PEPS_ShiftForbidRq "0";
BA_ "GenSigCycleTime" SG_ 651 PEPS_RemoteStartReq 40;
BA_ "GenSigInvalidValue" SG_ 651 PEPS_RemoteStartReq "3";
BA_ "GenSigCycleTime" SG_ 651 BCM_PowerStatusFeedback 40;
BA_ "GenSigCycleTime" SG_ 651 BCM_DriverDoorStatus 40;
BA_ "GenSigCycleTime" SG_ 651 BCM_HoodStatus 40;
BA_ "GenSigCycleTime" SG_ 651 PEPS_StartControlsignal 40;
BA_ "GenSigInvalidValue" SG_ 651 PEPS_StartControlsignal "3";
BA_ "GenSigCycleTime" SG_ 651 BCM_TurnLightSwitchSts 40;
BA_ "GenSigInvalidValue" SG_ 651 BCM_TurnLightSwitchSts "3";

BA_ "GenSigCycleTime" SG_ 724 APA_RADSNotice 40;
BA_ "GenSigInvalidValue" SG_ 724 APA_RADSNotice "31";
BA_ "GenSigCycleTime" SG_ 724 APA_Right_BSD_LCAAlert 40;
BA_ "GenSigCycleTime" SG_ 724 APA_Left_BSD_LCAAlert 40;
BA_ "GenSigCycleTime" SG_ 724 APA_PEPS_EngineOffRequest 40;
BA_ "GenSigCycleTime" SG_ 724 APA_PowerMirrorFoldReq 40;
BA_ "GenSigCycleTime" SG_ 724 APA_LAEBReq 40;
BA_ "GenSigCycleTime" SG_ 724 APA_NumberofParkingSlot 40;
BA_ "GenSigCycleTime" SG_ 724 APA_ParkingModeAvailableSts 40;
BA_ "GenSigCycleTime" SG_ 724 APA_vehicleFrontdetect 40;
BA_ "GenSigInvalidValue" SG_ 724 APA_vehicleFrontdetect "3";
BA_ "GenSigCycleTime" SG_ 724 APA_BCMHornCommand 40;
BA_ "GenSigInvalidValue" SG_ 724 APA_BCMHornCommand "0";
BA_ "GenSigCycleTime" SG_ 724 APA_PEPS_EngineOffLockRequest 40;
BA_ "GenSigCycleTime" SG_ 724 APA_CrossModeSelectReq 40;
BA_ "GenSigInvalidValue" SG_ 724 APA_CrossModeSelectReq "0";
BA_ "GenSigCycleTime" SG_ 724 APA_ASPStatus 40;
BA_ "GenSigInvalidValue" SG_ 724 APA_ASPStatus "7";
BA_ "GenSigCycleTime" SG_ 724 APA_ASPAvailableStatus 40;
BA_ "GenSigCycleTime" SG_ 724 APA_RemoteParkingUsingRemind 40;
BA_ "GenSigInvalidValue" SG_ 724 APA_RemoteParkingUsingRemind "0";
BA_ "GenSigCycleTime" SG_ 724 APA_BLEConnectionRemind 40;
BA_ "GenSigInvalidValue" SG_ 724 APA_BLEConnectionRemind "0";
BA_ "GenSigCycleTime" SG_ 724 APA_ReleasePressureReq 40;
BA_ "GenSigInvalidValue" SG_ 724 APA_ReleasePressureReq "0";
BA_ "GenSigCycleTime" SG_ 724 APA_CRCCheck_2D4 40;
BA_ "GenSigCycleTime" SG_ 724 APA_RollingCounter_2D4 40;
BA_ "GenSigCycleTime" SG_ 724 APA_LAEBNotice 40;
BA_ "GenSigCycleTime" SG_ 724 APA_LAEBStatus 40;
BA_ "GenSigCycleTime" SG_ 724 APA_ParkNotice_5 40;
BA_ "GenSigInvalidValue" SG_ 724 APA_ParkNotice_5 "17";

BA_ "GenSigCycleTime" SG_ 734 IP_WholeTermClrFlg 50;
BA_ "GenSigCycleTime" SG_ 734 IP_CRCCheck_2DE 50;
BA_ "GenSigCycleTime" SG_ 734 IP_RollingCounter_2DE 50;
BA_ "GenSigCycleTime" SG_ 734 IP_DriverLCDALEDSts 50;
BA_ "GenSigInvalidValue" SG_ 734 IP_DriverLCDALEDSts "0";
BA_ "GenSigCycleTime" SG_ 734 IP_PassengerLCDALEDSts 50;
BA_ "GenSigInvalidValue" SG_ 734 IP_PassengerLCDALEDSts "0";
BA_ "GenSigCycleTime" SG_ 734 IP_DISFail 50;
BA_ "GenSigInvalidValue" SG_ 734 IP_DISFail "0";
BA_ "GenSigCycleTime" SG_ 734 IP_QDashACCFail 50;
BA_ "GenSigInvalidValue" SG_ 734 IP_QDashACCFail "0";

BA_ "GenSigCycleTime" SG_ 742 EMS_InhbParallel 50;
BA_ "GenSigCycleTime" SG_ 742 EMS_EngStartFailRestSts 50;
BA_ "GenSigCycleTime" SG_ 742 EMS_WarmUpCycle 50;
BA_ "GenSigCycleTime" SG_ 742 EMS_SecIgnitionCyclesCounter 50;
BA_ "GenSigInvalidValue" SG_ 742 EMS_SecIgnitionCyclesCounter "1";
BA_ "GenSigCycleTime" SG_ 742 EMS_RollingCounter_2E6 50;
BA_ "GenSigCycleTime" SG_ 742 EMS_LoBattU 50;
BA_ "GenSigCycleTime" SG_ 742 EMS_LoBattErr 50;
BA_ "GenSigCycleTime" SG_ 742 EMS_IgnitionCyclesCounterValid 50;
BA_ "GenSigInvalidValue" SG_ 742 EMS_IgnitionCyclesCounterValid "1";
BA_ "GenSigCycleTime" SG_ 742 EMS_GeneralDenoStatusValid 50;
BA_ "GenSigInvalidValue" SG_ 742 EMS_GeneralDenoStatusValid "1";
BA_ "GenSigCycleTime" SG_ 742 EMS_GeneralDenominatorStatus 50;
BA_ "GenSigInvalidValue" SG_ 742 EMS_GeneralDenominatorStatus "1";
BA_ "GenSigCycleTime" SG_ 742 EMS_FirstIgnitionCycleCounter 50;
BA_ "GenSigInvalidValue" SG_ 742 EMS_FirstIgnitionCycleCounter "1";
BA_ "GenSigCycleTime" SG_ 742 EMS_EngTCoolt 50;
BA_ "GenSigCycleTime" SG_ 742 EMS_EngineIntakeAirTemp 50;
BA_ "GenSigCycleTime" SG_ 742 EMS_DrivingCycle 50;
BA_ "GenSigCycleTime" SG_ 742 EMS_CRCCheck_2E6 50;
BA_ "GenSigCycleTime" SG_ 742 EMS_CooltTErr 50;
BA_ "GenSigCycleTime" SG_ 742 EMS_Coolreq 50;
BA_ "GenSigCycleTime" SG_ 742 EMS_CatalystWarmUp 50;
BA_ "GenSigCycleTime" SG_ 742 EMS_AltitudeFactorValid 50;
BA_ "GenSigInvalidValue" SG_ 742 EMS_AltitudeFactorValid "1";
BA_ "GenSigCycleTime" SG_ 742 EMS_AltitudeFactor 50;
BA_ "GenSigStartValue" SG_ 742 EMS_AltitudeFactor 63.000000;
BA_ "GenSigInvalidValue" SG_ 742 EMS_AltitudeFactor "255";

BA_ "GenSigCycleTime" SG_ 812 TMS_Heater_pump_Spd_Req 100;
BA_ "GenSigInvalidValue" SG_ 812 TMS_Heater_pump_Spd_Req "127";
BA_ "GenSigCycleTime" SG_ 812 TMS_Motor_pump_Spd_Req 100;
BA_ "GenSigInvalidValue" SG_ 812 TMS_Motor_pump_Spd_Req "127";
BA_ "GenSigCycleTime" SG_ 812 TMS_WarmLoopSts 100;
BA_ "GenSigCycleTime" SG_ 812 TMS_PwrAct 100;
BA_ "GenSigCycleTime" SG_ 812 TMS_OperMod 100;
BA_ "GenSigStartValue" SG_ 812 TMS_OperMod 1.000000;
BA_ "GenSigCycleTime" SG_ 812 TMS_Motor_pump_Actv 100;
BA_ "GenSigCycleTime" SG_ 812 TMS_MotCoolngLoopSts 100;
BA_ "GenSigCycleTime" SG_ 812 TMS_IntercolerLoopSts 100;
BA_ "GenSigCycleTime" SG_ 812 TMS_IntecoolerpumpActv 100;
BA_ "GenSigCycleTime" SG_ 812 TMS_Heater_valveSts 100;
BA_ "GenSigCycleTime" SG_ 812 TMS_Evap_valveSts 100;
BA_ "GenSigCycleTime" SG_ 812 TMS_EngEnableReq 100;
BA_ "GenSigCycleTime" SG_ 812 TMS_CoolingFanSts 100;
BA_ "GenSigCycleTime" SG_ 812 TMS_BpumpActv 100;
BA_ "GenSigCycleTime" SG_ 812 TMS_BCoolActv 100;
BA_ "GenSigCycleTime" SG_ 812 TMS_BattCoolngLoopSts 100;
BA_ "GenSigCycleTime" SG_ 812 TMS_PEU_pump_Spd_Req 100;
BA_ "GenSigInvalidValue" SG_ 812 TMS_PEU_pump_Spd_Req "127";
BA_ "GenSigCycleTime" SG_ 812 TMS_RaceModSwSts 100;

VAL_ 378 Wheel_Speed_RL_Valid_Data 0 "Valid" 1 "NotValid";
VAL_ 378 Wheel_Speed_RR_Valid_Data 0 "Valid" 1 "NotValid";
VAL_ 378 ESP_VDCActive 0 "NotActive" 1 "Active";
VAL_ 378 ESP_TCSActive 0 "NotActive" 1 "Active";
VAL_ 378 ESP_ElectricBoostFailStatus 0 "No request to the warning lamp" 1 "Yellow requested" 2 "Red requested" 3 "Reserved";
VAL_ 378 ESP_MbRegenTarWhlTotalQlfr 0 "NotIntialized" 1 "Normal" 2 "Faulty";
VAL_ 378 ESP_RollerbenchType 0 "Passive" 1 "Unknown" 2 "FrontAxle" 3 "RearAxle" 4 "TwoAxle" 5 "Road" 6 "Reserve" 7 "Reserve";
VAL_ 378 IBCU_BrakeFluid_Warning 0 "Normal" 1 "low" 2 "empty/Reserved" 3 "Invalid";
VAL_ 378 ESP_VehicleSpeedValid2 0 "VehicleSpeedQualifier_NotInit" 1 "VehicleSpeedQualifier_Normal" 2 "VehicleSpeedQualifier_Faulty";
VAL_ 378 ESP_VehicleSpeedValid 0 "Valid" 1 "NotValid";
VAL_ 378 ESP_VehicleSpeed 0 "0~360km/h" 6401 "Reserved" 8191 "Invalid
APA2.0����";
VAL_ 378 ESP_TCSFailStatus 0 "Noerror" 1 "Error";
VAL_ 378 ESP_pMcVirtual_Q 0 " pMcVirtual_NotInitializedδ��ʼ��" 1 " pMcVirtual_Normal����" 2 " pMcVirtual_Faulty����";
VAL_ 378 ESP_MbRegenTarWhlRearQlfr 2 "Faulty" 1 "Normal" 0 "NotIntialized";
VAL_ 378 ESP_MbRegenTarWhlFrontQlfr 2 "Faulty" 1 "Normal" 0 "NotIntialized";
VAL_ 378 ESP_GearHoldRequestValid 0 "Valid" 1 "NotValid";
VAL_ 378 ESP_GearHoldRequest 0 "NotRequest" 1 "Request";
VAL_ 378 ESP_ESPFunctionStatus 0 "OFF" 1 "ON";
VAL_ 378 ESP_ESPActiveStatus 0 "NotActive" 1 "Active";
VAL_ 378 ESP_EngTorqIncRearActive 1 "Active," 0 "NotActive,";
VAL_ 378 ESP_EngTorqIncFrontActive 0 "NotActive" 1 "Active";
VAL_ 378 ESP_EngTorqDecRearActive 0 "NotActive" 1 "Active";
VAL_ 378 ESP_EngTorqDecFrontActive 0 "NotActive" 1 "Active";
VAL_ 378 ESP_EBDFailStatus 0 "Noerror" 1 "Error";
VAL_ 378 ESP_ADBF_Active 0 "NotActive" 1 "Active";
VAL_ 378 ESP_ABSFailStatus 0 "Noerror" 1 "Error";
VAL_ 378 ESP_ABSActiveStatus 0 "NotActive" 1 "Active";
VAL_ 378 EPBi_MILReq 0 "Not Request" 1 "Request";
VAL_ 378 EPBi_ClearDiagnosticInfo 0 "Normal" 1 "Not used" 2 "EPBi request EMS to clear DiagnosticInfo" 3 "EPBi has cleared Diag info per EMS request";

VAL_ 380 EMS_S58XGAPS 0 "Ԥ��
0x1=Tooth1
0x2=Tooth2
��
0x3A=Tooth58
0x3B~0x3E=Reserved
0x3F=Invalid";
VAL_ 380 EMS_AntiJerkActive 1 "Active" 0 "NotActive";
VAL_ 380 EMS_IGNKL15Posn 1 "Yes" 0 "No";
VAL_ 380 EMS_IdleCtrlSts 1 "True" 0 "False";
VAL_ 380 EMS_EngTqFlywhFailr 0 "No error" 1 "Error";
VAL_ 380 EMS_EngSts 3 "Reserved" 2 "Running" 1 "Crank" 0 "Stop";
VAL_ 380 EMS_EngStrtSuccess 1 "Success" 0 "Not success";
VAL_ 380 EMS_EngStopInhb 3 "3rd priority" 2 "2nd priority" 1 "1st priority" 0 "no inhibit";
VAL_ 380 EMS_EngSpdErr 0 "No error" 1 "Error";
VAL_ 380 EMS_EngRunReq 3 "3rd priority" 2 "2nd priority" 1 "1st priority" 0 "no request";
VAL_ 380 EMS_EngFuPumpSts 3 "not used" 2 "Error" 1 "Work" 0 "Not work";
VAL_ 380 EMS_EngFuCutOff 1 "True" 0 "False";
VAL_ 380 EMS_EngTqLimitedFlag 0 "Not Achieved" 1 "Achieved";
VAL_ 380 EMS_RngMod_trqCrSLimtSts 1 "Not Valid" 0 "Valid";

VAL_ 381 PCU_MbRegenWhlTotalVld 0 "invalid" 1 "valid";
VAL_ 381 PCU_VehWhlReqTqVld 0 "valid" 1 "invalid";
VAL_ 381 PCU_ReWhlReqTqVld 0 "valid" 1 "invalid";
VAL_ 381 PCU_FrntWhlReqTqVld 0 "valid" 1 "invalid";
VAL_ 381 PCU_ReWhlActTqVld 0 "valid" 1 "invalid";
VAL_ 381 PCU_FrntWhlActTqVld 0 "valid" 1 "invalid";
VAL_ 381 PCU_MbRegenMaxRearWhlVld 0 "Invalid" 1 "Valid";
VAL_ 381 PCU_EngTarSpdReqVld 0 "valid" 1 "invalid";
VAL_ 381 PCU_RearMotSts 0 "Not Ready" 1 "Ready";
VAL_ 381 PCU_ESPTqReqAvlRear 1 "NotAvailable" 0 "Available";
VAL_ 381 PCU_PwrTrainSts 3 "Ԥ��" 2 "Running" 1 "Crank" 0 "Stop";
VAL_ 381 PCU_BrkPedlSts 0 "Not Pressed" 1 "Pressed" 2 "Reserved" 3 "Error";
VAL_ 381 PCU_MbRegenMaxWhlQlfr 2 "Faulty" 1 "Normal" 0 "NotIntialized";
VAL_ 381 PCU_MbRegenMaxFrontWhlVld 0 "Invalid" 1 "Valid";
VAL_ 381 PCU_APATorqRequestAvailable 1 "available" 0 "not available";
VAL_ 381 PCU_APARequestEnable 0 "no request" 1 "Control enabled" 2 " Control disable" 3 "invalid";
VAL_ 381 PCU_AccPedlVld 1 "invalid" 0 "valid";
VAL_ 381 PCU_StartStopActiveVld 0 "Invalid" 1 "Valid";
VAL_ 381 PCU_StartStopActive 0 "Not active�����������0" 1 "active����������������£��������ޱ����ͣ ����1";
VAL_ 381 PCU_RearMotStsVld 0 "Invalid" 1 "Valid";
VAL_ 381 PCU_QECACC 0 "no error" 1 "reversible error" 2 "irreversible error" 3 "not defined";
VAL_ 381 PCU_PwrIndcdRealTqWhlFailr 0 "valid" 1 "invalid";
VAL_ 381 PCU_FrontMotStsVld 0 "Invalid" 1 "Valid";
VAL_ 381 PCU_FrontMotSts 0 "Not Ready" 1 "Ready������޹��ϣ������������������";
VAL_ 381 PCU_ESPTqReqAvlFront 1 "NotAvailable" 0 "Available";
VAL_ 381 PCU_EngStsVld 0 "Invalid" 1 "Valid";
VAL_ 381 PCU_EngSts 0 "Not Ready" 1 "Ready(�������޹��ϣ���ת��������ת�ٸ��ڵ���ת��)";
VAL_ 381 PCU_EngClutchStsVld 0 "Invalid" 1 "Valid";
VAL_ 381 PCU_EngClutchSts 0 "Engaged " 1 "Disengaged";
VAL_ 381 PCU_ECGPOvrd 0 "no override" 1 "driver override";
VAL_ 381 PCU_AccReqPossible 0 "noerror" 1 "error";
VAL_ 381 RGearbox_ActualDrivingGear 0 "Neutral" 1 "1st gear" 2 "Initial " 3 "shift in progress";
VAL_ 381 PCU_TarGearReqValid 0 "Valid" 1 "Invalid";
VAL_ 381 PCU_TarGearReq 0 "Initial value" 1 "1st gear" 2 "2nd gear" 3 "3rd gear" 4 "4th gear" 5 "5th gear" 6 "6th gear" 7 "7th gear" 8 "8th gear" 9 "Reverse" 10 "Neutral" 11 "Reserved" 12 "Reserved" 14 "Reserved" 15 "Invalid";
VAL_ 381 PCU_SpdCtrlModSelect 3 "tq control mode select" 2 "fast speed select" 1 "idle control select" 0 "no mode select";
VAL_ 381 PCU_RealAccPedlVld 1 "invalid" 0 "valid";
VAL_ 381 PCU_MILReq 0 "not request" 1 "request";
VAL_ 381 PCU_K3CluSts 1 "not open" 0 "open";
VAL_ 381 PCU_FlywhTqTransLoadActInvld 1 "invalid" 0 "valid";
VAL_ 381 PCU_EngStrtMod 7 "ISG Start" 6 "BSG Start" 5 "Slip start" 4 "Pulse start" 3 "Creep start" 2 "Crank start" 1 "12V MOT start" 0 "No start";
VAL_ 381 PCU_ClrDiagcInfo 0 "Normal" 1 "Not used" 2 "PCU request EMS to clear P1872" 3 "PCU has cleared diagintoper EMS request";
VAL_ 381 PCU_StrtTrqCtl 1 "torque control during start" 0 "No torque control during start";
VAL_ 381 PCU_StrtInhb 1 "injection inhibition during start" 0 "No injection inhibition during start";
VAL_ 381 PCU_PtStsChrgCrp 3 "idle charge and creep" 2 "creep" 1 "idle charge" 0 "none";
VAL_ 381 PCU_FuCutOffReq 0 "Not request" 1 "Request";
VAL_ 381 PCU_EngIgnAgIntvEnbl 0 "unable" 1 "enable";
VAL_ 381 PCU_EngTqFlywhReqVld 1 "invalid" 0 "valid";
VAL_ 381 PCU_EngTqFlywhAllwdMaxVld 1 "invalid" 0 "valid";
VAL_ 381 PCU_EngStrtOrd 1 "Request" 0 "No trequest";
VAL_ 381 PCU_EngStpOrd 1 "Request" 0 "Not request";
VAL_ 381 PCU_EMSSurgeDamperEna 1 "enable" 0 "disable";
VAL_ 381 PCU_BrkPedlSts2 1 "Pressed" 0 "Not Pressed";
VAL_ 381 PCU_BrkPedlSts1 1 "Not Pressed" 0 "Pressed";
VAL_ 381 PCU_VehSts 0 "Standstill" 1 "EV Drive" 2 "Serial Drive" 3 "Parallel Drive" 4 "Regeneration" 5 " Parallel Charge" 6 "Idle Charge" 7 "Idle";
VAL_ 381 PCU_VehSpdVld 0 "Valid" 1 "NotValid";
VAL_ 381 PCU_ChrgUnlckILimReq 0 "not Limit" 1 "Limit";
VAL_ 381 PCU_ChrgSuspReq 0 "UnSuspend" 1 "Suspend";
VAL_ 381 PCU_ChrgIReqLimFac 0 "100%" 1 "70%" 2 "30%" 3 "0%";
VAL_ 381 PCU_ChrgAllwd 0 "notallow" 1 "allow";
VAL_ 381 PCU_CHMAsignalSts 0 "invalid" 1 "valid";
VAL_ 381 PCU_BMSOperModReq 0 "Initializing" 1 "Wakeup" 2 "PreCharge" 3 "HVActive" 4 "Powerdown" 5 "=Failure" 6 "Sleep";
VAL_ 381 PCU_BattIntrHeatAllwd 0 "notallow" 1 "allow";

VAL_ 271 IBCU_sOutputRodDriver_Q 0 "soutputRodDriver_NotInitializedδ��ʼ��" 1 "soutputRodDriver_Normal����" 2 "soutputRodDriver_Faulty����";
VAL_ 271 IBCU_sOutputRodAct_Q 0 "SoutputRodAct_NotInitialized" 1 "SoutputRodAct_Normal" 2 "SoutputRodAct_Faulty";
VAL_ 271 IBCU_MILReq 0 "Not request" 1 "Request";
VAL_ 271 IBCU_ExtReqStatus 0 "EBR_NotInitializedδ��ʼ��" 1 "EBR_NotAvailable ������" 2 "EBR_Available����";
VAL_ 271 IBCU_ExtReqPrio 0 "EBR is Not active or the driver dominates the brake torque�ⲿ�ƶ�����û�м�����ʻԱ�����ƶ�" 1 "EBR is active and dominates the brake torque�ⲿ�ƶ����󼤻���֧���ƶ���������";
VAL_ 271 IBCU_ClearDiagnosticInfo 0 "Normal" 1 "Not used" 2 "IBCU request EMS to clear DiagNosticInfo" 3 "IBCU has cleared Diag info per EMS request";
VAL_ 271 IBCU_BrakeModeFeedBack 0 "Inactive " 1 "Normal" 2 "Sport" 3 "Reserved";
VAL_ 271 IBCU_BrakeModeEnable 0 "display" 1 "No display";

VAL_ 523 IBCU_BrkPedlStsGbVld 0 "NotInitialized" 1 "Normal" 2 "Invalid";
VAL_ 523 IBCU_BrkPedoplStsGb 0 " �ƶ�δ����" 101 " �ƶ�����" 254 "�쳣";
VAL_ 523 IBCU_DTCAvailable 0 "not available" 1 "available" 2 "available without stable control";
VAL_ 523 ESP_MasCylBraPreByDriverValid 0 "Valid" 1 "Invalid";
VAL_ 523 ESP_Vehicle_Speed_Reference 0 "0~360km/h" 6401 "Reserved" 8191 "Invalid";
VAL_ 523 IBCU_precheckStatus 0 "not checked" 1 "in checking" 2 "checked" 3 "failed";
VAL_ 523 ESP_PrefillforAPA_Available 0 "notavailable" 1 "available";
VAL_ 523 ESP_PrefillforAPA_active 0 "notactive" 1 "active";
VAL_ 523 IBCU_BrakeDiscHighTempWarning 0 "no failure" 1 "OverheatLevel1" 2 "OverheatLevel2" 3 "reserved";
VAL_ 523 ESP_DTV_Available 0 "Available" 1 "Not Available";
VAL_ 523 ESP_DTV_Active 0 "Not Active" 1 "Active";
VAL_ 523 Wheel_Speed_RR_Direction 0 "Forward" 1 "backward" 2 "Standstill" 3 "Invalid";
VAL_ 523 Wheel_Speed_RL_Valid_Data 0 "Valid" 1 "NotValid";
VAL_ 523 Wheel_Speed_RL_Direction 0 "Forward" 1 "backward" 2 "Standstill" 3 "Invalid";
VAL_ 523 Wheel_Speed_FR_Valid_Data 0 "Valid" 1 "NotValid";
VAL_ 523 Wheel_Speed_FR_Direction 0 "Forward" 1 "backward" 2 "Standstill" 3 "Invalid";
VAL_ 523 Wheel_Speed_FL_Valid_Data 0 "Valid" 1 "NotValid";
VAL_ 523 Wheel_Speed_FL_Direction 0 "Forward" 1 "backward" 2 "Standstill" 3 "Invalid";
VAL_ 523 ESP_QDCACC 0 "noerror" 1 "error" 2 "reserved" 3 "reserved";
VAL_ 523 ESP_MasCylBrakePressureValid 0 "Valid" 1 "Invalid";
VAL_ 523 ESP_HHC_Available 0 "Available" 1 "NotAvailable";
VAL_ 523 ESP_HHC_Active 0 "functionisnotinactive" 1 "functionisinactive";
VAL_ 523 ESP_ECDAvailable 0 "Valid" 1 "Invalid";
VAL_ 523 ESP_ECDActive 0 "NotActive" 1 "Active";
VAL_ 523 ESP_BrakeLightOnRequest 0 "brakelightOFF" 1 "brakelightON" 2 "notused" 3 "signalnotavailable";
VAL_ 523 ESP_AutoHoldStandby 0 "NotActive" 1 "Active";
VAL_ 523 ESP_AutoHoldAvailable 0 "Valid" 1 "Invalid";
VAL_ 523 ESP_AutoHoldActive 0 "NotActive" 1 "Active";
VAL_ 523 ABS_TODFastOpenRequest 0 "Passive" 1 "OpenClutch" 2 "Torquemaxlimit" 3 "Error";
VAL_ 523 ESP_CDP_ParkingActiveForACC 0 "Active" 1 "not Active";
VAL_ 523 ESP_CDP_ParkingAvailForACC 0 "Available" 1 "not available";
VAL_ 523 ESP_IncreasePressureReqOK 0 "Not_OK" 1 "OK";
VAL_ 523 ESP_OnlyABSActive 0 "NotActive" 1 "Active";
VAL_ 523 ESP_TCSActive 0 "NotActive" 1 "Active";
VAL_ 523 ESP_VDCActive 0 "NotActive" 1 "Active";
VAL_ 523 ESP_HBBActiveStatus 0 "NotActive" 1 "Active";
VAL_ 523 ESP_HDC_STATUS 0 "OFF" 1 "ON" 2 "Standby" 3 "Error";
VAL_ 523 ESP_CDD_Available_APA 1 "available" 0 "notavailable";
VAL_ 523 ESP_CDD_Active_APA 1 "active" 0 "notactive";
VAL_ 523 ESP_UrgencyBrakeAlarm 0 "NotActive" 1 "Active";
VAL_ 523 Wheel_Speed_RR_Valid_Data 0 "Valid" 1 "NotValid";
VAL_ 523 ESP_VehicleStandstill 0 "notstandstill" 1 "standstill";
VAL_ 523 ESP_PrefillAvailable 0 "notavailable" 1 "available";
VAL_ 523 ESP_PrefillActive 0 "notactive" 1 "active";
VAL_ 523 ESP_BrakeForce 0 "nobrakeforce" 1 "havebrakeforce";
VAL_ 523 ESP_CDD_Available 0 "notavailable" 1 "available";
VAL_ 523 ESP_CDD_Active 0 "notactive" 1 "active";
VAL_ 523 ESP_BrakeOverHeatBrakeDiscTemp 0 "nothigh" 1 "temptoohigh";
VAL_ 523 ESP_AWBavailable 0 "notavailable" 1 "available";
VAL_ 523 ESP_AWBactive 0 "notactive" 1 "active";
VAL_ 523 ESP_AEBdecActive 0 "notactive" 1 "active";
VAL_ 523 ESP_AEBAvailable 0 "notavailable" 1 "available";
VAL_ 523 ESP_ABAavailable 0 "notavailable" 1 "available";
VAL_ 523 ESP_ABAactive 0 "notactive" 1 "active";

VAL_ 651 BCM_DrvrSts 0 "����" 1 "����";
VAL_ 651 BCM_RefuelReq 0 "������" 1 "������";
VAL_ 651 BCM_TrunkReleaseTrigger 0 "none" 1 "RKE���������" 2 "PKE���������" 3 "�������ⲿ���ؽ���" 4 "�������������" 5 "���������俪�ؽ���" 6 "Զ�����������" 7 "�������������" 8 "������Ӧ���������" 9 "����ʵ��Կ�����������";
VAL_ 651 BCM_LockTrigger 0 "none" 1 "RKE����" 2 "PKE����" 3 "�пر���" 4 "�ٶ�����" 5 "��������" 6 "��е����" 7 "Զ�̱���" 8 "��������" 9 "�복�Զ�����" 10 "HU����" 11 "APA�����" 12 "����ӭ������" 13 "���Ź��ܱ���" 14 "�綯����˫������" 15 "NFC����" 16 "UWBʵ��Կ�ױ���" 17 "Զ�����ֵƹ������" 18 "��������" 19 "�ּ�ӭ������";
VAL_ 651 BCM_UnlockTrigger 0 "none" 1 "RKE����" 2 "PKE����" 3 "�пؽ���" 4 "פ������" 5 "Կ���ڳ��ڽ���" 6 "��е����" 7 "Զ�̽���" 8 "��������" 9 "HU����" 10 "����ӭ������" 11 "���Ž�������" 12 "ACC��ȫͣ������" 13 "���Ź��ܽ���" 14 "NFC����" 15 "UWBʵ��Կ�׽���" 16 "Զ�����ֵƹ������" 17 "��������" 18 "�ּ�ӭ������";
VAL_ 651 BCM_TurnIndicatorLeft 0 "OFF" 1 "ON" 2 "Not used" 3 "Error";
VAL_ 651 BCM_TurnIndicatorRight 0 "OFF" 1 "ON" 2 "Not used" 3 "Error";
VAL_ 651 PEPS_ShiftForbidRq 0 "AllowShift" 1 "ForbidShift";
VAL_ 651 PEPS_RemoteStartReq 0 " Not Remote Start" 1 " Remote Start" 2 "Reserved" 3 "invalid";
VAL_ 651 BCM_PowerStatusFeedback 0 "OFF" 1 "ACC" 2 "ON" 3 "Start";
VAL_ 651 BCM_DriverDoorStatus 0 "Close" 1 "Open";
VAL_ 651 BCM_HoodStatus 0 "Close" 1 "Open";
VAL_ 651 PEPS_StartControlsignal 0 " No Request" 1 "Startup Start" 2 "Startup Stop" 3 " Invalid";
VAL_ 651 BCM_TurnLightSwitchSts 0 "Not Actived" 1 "Left Actived" 2 "Right Actived" 3 "Invalid";

VAL_ 724 APA_RADSNotice 0 "IDLE" 1 "No Path" 2 "Slope too high" 3 "Stop the car" 4 "Curve limiting" 5 "Close the door" 6 "Rain too high" 7 "Shift Gear to R" 8 " Brake Please" 9 "Release Steering" 10 "Please seat belt" 11 "insufficient light" 12 "System Runing" 13 "About to arrive at the destination" 14 "Successful System " 15 "System OUT By Switch " 16 "System OUT By Intervene" 17 "System OUT Door Out" 18 "Not wearing seat belt" 19 "Slope too high function cancel" 20 "Curve limit function cancel" 21 "Rain too high function cancel" 22 "SystemFailure function cancel" 23 "System out overtime for slpee too high " 24 "System out overtime for people" 25 "System out overtime for animal" 26 "System out overtime for car" 27 "System out overtime for obstacle" 28 "SystemFailure System OUT" 29 "System out for Engine stop" 30 "System out for brake" 31 "System out for shiftgears 0x20=System out for earlywarning" 34 "System out for light" 35 "PMO chose ELS auto mode" 36 "" 37 "" 38 "" 39 "" 40 "" 41 "Reserved" 63 "invalid";
VAL_ 724 APA_Right_BSD_LCAAlert 0 "No_LCA warning " 1 "LCA warning level 1" 2 " LCA warning level 2" 3 "Reserved";
VAL_ 724 APA_Left_BSD_LCAAlert 0 "No_LCA warning" 1 "LCA warning level 1" 2 " LCA warning level 2" 3 "Reserved";
VAL_ 724 APA_PEPS_EngineOffRequest 0 "Not Request" 1 "Request";
VAL_ 724 APA_PowerMirrorFoldReq 0 "" 1 "" 2 "Open" 3 "Reserved";
VAL_ 724 APA_LAEBReq 0 "" 1 "";
VAL_ 724 APA_NumberofParkingSlot 0 "idle" 1 "1" 2 "2" 3 "3" 4 "4" 5 "5" 6 "6" 7 "7" 8 "8" 9 "9" 10 "10" 11 "Reserved";
VAL_ 724 APA_ParkingModeAvailableSts 0 "idle" 1 "InteriorParkingMode" 2 "RemoteParkingMode" 3 "DoubleMode";
VAL_ 724 APA_vehicleFrontdetect 0 "No Detect" 1 "Detect" 2 "Reserved" 3 "Invalid";
VAL_ 724 APA_BCMHornCommand 0 "No Request" 1 "Request" 2 "Reserved" 3 "Invalid";
VAL_ 724 APA_PEPS_EngineOffLockRequest 0 "" 1 "";
VAL_ 724 APA_CrossModeSelectReq 0 "No Request" 1 "Request";
VAL_ 724 APA_ASPStatus 0 "Off" 1 "On" 2 "Abort" 3 "Finish" 4 "Suspend" 5 "Failure" 6 "Reserved" 7 "Invalid";
VAL_ 724 APA_ASPAvailableStatus 0 "Not Available" 1 " Available";
VAL_ 724 APA_RemoteParkingUsingRemind 0 "No GetOff Request" 1 "GetOff Request";
VAL_ 724 APA_BLEConnectionRemind 0 "No Request" 1 "Request ";
VAL_ 724 APA_ReleasePressureReq 0 " No Request" 1 "Request";
VAL_ 724 APA_LAEBNotice 0 "Off" 1 "On" 2 "Reminding" 3 "Braking" 4 "Failure" 4 "Reserve";
VAL_ 724 APA_LAEBStatus 0 "Off" 1 "Standby" 2 "Unavailable" 3 "Active" 4 "Brake" 5 "ReFault" 6 "Fault" 7 "Reserve";
VAL_ 724 APA_ParkNotice_5 0 " IDLE" 1 " 'Search Slot" 2 "Stop the car" 3 " Parking Modeselection" 4 " Fasten seat belts for driver_park in" 5 " Close the door_parkin" 6 " No Standstill Brake_park in" 7 " PMO chose ELS auto mode" 8 "Brake and Long_Button" 9 " Rele_Bra_Park" 10 " Parking in" 11 " Park insuspend ACC pedal pressed" 12 " Park in suspend Handle Gear shift" 13 "parkin suspend Driver seatbelt unfastened" 14 "Park in suspend Door open" 15 "Park in suspend EPB ON" 16 " Park in suspend resume" 17 "Parking system error" 18 "Successful Park in" 19 "PMO slot too big" 20 "PMO slot too small" 21 "PMO side selection" 22 "PMO suspend Handle Gear Shift" 23 "Fasten seat belts_park out" 24 " Close the door_park out" 25 " PMOchose ELS auto mode" 26 "FP4U button longpressed and braking check" 27 " Start PMO Release Brake" 28 "Parking out" 29 " PMO suspend ACCpadel pressed" 30 " PMO suspend Gear change" 31 " PMO suspend driverseat belt unfastened" 32 " PMO suspend door open" 33 " PMO suspend EPBON" 34 " Park out resume" 35 "Parking canceled" 36 " Park off speed toofast" 37 " successful PMO" 38 " Speed too high please slow down" 39 "Slot search off speed too high" 40 " Remote Parking active" 41 " forwardremote parking" 42 " backward remote parking" 43 " remote Parkingfinish" 44 "EPS  functional limitation" 45 "EMS  functional limitation" 46 "ESP functional limitation" 47 "ESL functional limitation" 48 "Smartphone Remote Parking in active" 49 "Smartphone Remote Parking out on" 50 "Smartphone Remote Parking in on" 51 "smartphone Remote Parking out active" 52 "Slope too high function cancel" 53 "vehicle not standstill" 54 "Gear not P" 55 "EPB not clamp" 56 "Handshake failed" 57 "Remote parking use hints" 58 "Start engine" 59 "Search Slot by rerverse gear" 60 "System Cancel Object Tracked" 61 "Cancle_ACCMode" 62 "Shift Gear to D" 63 "ASP Failed for Over Distance" 64 "ASP Failed for Over Time" 65 "ASP Failed for User Takeover" 66 "Active suspension" 67 "Passive suspension" 68 "Passive suspension renew" 69 "Remote parking start" 70 "Remote parking on" 71 "Remote parking key use hints" 72 "PlsSelectParkingSlot" 73 "RemoteParkingUseRecommend" 74 "System Resume Object Tracked" 75 "System Cancel Insufficient Space" 76 "Key Longpressed Resume" 77 "" 78 "APP Parking Abnormal End" 79 "4G Remote parking on������4G״̬OK���ҷ��Ͻ��̴��Ͳ���������" 80 "APP Remote parking Suspend" 81 "Key Remote parking Suspend" 82 "APP Remote parking Success" 83 "Key Remote parking Success" 84 "APP Remote parking Cancel" 85 "Key Remote parking Cancel" 86 "Illegal interface" 87 "System Cancel Network Delay" 88 "Left Steering" 89 "Right Steering" 90 "SteeringReturn" 91 "FurthestForward" 92 "FurthestBackward" 93 "Maximum Angle of SteeringLeft" 94 "Maximum Angle of SteeringRight" 95 "Not in Geo-fence" 96 "Life in the Car" 97 "Tutorialmodel" 98 "Reserved" 99 "Reserved" 100 "RMA function downgrade" 101 "Reseved" 102 "Whether to park in" 103 "CPOC Side Selection" 104 "CPOC BackOut Side Selection" 105 "Furthest ForwardRemoteParking" 106 "Furthest BackwardRemoteParking" 107 "Release the brake" 108 "Parking Cancle DriverInterruption; 0x6D=Parking Cancle System Timeout; 0x6E=Parking Suspend Pedestrian tracked; 0x6F=Parking Suspend Vehicle tracked; 0x70=Parking Cancel SteeringInterruption;0x71=Parking Cancel ShifterInterruption;0x72-0x7F=Reserved";

VAL_ 734 IP_WholeTermClrFlg 0 "No Reset" 1 "Reset";
VAL_ 734 IP_DriverLCDALEDSts 0 "No Error" 1 "Error";
VAL_ 734 IP_PassengerLCDALEDSts 0 "No Error" 1 "Error";
VAL_ 734 IP_DISFail 0 "no error" 1 "error";
VAL_ 734 IP_QDashACCFail 0 "no error" 1 "error" 2 "reserved" 3 "reserved";

VAL_ 742 EMS_InhbParallel 0 "������" 1 "��ֹ����";
VAL_ 742 EMS_EngStartFailRestSts 0 "FLASE" 1 "TURE";
VAL_ 742 EMS_WarmUpCycle 1 "achieved" 0 "not achieved";
VAL_ 742 EMS_LoBattErr 1 "Error," 0 "No error";
VAL_ 742 EMS_IgnitionCyclesCounterValid 0 "valid" 1 "Invalid";
VAL_ 742 EMS_GeneralDenoStatusValid 0 "valid" 1 "Invalid";
VAL_ 742 EMS_DrivingCycle 1 "achieved" 0 "not achieved";
VAL_ 742 EMS_CooltTErr 0 "No error" 1 "Error";
VAL_ 742 EMS_CatalystWarmUp 1 "request." 0 "not request";
VAL_ 742 EMS_AltitudeFactorValid 0 "Valid" 1 "NotValid";

VAL_ 753 PCU_VINDataN5 48 "0" 49 "1" 50 "2" 51 "3" 52 "4" 53 "5" 54 "6" 55 "7" 56 "8" 57 "9" 65 "A" 66 "B" 67 "C" 68 "D" 69 "E" 70 "F" 71 "G" 72 "H" 73 "I" 74 "J" 75 "K" 76 "L" 77 "M" 78 "N" 79 "O" 80 "P" 81 "Q" 82 "R" 83 "S" 84 "T" 85 "U" 86 "V" 87 "W" 88 "X" 89 "Y" 90 "Z";
VAL_ 753 PCU_VINDataN4 48 "0" 49 "1" 50 "2" 51 "3" 52 "4" 53 "5" 54 "6" 55 "7" 56 "8" 57 "9" 65 "A" 66 "B" 67 "C" 68 "D" 69 "E" 70 "F" 71 "G" 72 "H" 73 "I" 74 "J" 75 "K" 76 "L" 77 "M" 78 "N" 79 "O" 80 "P" 81 "Q" 82 "R" 83 "S" 84 "T" 85 "U" 86 "V" 87 "W" 88 "X" 89 "Y" 90 "Z";
VAL_ 753 PCU_VINDataN3 48 "0" 49 "1" 50 "2" 51 "3" 52 "4" 53 "5" 54 "6" 55 "7" 56 "8" 57 "9" 65 "A" 66 "B" 67 "C" 68 "D" 69 "E" 70 "F" 71 "G" 72 "H" 73 "I" 74 "J" 75 "K" 76 "L" 77 "M" 78 "N" 79 "O" 80 "P" 81 "Q" 82 "R" 83 "S" 84 "T" 85 "U" 86 "V" 87 "W" 88 "X" 89 "Y" 90 "Z";
VAL_ 753 PCU_VINDataN2 48 "0" 49 "1" 50 "2" 51 "3" 52 "4" 53 "5" 54 "6" 55 "7" 56 "8" 57 "9" 65 "A" 66 "B" 67 "C" 68 "D" 69 "E" 70 "F" 71 "G" 72 "H" 73 "I" 74 "J" 75 "K" 76 "L" 77 "M" 78 "N" 79 "O" 80 "P" 81 "Q" 82 "R" 83 "S" 84 "T" 85 "U" 86 "V" 87 "W" 88 "X" 89 "Y" 90 "Z";
VAL_ 753 PCU_VINDataN1 48 "0" 49 "1" 50 "2" 51 "3" 52 "4" 53 "5" 54 "6" 55 "7" 56 "8" 57 "9" 65 "A" 66 "B" 67 "C" 68 "D" 69 "E" 70 "F" 71 "G" 72 "H" 73 "I" 74 "J" 75 "K" 76 "L" 77 "M" 78 "N" 79 "O" 80 "P" 81 "Q" 82 "R" 83 "S" 84 "T" 85 "U" 86 "V" 87 "W" 88 "X" 89 "Y" 90 "Z";
VAL_ 753 PCU_VINDataN 48 "0" 49 "1" 50 "2" 51 "3" 52 "4" 53 "5" 54 "6" 55 "7" 56 "8" 57 "9" 65 "A" 66 "B" 67 "C" 68 "D" 69 "E" 70 "F" 71 "G" 72 "H" 73 "I" 74 "J" 75 "K" 76 "L" 77 "M" 78 "N" 79 "O" 80 "P" 81 "Q" 82 "R" 83 "S" 84 "T" 85 "U" 86 "V" 87 "W" 88 "X" 89 "Y" 90 "Z";

VAL_ 758 HU_V2LBattLoEngStrReq 0 "No Request" 1 "Disable" 2 "Enable" 3 "Reserved";
VAL_ 758 HU_ChrgStrtStopReq 0 "No request" 1 "Charge start" 2 "Charge stop";
VAL_ 758 HU_IndirectTPMSReset 0 "No request" 1 "Request";

VAL_ 812 TMS_Heater_pump_Spd_Req 0 "Inactive" 1 "0~100%" 102 "Reserved" 127 "invalid";
VAL_ 812 TMS_Motor_pump_Spd_Req 0 "Inactive" 1 "0~100%" 102 "Reserved" 127 "invalid";
VAL_ 812 TMS_WarmLoopSts 0 "OFF" 1 "Normal" 2 "warning" 3 "Failure";
VAL_ 812 TMS_OperMod 0 "Initializing" 1 "Standby" 2 "HV cooling active" 3 "afterrun" 4 "Failure" 5 "ready to shut down" 6 "BattHeatSftyCoolingMod";
VAL_ 812 TMS_Motor_pump_Actv 0 "Not active" 1 "Active";
VAL_ 812 TMS_MotCoolngLoopSts 0 "OFF" 1 "Normal" 2 "warning" 3 "Failure";
VAL_ 812 TMS_IntercolerLoopSts 0 "OFF" 1 "Normal" 2 "warning" 3 "Failure";
VAL_ 812 TMS_IntecoolerpumpActv 0 "Not active" 1 "Active";
VAL_ 812 TMS_Heater_valveSts 0 "A side" 1 "B side";
VAL_ 812 TMS_Evap_valveSts 0 "Not active" 1 "Active";
VAL_ 812 TMS_EngEnableReq 0 "No request" 1 "Request engine start";
VAL_ 812 TMS_CoolingFanSts 0 "OFF " 1 "10_Percent" 2 "20_Percent" 3 "30_Percent" 4 "40_Percent" 5 "50_Percent" 6 "60_Percent" 7 "70_Percent" 8 "80_Percent" 9 "90_Percent" 10 "Full_ON" 15 "Not_Used  ";
VAL_ 812 TMS_BpumpActv 0 "Not active" 1 "Active";
VAL_ 812 TMS_BCoolActv 0 "Not active" 1 "Active";
VAL_ 812 TMS_BattCoolngLoopSts 0 "OFF" 1 "Normal" 2 "warning" 3 "Failure";
VAL_ 812 TMS_PEU_pump_Spd_Req 0 "Inactive" 1 "0~100%" 102 "Reserved" 127 "invalid";
VAL_ 812 TMS_RaceModSwSts 0 "No press" 1 "press";
